VERSION ""

NS_ :

BS_:

BU_:

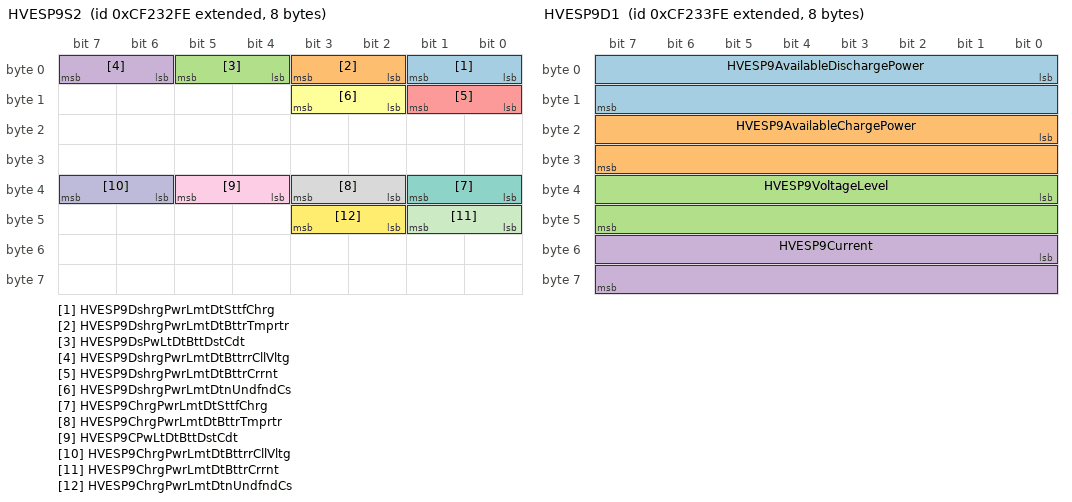
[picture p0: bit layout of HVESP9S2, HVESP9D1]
BO_ 2364683006 HVESP9S2: 8 Vector__XXX
 SG_ HVESP9DshrgPwrLmtDtSttfChrg : 0|2@1+ (1,0) [0|3] "" Vector__XXX
 SG_ HVESP9DshrgPwrLmtDtBttrTmprtr : 2|2@1+ (1,0) [0|3] "" Vector__XXX
 SG_ HVESP9DsPwLtDtBttDstCdt : 4|2@1+ (1,0) [0|3] "" Vector__XXX
 SG_ HVESP9DshrgPwrLmtDtBttrrCllVltg : 6|2@1+ (1,0) [0|3] "" Vector__XXX
 SG_ HVESP9DshrgPwrLmtDtBttrCrrnt : 8|2@1+ (1,0) [0|3] "" Vector__XXX
 SG_ HVESP9DshrgPwrLmtDtnUndfndCs : 10|2@1+ (1,0) [0|3] "" Vector__XXX
 SG_ HVESP9ChrgPwrLmtDtSttfChrg : 32|2@1+ (1,0) [0|3] "" Vector__XXX
 SG_ HVESP9ChrgPwrLmtDtBttrTmprtr : 34|2@1+ (1,0) [0|3] "" Vector__XXX
 SG_ HVESP9CPwLtDtBttDstCdt : 36|2@1+ (1,0) [0|3] "" Vector__XXX
 SG_ HVESP9ChrgPwrLmtDtBttrrCllVltg : 38|2@1+ (1,0) [0|3] "" Vector__XXX
 SG_ HVESP9ChrgPwrLmtDtBttrCrrnt : 40|2@1+ (1,0) [0|3] "" Vector__XXX
 SG_ HVESP9ChrgPwrLmtDtnUndfndCs : 42|2@1+ (1,0) [0|3] "" Vector__XXX

BO_ 2364683262 HVESP9D1: 8 Vector__XXX
 SG_ HVESP9AvailableDischargePower : 0|16@1+ (0.05,0) [0|3212.75] "kW" Vector__XXX
 SG_ HVESP9AvailableChargePower : 16|16@1+ (0.05,0) [0|3212.75] "kW" Vector__XXX
 SG_ HVESP9VoltageLevel : 32|16@1+ (0.05,0) [0|3212.75] "V" Vector__XXX
 SG_ HVESP9Current : 48|16@1+ (0.05,-1600) [-1600|1612.75] "A" Vector__XXX

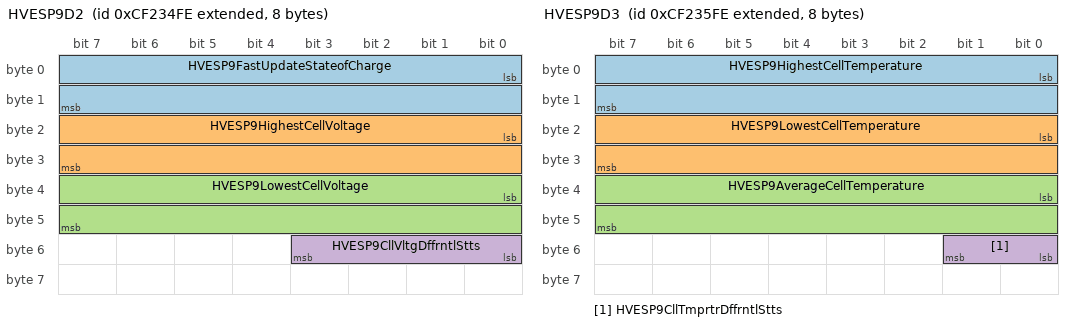
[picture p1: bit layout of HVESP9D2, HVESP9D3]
BO_ 2364683518 HVESP9D2: 8 Vector__XXX
 SG_ HVESP9FastUpdateStateofCharge : 0|16@1+ (0.0015625,0) [0|100.3984375] "%" Vector__XXX
 SG_ HVESP9HighestCellVoltage : 16|16@1+ (0.001,0) [0|64.255] "V" Vector__XXX
 SG_ HVESP9LowestCellVoltage : 32|16@1+ (0.001,0) [0|64.255] "V" Vector__XXX
 SG_ HVESP9CllVltgDffrntlStts : 48|4@1+ (1,0) [0|15] "" Vector__XXX

BO_ 2364683774 HVESP9D3: 8 Vector__XXX
 SG_ HVESP9HighestCellTemperature : 0|16@1+ (0.03125,-273) [-273|1734.96875] "degC" Vector__XXX
 SG_ HVESP9LowestCellTemperature : 16|16@1+ (0.03125,-273) [-273|1734.96875] "degC" Vector__XXX
 SG_ HVESP9AverageCellTemperature : 32|16@1+ (0.03125,-273) [-273|1734.96875] "degC" Vector__XXX
 SG_ HVESP9CllTmprtrDffrntlStts : 48|2@1+ (1,0) [0|3] "" Vector__XXX

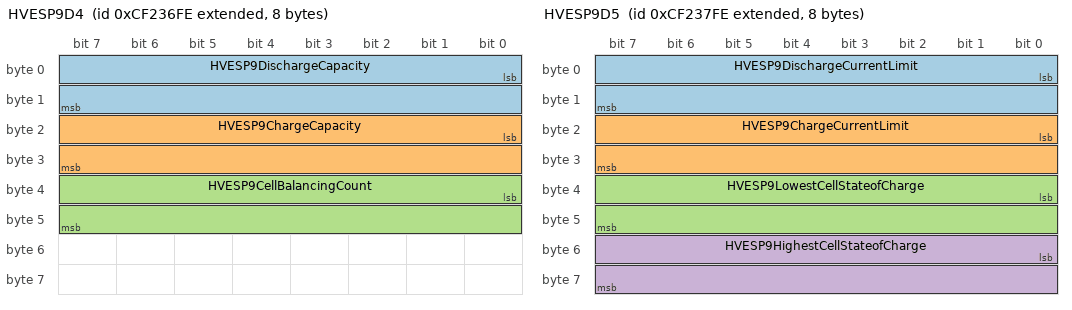
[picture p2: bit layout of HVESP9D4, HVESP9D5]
BO_ 2364684030 HVESP9D4: 8 Vector__XXX
 SG_ HVESP9DischargeCapacity : 0|16@1+ (0.01,0) [0|642.55] "Ah" Vector__XXX
 SG_ HVESP9ChargeCapacity : 16|16@1+ (0.01,0) [0|642.55] "Ah" Vector__XXX
 SG_ HVESP9CellBalancingCount : 32|16@1+ (1,0) [0|64255] "count" Vector__XXX

BO_ 2364684286 HVESP9D5: 8 Vector__XXX
 SG_ HVESP9DischargeCurrentLimit : 0|16@1+ (0.05,-1600) [-1600|1612.75] "A" Vector__XXX
 SG_ HVESP9ChargeCurrentLimit : 16|16@1+ (0.05,-1600) [-1600|1612.75] "A" Vector__XXX
 SG_ HVESP9LowestCellStateofCharge : 32|16@1+ (0.0015625,0) [0|100.3984375] "%" Vector__XXX
 SG_ HVESP9HighestCellStateofCharge : 48|16@1+ (0.0015625,0) [0|100.3984375] "%" Vector__XXX

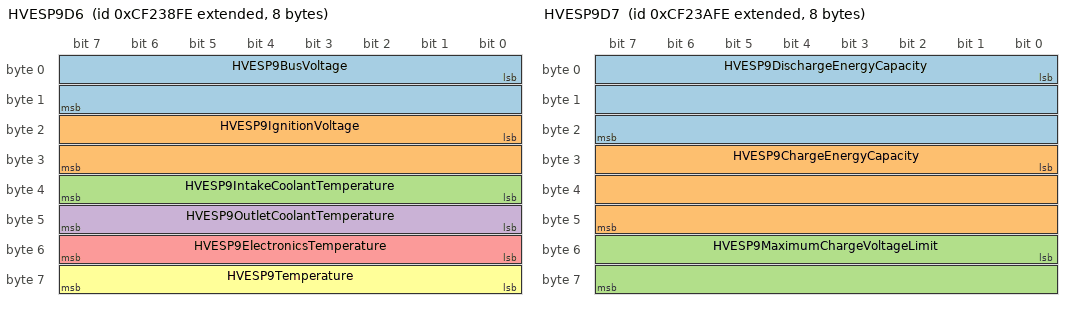
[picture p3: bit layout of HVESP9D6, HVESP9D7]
BO_ 2364684542 HVESP9D6: 8 Vector__XXX
 SG_ HVESP9BusVoltage : 0|16@1+ (0.05,0) [0|3212.75] "V" Vector__XXX
 SG_ HVESP9IgnitionVoltage : 16|16@1+ (0.01,0) [0|642.55] "V" Vector__XXX
 SG_ HVESP9IntakeCoolantTemperature : 32|8@1+ (1,-40) [-40|210] "degC" Vector__XXX
 SG_ HVESP9OutletCoolantTemperature : 40|8@1+ (1,-40) [-40|210] "degC" Vector__XXX
 SG_ HVESP9ElectronicsTemperature : 48|8@1+ (1,-40) [-40|210] "degC" Vector__XXX
 SG_ HVESP9Temperature : 56|8@1+ (1,-40) [-40|210] "degC" Vector__XXX

BO_ 2364684798 HVESP9S1: 8 Vector__XXX
 SG_ HVESP9HghVltgBsPstvCnttrStt : 0|2@1+ (1,0) [0|3] "" Vector__XXX
 SG_ HVESP9HghVltgBsNgtvCnttrStt : 2|2@1+ (1,0) [0|3] "" Vector__XXX
 SG_ HVESP9HghVltgBsDsnntFrwrnng : 4|4@1+ (1,0) [0|15] "" Vector__XXX
 SG_ HVESP9HghVltgBsPrChrgRlStt : 8|2@1+ (1,0) [0|3] "" Vector__XXX
 SG_ HVESP9CntrfPkCnttrStt : 10|2@1+ (1,0) [0|3] "" Vector__XXX
 SG_ HVESP9HghVltgBsAtvIsltnTstStts : 12|4@1+ (1,0) [0|15] "" Vector__XXX
 SG_ HVESP9HghVltgBsPssvIsltnTstStts : 16|4@1+ (1,0) [0|15] "" Vector__XXX
 SG_ HVESP9HVILStatus : 20|2@1+ (1,0) [0|3] "" Vector__XXX
 SG_ HVESP9InertiaSwitchStatus : 22|2@1+ (1,0) [0|3] "" Vector__XXX
 SG_ HVESP9StateofChargeStatus : 24|4@1+ (1,0) [0|15] "" Vector__XXX
 SG_ HVESP9CellBalanceStatus : 28|2@1+ (1,0) [0|3] "" Vector__XXX
 SG_ HVESP9CellBalancingActive : 30|2@1+ (1,0) [0|3] "" Vector__XXX
 SG_ HVESP9InternalChargerStatus : 32|2@1+ (1,0) [0|3] "" Vector__XXX
 SG_ HVESP9HghVltgBsCnntnStts : 40|4@1+ (1,0) [0|15] "" Vector__XXX
 SG_ HVESP9OperationalStatus : 44|4@1+ (1,0) [0|15] "" Vector__XXX
 SG_ HVESP9Status1Counter : 52|4@1+ (1,0) [0|15] "" Vector__XXX
 SG_ HVESP9Status1CRC : 56|8@1+ (1,0) [0|255] "count" Vector__XXX

BO_ 2364685054 HVESP9D7: 8 Vector__XXX
 SG_ HVESP9DischargeEnergyCapacity : 0|24@1+ (0.001,0) [0|16449.535] "kWh" Vector__XXX
 SG_ HVESP9ChargeEnergyCapacity : 24|24@1+ (0.001,0) [0|16449.535] "kWh" Vector__XXX
 SG_ HVESP9MaximumChargeVoltageLimit : 48|16@1+ (0.05,0) [0|3212.75] "V" Vector__XXX

BO_ 2364685310 HVESP9MS1: 8 Vector__XXX
 SG_ HVESP9Module1OperationalStatus : 0|2@1+ (1,0) [0|3] "" Vector__XXX
 SG_ HVESP9Module2OperationalStatus : 2|2@1+ (1,0) [0|3] "" Vector__XXX
 SG_ HVESP9Module3OperationalStatus : 4|2@1+ (1,0) [0|3] "" Vector__XXX
 SG_ HVESP9Module4OperationalStatus : 6|2@1+ (1,0) [0|3] "" Vector__XXX
 SG_ HVESP9Module5OperationalStatus : 8|2@1+ (1,0) [0|3] "" Vector__XXX
 SG_ HVESP9Module6OperationalStatus : 10|2@1+ (1,0) [0|3] "" Vector__XXX
 SG_ HVESP9Module7OperationalStatus : 12|2@1+ (1,0) [0|3] "" Vector__XXX
 SG_ HVESP9Module8OperationalStatus : 14|2@1+ (1,0) [0|3] "" Vector__XXX
 SG_ HVESP9Module9OperationalStatus : 16|2@1+ (1,0) [0|3] "" Vector__XXX
 SG_ HVESP9Module10OperationalStatus : 18|2@1+ (1,0) [0|3] "" Vector__XXX
 SG_ HVESP9Module11OperationalStatus : 20|2@1+ (1,0) [0|3] "" Vector__XXX
 SG_ HVESP9Module12OperationalStatus : 22|2@1+ (1,0) [0|3] "" Vector__XXX
 SG_ HVESP9Module13OperationalStatus : 24|2@1+ (1,0) [0|3] "" Vector__XXX
 SG_ HVESP9Module14OperationalStatus : 26|2@1+ (1,0) [0|3] "" Vector__XXX
 SG_ HVESP9Module15OperationalStatus : 28|2@1+ (1,0) [0|3] "" Vector__XXX
 SG_ HVESP9Module16OperationalStatus : 30|2@1+ (1,0) [0|3] "" Vector__XXX
 SG_ HVESP9Module17OperationalStatus : 32|2@1+ (1,0) [0|3] "" Vector__XXX
 SG_ HVESP9Module18OperationalStatus : 34|2@1+ (1,0) [0|3] "" Vector__XXX
 SG_ HVESP9Module19OperationalStatus : 36|2@1+ (1,0) [0|3] "" Vector__XXX
 SG_ HVESP9Module20OperationalStatus : 38|2@1+ (1,0) [0|3] "" Vector__XXX
 SG_ HVESP9Module21OperationalStatus : 40|2@1+ (1,0) [0|3] "" Vector__XXX
 SG_ HVESP9Module22OperationalStatus : 42|2@1+ (1,0) [0|3] "" Vector__XXX
 SG_ HVESP9Module23OperationalStatus : 44|2@1+ (1,0) [0|3] "" Vector__XXX
 SG_ HVESP9Module24OperationalStatus : 46|2@1+ (1,0) [0|3] "" Vector__XXX
 SG_ HVESP9Module25OperationalStatus : 48|2@1+ (1,0) [0|3] "" Vector__XXX
 SG_ HVESP9Module26OperationalStatus : 50|2@1+ (1,0) [0|3] "" Vector__XXX
 SG_ HVESP9Module27OperationalStatus : 52|2@1+ (1,0) [0|3] "" Vector__XXX
 SG_ HVESP9Module28OperationalStatus : 54|2@1+ (1,0) [0|3] "" Vector__XXX
 SG_ HVESP9Module29OperationalStatus : 56|2@1+ (1,0) [0|3] "" Vector__XXX
 SG_ HVESP9Module30OperationalStatus : 58|2@1+ (1,0) [0|3] "" Vector__XXX
 SG_ HVESP9Module31OperationalStatus : 60|2@1+ (1,0) [0|3] "" Vector__XXX
 SG_ HVESP9Module32OperationalStatus : 62|2@1+ (1,0) [0|3] "" Vector__XXX

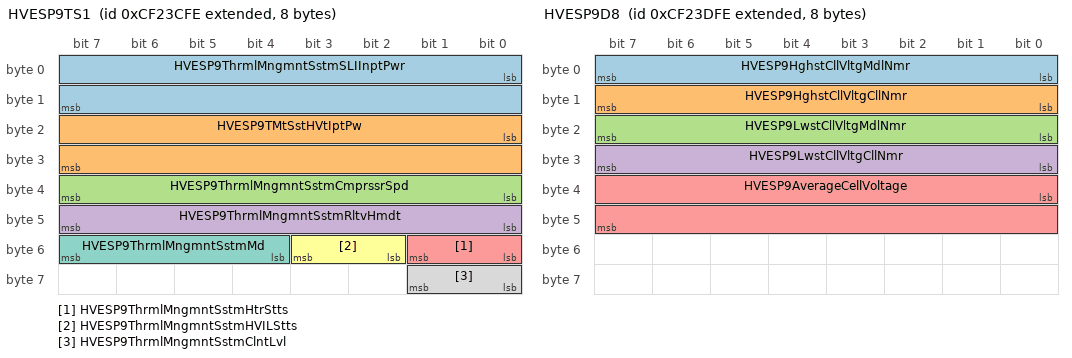
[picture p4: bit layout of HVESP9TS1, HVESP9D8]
BO_ 2364685566 HVESP9TS1: 8 Vector__XXX
 SG_ HVESP9ThrmlMngmntSstmSLIInptPwr : 0|16@1+ (0.5,0) [0|32127.5] "W" Vector__XXX
 SG_ HVESP9TMtSstHVtIptPw : 16|16@1+ (0.5,0) [0|32127.5] "W" Vector__XXX
 SG_ HVESP9ThrmlMngmntSstmCmprssrSpd : 32|8@1+ (32,0) [0|8000] "rpm" Vector__XXX
 SG_ HVESP9ThrmlMngmntSstmRltvHmdt : 40|8@1+ (0.4,0) [0|100] "%" Vector__XXX
 SG_ HVESP9ThrmlMngmntSstmHtrStts : 48|2@1+ (1,0) [0|3] "" Vector__XXX
 SG_ HVESP9ThrmlMngmntSstmHVILStts : 50|2@1+ (1,0) [0|3] "" Vector__XXX
 SG_ HVESP9ThrmlMngmntSstmMd : 52|4@1+ (1,0) [0|15] "" Vector__XXX
 SG_ HVESP9ThrmlMngmntSstmClntLvl : 56|2@1+ (1,0) [0|3] "" Vector__XXX

BO_ 2364685822 HVESP9D8: 8 Vector__XXX
 SG_ HVESP9HghstCllVltgMdlNmr : 0|8@1+ (1,0) [0|250] "count" Vector__XXX
 SG_ HVESP9HghstCllVltgCllNmr : 8|8@1+ (1,0) [0|250] "count" Vector__XXX
 SG_ HVESP9LwstCllVltgMdlNmr : 16|8@1+ (1,0) [0|250] "count" Vector__XXX
 SG_ HVESP9LwstCllVltgCllNmr : 24|8@1+ (1,0) [0|250] "count" Vector__XXX
 SG_ HVESP9AverageCellVoltage : 32|16@1+ (0.001,0) [0|64.255] "V" Vector__XXX

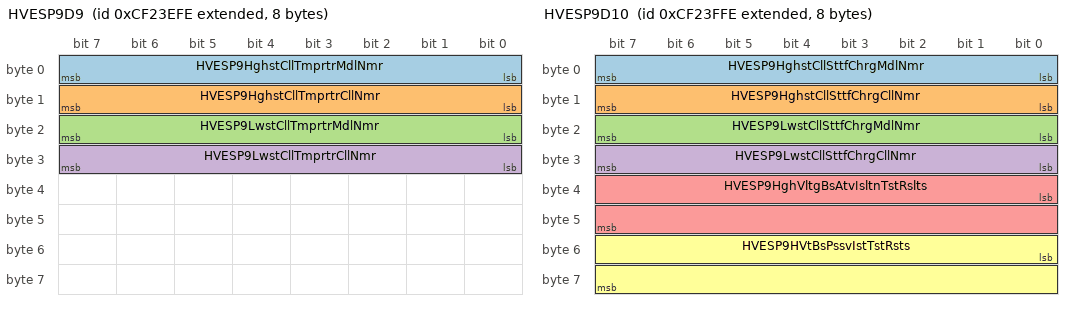
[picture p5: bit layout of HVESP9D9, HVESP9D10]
BO_ 2364686078 HVESP9D9: 8 Vector__XXX
 SG_ HVESP9HghstCllTmprtrMdlNmr : 0|8@1+ (1,0) [0|250] "count" Vector__XXX
 SG_ HVESP9HghstCllTmprtrCllNmr : 8|8@1+ (1,0) [0|250] "count" Vector__XXX
 SG_ HVESP9LwstCllTmprtrMdlNmr : 16|8@1+ (1,0) [0|250] "count" Vector__XXX
 SG_ HVESP9LwstCllTmprtrCllNmr : 24|8@1+ (1,0) [0|250] "count" Vector__XXX

BO_ 2364686334 HVESP9D10: 8 Vector__XXX
 SG_ HVESP9HghstCllSttfChrgMdlNmr : 0|8@1+ (1,0) [0|250] "count" Vector__XXX
 SG_ HVESP9HghstCllSttfChrgCllNmr : 8|8@1+ (1,0) [0|250] "count" Vector__XXX
 SG_ HVESP9LwstCllSttfChrgMdlNmr : 16|8@1+ (1,0) [0|250] "count" Vector__XXX
 SG_ HVESP9LwstCllSttfChrgCllNmr : 24|8@1+ (1,0) [0|250] "count" Vector__XXX
 SG_ HVESP9HghVltgBsAtvIsltnTstRslts : 32|16@1+ (0.1,0) [0|6425.5] "ohm/V" Vector__XXX
 SG_ HVESP9HVtBsPssvIstTstRsts : 48|16@1+ (0.1,0) [0|6425.5] "ohm/V" Vector__XXX

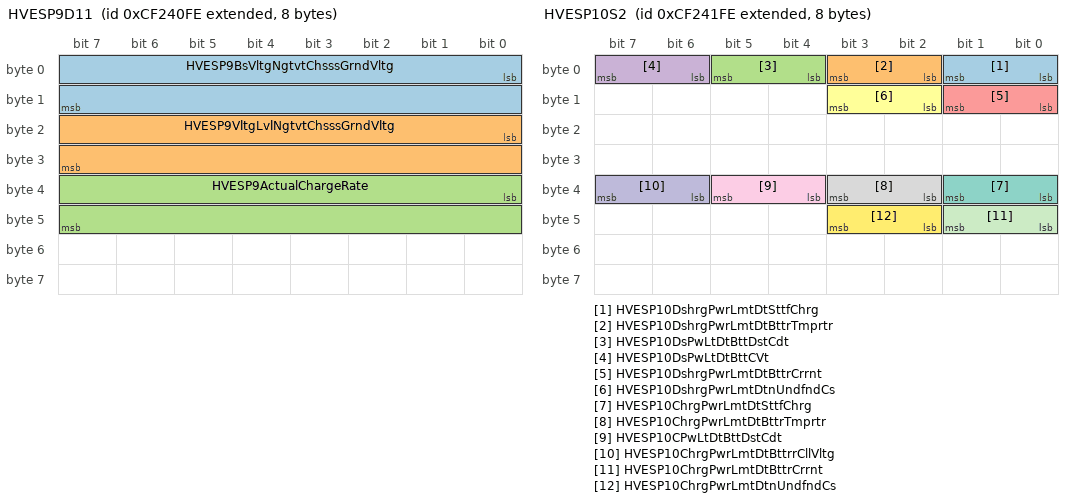
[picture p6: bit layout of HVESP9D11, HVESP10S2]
BO_ 2364686590 HVESP9D11: 8 Vector__XXX
 SG_ HVESP9BsVltgNgtvtChsssGrndVltg : 0|16@1+ (0.05,0) [0|3212.75] "V" Vector__XXX
 SG_ HVESP9VltgLvlNgtvtChsssGrndVltg : 16|16@1+ (0.05,0) [0|3212.75] "V" Vector__XXX
 SG_ HVESP9ActualChargeRate : 32|16@1+ (0.05,0) [0|3212.75] "kW" Vector__XXX

BO_ 2364686846 HVESP10S2: 8 Vector__XXX
 SG_ HVESP10DshrgPwrLmtDtSttfChrg : 0|2@1+ (1,0) [0|3] "" Vector__XXX
 SG_ HVESP10DshrgPwrLmtDtBttrTmprtr : 2|2@1+ (1,0) [0|3] "" Vector__XXX
 SG_ HVESP10DsPwLtDtBttDstCdt : 4|2@1+ (1,0) [0|3] "" Vector__XXX
 SG_ HVESP10DsPwLtDtBttCVt : 6|2@1+ (1,0) [0|3] "" Vector__XXX
 SG_ HVESP10DshrgPwrLmtDtBttrCrrnt : 8|2@1+ (1,0) [0|3] "" Vector__XXX
 SG_ HVESP10DshrgPwrLmtDtnUndfndCs : 10|2@1+ (1,0) [0|3] "" Vector__XXX
 SG_ HVESP10ChrgPwrLmtDtSttfChrg : 32|2@1+ (1,0) [0|3] "" Vector__XXX
 SG_ HVESP10ChrgPwrLmtDtBttrTmprtr : 34|2@1+ (1,0) [0|3] "" Vector__XXX
 SG_ HVESP10CPwLtDtBttDstCdt : 36|2@1+ (1,0) [0|3] "" Vector__XXX
 SG_ HVESP10ChrgPwrLmtDtBttrrCllVltg : 38|2@1+ (1,0) [0|3] "" Vector__XXX
 SG_ HVESP10ChrgPwrLmtDtBttrCrrnt : 40|2@1+ (1,0) [0|3] "" Vector__XXX
 SG_ HVESP10ChrgPwrLmtDtnUndfndCs : 42|2@1+ (1,0) [0|3] "" Vector__XXX

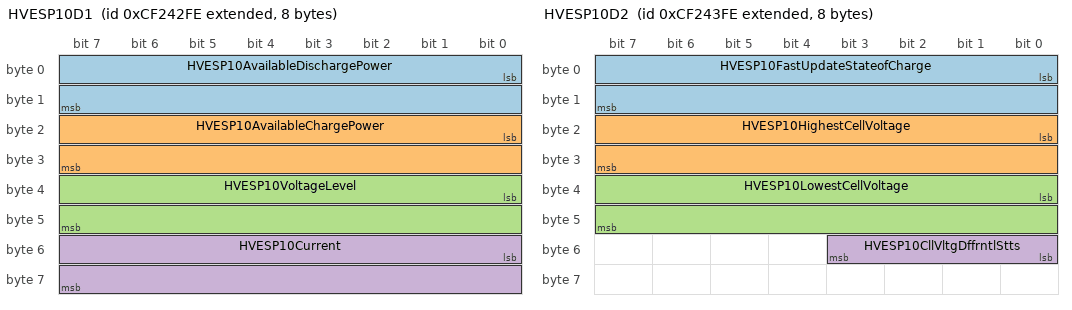
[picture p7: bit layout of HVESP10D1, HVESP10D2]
BO_ 2364687102 HVESP10D1: 8 Vector__XXX
 SG_ HVESP10AvailableDischargePower : 0|16@1+ (0.05,0) [0|3212.75] "kW" Vector__XXX
 SG_ HVESP10AvailableChargePower : 16|16@1+ (0.05,0) [0|3212.75] "kW" Vector__XXX
 SG_ HVESP10VoltageLevel : 32|16@1+ (0.05,0) [0|3212.75] "V" Vector__XXX
 SG_ HVESP10Current : 48|16@1+ (0.05,-1600) [-1600|1612.75] "A" Vector__XXX

BO_ 2364687358 HVESP10D2: 8 Vector__XXX
 SG_ HVESP10FastUpdateStateofCharge : 0|16@1+ (0.0015625,0) [0|100.3984375] "%" Vector__XXX
 SG_ HVESP10HighestCellVoltage : 16|16@1+ (0.001,0) [0|64.255] "V" Vector__XXX
 SG_ HVESP10LowestCellVoltage : 32|16@1+ (0.001,0) [0|64.255] "V" Vector__XXX
 SG_ HVESP10CllVltgDffrntlStts : 48|4@1+ (1,0) [0|15] "" Vector__XXX

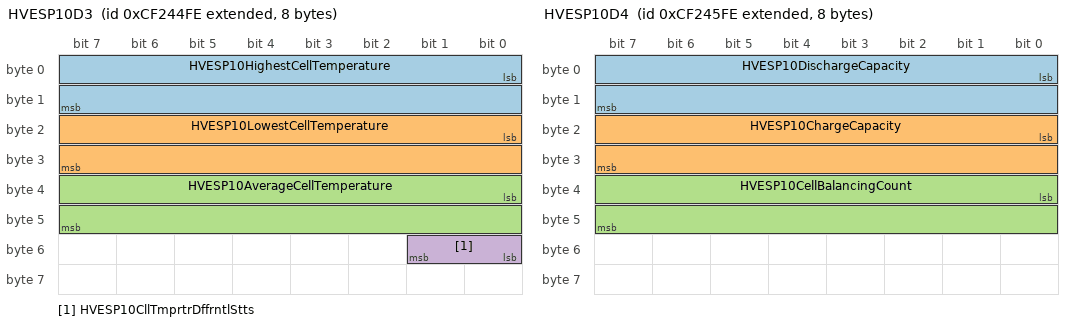
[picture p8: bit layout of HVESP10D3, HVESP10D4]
BO_ 2364687614 HVESP10D3: 8 Vector__XXX
 SG_ HVESP10HighestCellTemperature : 0|16@1+ (0.03125,-273) [-273|1734.96875] "degC" Vector__XXX
 SG_ HVESP10LowestCellTemperature : 16|16@1+ (0.03125,-273) [-273|1734.96875] "degC" Vector__XXX
 SG_ HVESP10AverageCellTemperature : 32|16@1+ (0.03125,-273) [-273|1734.96875] "degC" Vector__XXX
 SG_ HVESP10CllTmprtrDffrntlStts : 48|2@1+ (1,0) [0|3] "" Vector__XXX

BO_ 2364687870 HVESP10D4: 8 Vector__XXX
 SG_ HVESP10DischargeCapacity : 0|16@1+ (0.01,0) [0|642.55] "Ah" Vector__XXX
 SG_ HVESP10ChargeCapacity : 16|16@1+ (0.01,0) [0|642.55] "Ah" Vector__XXX
 SG_ HVESP10CellBalancingCount : 32|16@1+ (1,0) [0|64255] "count" Vector__XXX

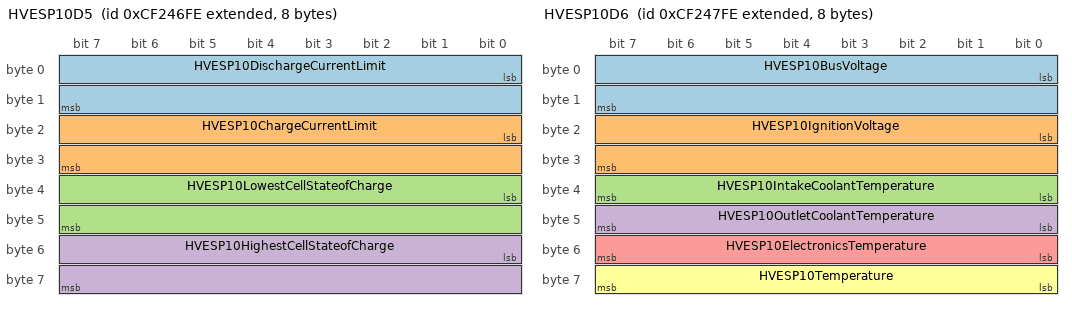
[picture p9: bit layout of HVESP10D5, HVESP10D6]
BO_ 2364688126 HVESP10D5: 8 Vector__XXX
 SG_ HVESP10DischargeCurrentLimit : 0|16@1+ (0.05,-1600) [-1600|1612.75] "A" Vector__XXX
 SG_ HVESP10ChargeCurrentLimit : 16|16@1+ (0.05,-1600) [-1600|1612.75] "A" Vector__XXX
 SG_ HVESP10LowestCellStateofCharge : 32|16@1+ (0.0015625,0) [0|100.3984375] "%" Vector__XXX
 SG_ HVESP10HighestCellStateofCharge : 48|16@1+ (0.0015625,0) [0|100.3984375] "%" Vector__XXX

BO_ 2364688382 HVESP10D6: 8 Vector__XXX
 SG_ HVESP10BusVoltage : 0|16@1+ (0.05,0) [0|3212.75] "V" Vector__XXX
 SG_ HVESP10IgnitionVoltage : 16|16@1+ (0.01,0) [0|642.55] "V" Vector__XXX
 SG_ HVESP10IntakeCoolantTemperature : 32|8@1+ (1,-40) [-40|210] "degC" Vector__XXX
 SG_ HVESP10OutletCoolantTemperature : 40|8@1+ (1,-40) [-40|210] "degC" Vector__XXX
 SG_ HVESP10ElectronicsTemperature : 48|8@1+ (1,-40) [-40|210] "degC" Vector__XXX
 SG_ HVESP10Temperature : 56|8@1+ (1,-40) [-40|210] "degC" Vector__XXX

BO_ 2364688638 HVESP10S1: 8 Vector__XXX
 SG_ HVESP10HghVltgBsPstvCnttrStt : 0|2@1+ (1,0) [0|3] "" Vector__XXX
 SG_ HVESP10HghVltgBsNgtvCnttrStt : 2|2@1+ (1,0) [0|3] "" Vector__XXX
 SG_ HVESP10HghVltgBsDsnntFrwrnng : 4|4@1+ (1,0) [0|15] "" Vector__XXX
 SG_ HVESP10HghVltgBsPrChrgRlStt : 8|2@1+ (1,0) [0|3] "" Vector__XXX
 SG_ HVESP10CntrfPkCnttrStt : 10|2@1+ (1,0) [0|3] "" Vector__XXX
 SG_ HVESP10HghVltgBsAtvIsltnTstStts : 12|4@1+ (1,0) [0|15] "" Vector__XXX
 SG_ HVESP10HVtBsPssvIstTstStts : 16|4@1+ (1,0) [0|15] "" Vector__XXX
 SG_ HVESP10HVILStatus : 20|2@1+ (1,0) [0|3] "" Vector__XXX
 SG_ HVESP10InertiaSwitchStatus : 22|2@1+ (1,0) [0|3] "" Vector__XXX
 SG_ HVESP10StateofChargeStatus : 24|4@1+ (1,0) [0|15] "" Vector__XXX
 SG_ HVESP10CellBalanceStatus : 28|2@1+ (1,0) [0|3] "" Vector__XXX
 SG_ HVESP10CellBalancingActive : 30|2@1+ (1,0) [0|3] "" Vector__XXX
 SG_ HVESP10InternalChargerStatus : 32|2@1+ (1,0) [0|3] "" Vector__XXX
 SG_ HVESP10HghVltgBsCnntnStts : 40|4@1+ (1,0) [0|15] "" Vector__XXX
 SG_ HVESP10OperationalStatus : 44|4@1+ (1,0) [0|15] "" Vector__XXX
 SG_ HVESP10Status1Counter : 52|4@1+ (1,0) [0|15] "" Vector__XXX
 SG_ HVESP10Status1CRC : 56|8@1+ (1,0) [0|255] "count" Vector__XXX

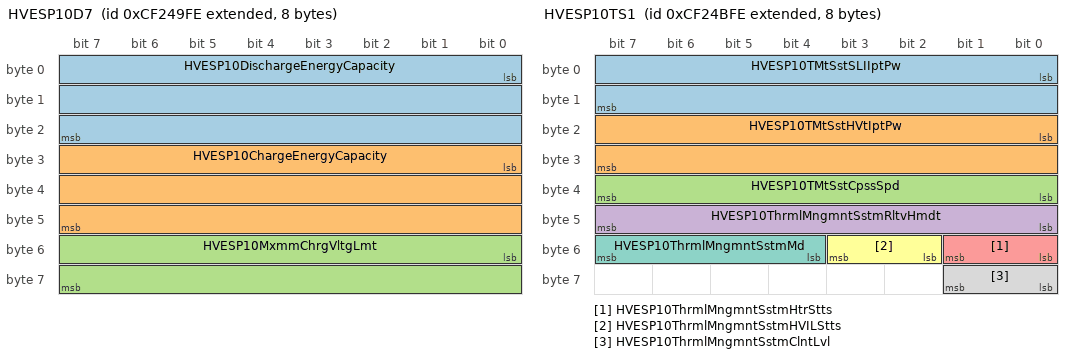
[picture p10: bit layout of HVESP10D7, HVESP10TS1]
BO_ 2364688894 HVESP10D7: 8 Vector__XXX
 SG_ HVESP10DischargeEnergyCapacity : 0|24@1+ (0.001,0) [0|16449.535] "kWh" Vector__XXX
 SG_ HVESP10ChargeEnergyCapacity : 24|24@1+ (0.001,0) [0|16449.535] "kWh" Vector__XXX
 SG_ HVESP10MxmmChrgVltgLmt : 48|16@1+ (0.05,0) [0|3212.75] "V" Vector__XXX

BO_ 2364689150 HVESP10MS1: 8 Vector__XXX
 SG_ HVESP10Module1OperationalStatus : 0|2@1+ (1,0) [0|3] "" Vector__XXX
 SG_ HVESP10Module2OperationalStatus : 2|2@1+ (1,0) [0|3] "" Vector__XXX
 SG_ HVESP10Module3OperationalStatus : 4|2@1+ (1,0) [0|3] "" Vector__XXX
 SG_ HVESP10Module4OperationalStatus : 6|2@1+ (1,0) [0|3] "" Vector__XXX
 SG_ HVESP10Module5OperationalStatus : 8|2@1+ (1,0) [0|3] "" Vector__XXX
 SG_ HVESP10Module6OperationalStatus : 10|2@1+ (1,0) [0|3] "" Vector__XXX
 SG_ HVESP10Module7OperationalStatus : 12|2@1+ (1,0) [0|3] "" Vector__XXX
 SG_ HVESP10Module8OperationalStatus : 14|2@1+ (1,0) [0|3] "" Vector__XXX
 SG_ HVESP10Module9OperationalStatus : 16|2@1+ (1,0) [0|3] "" Vector__XXX
 SG_ HVESP10Mdl10OprtnlStts : 18|2@1+ (1,0) [0|3] "" Vector__XXX
 SG_ HVESP10Mdl11OprtnlStts : 20|2@1+ (1,0) [0|3] "" Vector__XXX
 SG_ HVESP10Mdl12OprtnlStts : 22|2@1+ (1,0) [0|3] "" Vector__XXX
 SG_ HVESP10Mdl13OprtnlStts : 24|2@1+ (1,0) [0|3] "" Vector__XXX
 SG_ HVESP10Mdl14OprtnlStts : 26|2@1+ (1,0) [0|3] "" Vector__XXX
 SG_ HVESP10Mdl15OprtnlStts : 28|2@1+ (1,0) [0|3] "" Vector__XXX
 SG_ HVESP10Mdl16OprtnlStts : 30|2@1+ (1,0) [0|3] "" Vector__XXX
 SG_ HVESP10Mdl17OprtnlStts : 32|2@1+ (1,0) [0|3] "" Vector__XXX
 SG_ HVESP10Mdl18OprtnlStts : 34|2@1+ (1,0) [0|3] "" Vector__XXX
 SG_ HVESP10Mdl19OprtnlStts : 36|2@1+ (1,0) [0|3] "" Vector__XXX
 SG_ HVESP10Mdl20OprtnlStts : 38|2@1+ (1,0) [0|3] "" Vector__XXX
 SG_ HVESP10Mdl21OprtnlStts : 40|2@1+ (1,0) [0|3] "" Vector__XXX
 SG_ HVESP10Mdl22OprtnlStts : 42|2@1+ (1,0) [0|3] "" Vector__XXX
 SG_ HVESP10Mdl23OprtnlStts : 44|2@1+ (1,0) [0|3] "" Vector__XXX
 SG_ HVESP10Mdl24OprtnlStts : 46|2@1+ (1,0) [0|3] "" Vector__XXX
 SG_ HVESP10Mdl25OprtnlStts : 48|2@1+ (1,0) [0|3] "" Vector__XXX
 SG_ HVESP10Mdl26OprtnlStts : 50|2@1+ (1,0) [0|3] "" Vector__XXX
 SG_ HVESP10Mdl27OprtnlStts : 52|2@1+ (1,0) [0|3] "" Vector__XXX
 SG_ HVESP10Mdl28OprtnlStts : 54|2@1+ (1,0) [0|3] "" Vector__XXX
 SG_ HVESP10Mdl29OprtnlStts : 56|2@1+ (1,0) [0|3] "" Vector__XXX
 SG_ HVESP10Mdl30OprtnlStts : 58|2@1+ (1,0) [0|3] "" Vector__XXX
 SG_ HVESP10Mdl31OprtnlStts : 60|2@1+ (1,0) [0|3] "" Vector__XXX
 SG_ HVESP10Mdl32OprtnlStts : 62|2@1+ (1,0) [0|3] "" Vector__XXX

BO_ 2364689406 HVESP10TS1: 8 Vector__XXX
 SG_ HVESP10TMtSstSLIIptPw : 0|16@1+ (0.5,0) [0|32127.5] "W" Vector__XXX
 SG_ HVESP10TMtSstHVtIptPw : 16|16@1+ (0.5,0) [0|32127.5] "W" Vector__XXX
 SG_ HVESP10TMtSstCpssSpd : 32|8@1+ (32,0) [0|8000] "rpm" Vector__XXX
 SG_ HVESP10ThrmlMngmntSstmRltvHmdt : 40|8@1+ (0.4,0) [0|100] "%" Vector__XXX
 SG_ HVESP10ThrmlMngmntSstmHtrStts : 48|2@1+ (1,0) [0|3] "" Vector__XXX
 SG_ HVESP10ThrmlMngmntSstmHVILStts : 50|2@1+ (1,0) [0|3] "" Vector__XXX
 SG_ HVESP10ThrmlMngmntSstmMd : 52|4@1+ (1,0) [0|15] "" Vector__XXX
 SG_ HVESP10ThrmlMngmntSstmClntLvl : 56|2@1+ (1,0) [0|3] "" Vector__XXX

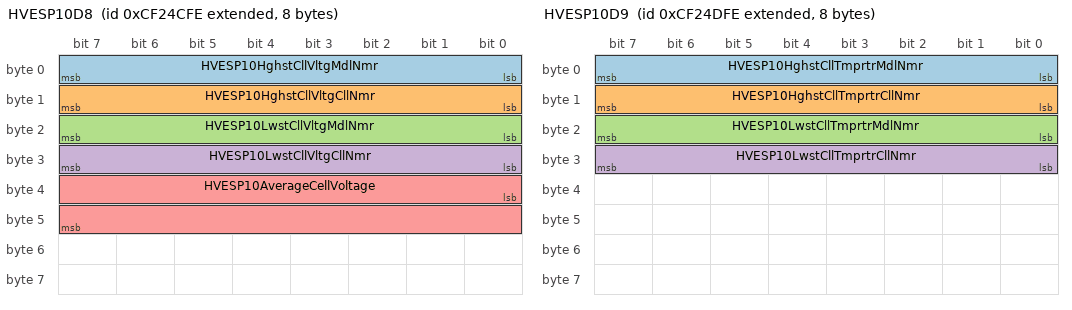
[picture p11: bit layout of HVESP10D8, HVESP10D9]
BO_ 2364689662 HVESP10D8: 8 Vector__XXX
 SG_ HVESP10HghstCllVltgMdlNmr : 0|8@1+ (1,0) [0|250] "count" Vector__XXX
 SG_ HVESP10HghstCllVltgCllNmr : 8|8@1+ (1,0) [0|250] "count" Vector__XXX
 SG_ HVESP10LwstCllVltgMdlNmr : 16|8@1+ (1,0) [0|250] "count" Vector__XXX
 SG_ HVESP10LwstCllVltgCllNmr : 24|8@1+ (1,0) [0|250] "count" Vector__XXX
 SG_ HVESP10AverageCellVoltage : 32|16@1+ (0.001,0) [0|64.255] "V" Vector__XXX

BO_ 2364689918 HVESP10D9: 8 Vector__XXX
 SG_ HVESP10HghstCllTmprtrMdlNmr : 0|8@1+ (1,0) [0|250] "count" Vector__XXX
 SG_ HVESP10HghstCllTmprtrCllNmr : 8|8@1+ (1,0) [0|250] "count" Vector__XXX
 SG_ HVESP10LwstCllTmprtrMdlNmr : 16|8@1+ (1,0) [0|250] "count" Vector__XXX
 SG_ HVESP10LwstCllTmprtrCllNmr : 24|8@1+ (1,0) [0|250] "count" Vector__XXX

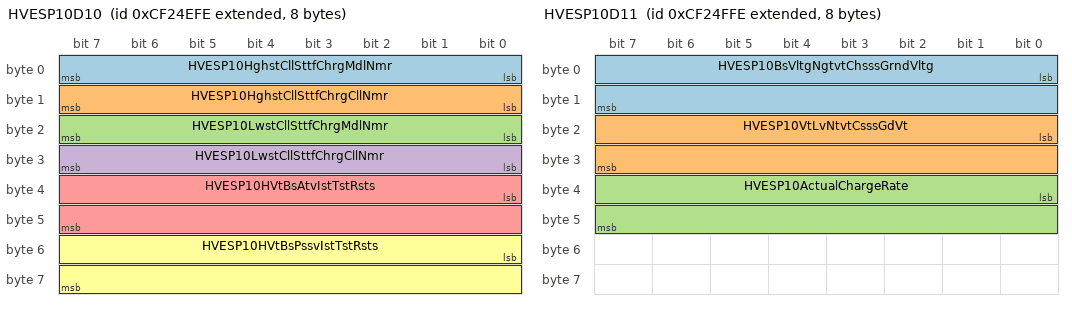
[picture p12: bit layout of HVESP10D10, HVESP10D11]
BO_ 2364690174 HVESP10D10: 8 Vector__XXX
 SG_ HVESP10HghstCllSttfChrgMdlNmr : 0|8@1+ (1,0) [0|250] "count" Vector__XXX
 SG_ HVESP10HghstCllSttfChrgCllNmr : 8|8@1+ (1,0) [0|250] "count" Vector__XXX
 SG_ HVESP10LwstCllSttfChrgMdlNmr : 16|8@1+ (1,0) [0|250] "count" Vector__XXX
 SG_ HVESP10LwstCllSttfChrgCllNmr : 24|8@1+ (1,0) [0|250] "count" Vector__XXX
 SG_ HVESP10HVtBsAtvIstTstRsts : 32|16@1+ (0.1,0) [0|6425.5] "ohm/V" Vector__XXX
 SG_ HVESP10HVtBsPssvIstTstRsts : 48|16@1+ (0.1,0) [0|6425.5] "ohm/V" Vector__XXX

BO_ 2364690430 HVESP10D11: 8 Vector__XXX
 SG_ HVESP10BsVltgNgtvtChsssGrndVltg : 0|16@1+ (0.05,0) [0|3212.75] "V" Vector__XXX
 SG_ HVESP10VtLvNtvtCsssGdVt : 16|16@1+ (0.05,0) [0|3212.75] "V" Vector__XXX
 SG_ HVESP10ActualChargeRate : 32|16@1+ (0.05,0) [0|3212.75] "kW" Vector__XXX

BO_ 2566564862 HVESP10CFG: 16 Vector__XXX
 SG_ HVESP10NominalVoltage : 0|16@1+ (0.05,0) [0|3212.75] "V" Vector__XXX
 SG_ HVESP10RmmnddMnmmOprtngVltg : 16|16@1+ (0.05,0) [0|3212.75] "V" Vector__XXX
 SG_ HVESP10RmmnddMxmmOprtngVltg : 32|16@1+ (0.05,0) [0|3212.75] "V" Vector__XXX
 SG_ HVESP10RmmnddMnmmSttOfChrg : 48|16@1+ (0.0015625,0) [0|100.3984375] "%" Vector__XXX
 SG_ HVESP10RmmnddMxmmSttOfChrg : 64|16@1+ (0.0015625,0) [0|100.3984375] "%" Vector__XXX
 SG_ HVESP10RmmnddMxmmOprtngTmprtr : 80|16@1+ (0.03125,-273) [-273|1734.96875] "degC" Vector__XXX
 SG_ HVESP10RmmnddMnmmOprtngTmprtr : 96|16@1+ (0.03125,-273) [-273|1734.96875] "degC" Vector__XXX
 SG_ HVESP10CellMaximumVoltageLimit : 112|8@1+ (0.02044,0) [0|5.11] "V" Vector__XXX
 SG_ HVESP10CellMinimumVoltageLimit : 120|8@1+ (0.02044,0) [0|5.11] "V" Vector__XXX

BO_ 2633673982 HVESP10HIST: 19 Vector__XXX
 SG_ HVESP10StateofHealth : 0|8@1+ (0.4,0) [0|100] "%" Vector__XXX
 SG_ HVESP10CnttrOpnUndrLdCnt : 8|16@1+ (1,0) [0|64255] "count" Vector__XXX
 SG_ HVESP10TotalEnergyThroughput : 24|32@1+ (100,0) [0|421108121500] "Watt-hour" Vector__XXX
 SG_ HVESP10TotalAccumulatedCharge : 56|32@1+ (100,0) [0|421108121500] "Ah" Vector__XXX
 SG_ HVESP10TotalLifetimeEnergyInput : 88|32@1+ (1,0) [0|4211081215] "kWh" Vector__XXX
 SG_ HVESP10TtlLftmEnrgOtpt : 120|32@1+ (1,0) [0|4211081215] "kWh" Vector__XXX

BO_ 2566565374 HVESP9CFG: 16 Vector__XXX
 SG_ HVESP9NominalVoltage : 0|16@1+ (0.05,0) [0|3212.75] "V" Vector__XXX
 SG_ HVESP9RmmnddMnmmOprtngVltg : 16|16@1+ (0.05,0) [0|3212.75] "V" Vector__XXX
 SG_ HVESP9RmmnddMxmmOprtngVltg : 32|16@1+ (0.05,0) [0|3212.75] "V" Vector__XXX
 SG_ HVESP9RmmnddMnmmSttOfChrg : 48|16@1+ (0.0015625,0) [0|100.3984375] "%" Vector__XXX
 SG_ HVESP9RmmnddMxmmSttOfChrg : 64|16@1+ (0.0015625,0) [0|100.3984375] "%" Vector__XXX
 SG_ HVESP9RmmnddMxmmOprtngTmprtr : 80|16@1+ (0.03125,-273) [-273|1734.96875] "degC" Vector__XXX
 SG_ HVESP9RmmnddMnmmOprtngTmprtr : 96|16@1+ (0.03125,-273) [-273|1734.96875] "degC" Vector__XXX
 SG_ HVESP9CellMaximumVoltageLimit : 112|8@1+ (0.02044,0) [0|5.11] "V" Vector__XXX
 SG_ HVESP9CellMinimumVoltageLimit : 120|8@1+ (0.02044,0) [0|5.11] "V" Vector__XXX

BO_ 2633674494 HVESP9HIST: 19 Vector__XXX
 SG_ HVESP9StateofHealth : 0|8@1+ (0.4,0) [0|100] "%" Vector__XXX
 SG_ HVESP9CnttrOpnUndrLdCnt : 8|16@1+ (1,0) [0|64255] "count" Vector__XXX
 SG_ HVESP9TotalEnergyThroughput : 24|32@1+ (100,0) [0|421108121500] "Watt-hour" Vector__XXX
 SG_ HVESP9TotalAccumulatedCharge : 56|32@1+ (100,0) [0|421108121500] "Ah" Vector__XXX
 SG_ HVESP9TotalLifetimeEnergyInput : 88|32@1+ (1,0) [0|4211081215] "kWh" Vector__XXX
 SG_ HVESP9TotalLifetimeEnergyOutput : 120|32@1+ (1,0) [0|4211081215] "kWh" Vector__XXX

BO_ 2566565886 HVESP8CFG: 16 Vector__XXX
 SG_ HVESP8NominalVoltage : 0|16@1+ (0.05,0) [0|3212.75] "V" Vector__XXX
 SG_ HVESP8RmmnddMnmmOprtngVltg : 16|16@1+ (0.05,0) [0|3212.75] "V" Vector__XXX
 SG_ HVESP8RmmnddMxmmOprtngVltg : 32|16@1+ (0.05,0) [0|3212.75] "V" Vector__XXX
 SG_ HVESP8RmmnddMnmmSttOfChrg : 48|16@1+ (0.0015625,0) [0|100.3984375] "%" Vector__XXX
 SG_ HVESP8RmmnddMxmmSttOfChrg : 64|16@1+ (0.0015625,0) [0|100.3984375] "%" Vector__XXX
 SG_ HVESP8RmmnddMxmmOprtngTmprtr : 80|16@1+ (0.03125,-273) [-273|1734.96875] "degC" Vector__XXX
 SG_ HVESP8RmmnddMnmmOprtngTmprtr : 96|16@1+ (0.03125,-273) [-273|1734.96875] "degC" Vector__XXX
 SG_ HVESP8CellMaximumVoltageLimit : 112|8@1+ (0.02044,0) [0|5.11] "V" Vector__XXX
 SG_ HVESP8CellMinimumVoltageLimit : 120|8@1+ (0.02044,0) [0|5.11] "V" Vector__XXX

BO_ 2633675006 HVESP8HIST: 19 Vector__XXX
 SG_ HVESP8StateofHealth : 0|8@1+ (0.4,0) [0|100] "%" Vector__XXX
 SG_ HVESP8CnttrOpnUndrLdCnt : 8|16@1+ (1,0) [0|64255] "count" Vector__XXX
 SG_ HVESP8TotalEnergyThroughput : 24|32@1+ (100,0) [0|421108121500] "Watt-hour" Vector__XXX
 SG_ HVESP8TotalAccumulatedCharge : 56|32@1+ (100,0) [0|421108121500] "Ah" Vector__XXX
 SG_ HVESP8TotalLifetimeEnergyInput : 88|32@1+ (1,0) [0|4211081215] "kWh" Vector__XXX
 SG_ HVESP8TotalLifetimeEnergyOutput : 120|32@1+ (1,0) [0|4211081215] "kWh" Vector__XXX

BO_ 2566566398 HVESP7CFG: 16 Vector__XXX
 SG_ HVESP7NominalVoltage : 0|16@1+ (0.05,0) [0|3212.75] "V" Vector__XXX
 SG_ HVESP7RmmnddMnmmOprtngVltg : 16|16@1+ (0.05,0) [0|3212.75] "V" Vector__XXX
 SG_ HVESP7RmmnddMxmmOprtngVltg : 32|16@1+ (0.05,0) [0|3212.75] "V" Vector__XXX
 SG_ HVESP7RmmnddMnmmSttOfChrg : 48|16@1+ (0.0015625,0) [0|100.3984375] "%" Vector__XXX
 SG_ HVESP7RmmnddMxmmSttOfChrg : 64|16@1+ (0.0015625,0) [0|100.3984375] "%" Vector__XXX
 SG_ HVESP7RmmnddMxmmOprtngTmprtr : 80|16@1+ (0.03125,-273) [-273|1734.96875] "degC" Vector__XXX
 SG_ HVESP7RmmnddMnmmOprtngTmprtr : 96|16@1+ (0.03125,-273) [-273|1734.96875] "degC" Vector__XXX
 SG_ HVESP7CellMaximumVoltageLimit : 112|8@1+ (0.02044,0) [0|5.11] "V" Vector__XXX
 SG_ HVESP7CellMinimumVoltageLimit : 120|8@1+ (0.02044,0) [0|5.11] "V" Vector__XXX

BO_ 2633675518 HVESP7HIST: 19 Vector__XXX
 SG_ HVESP7StateofHealth : 0|8@1+ (0.4,0) [0|100] "%" Vector__XXX
 SG_ HVESP7CnttrOpnUndrLdCnt : 8|16@1+ (1,0) [0|64255] "count" Vector__XXX
 SG_ HVESP7TotalEnergyThroughput : 24|32@1+ (100,0) [0|421108121500] "Watt-hour" Vector__XXX
 SG_ HVESP7TotalAccumulatedCharge : 56|32@1+ (100,0) [0|421108121500] "Ah" Vector__XXX
 SG_ HVESP7TotalLifetimeEnergyInput : 88|32@1+ (1,0) [0|4211081215] "kWh" Vector__XXX
 SG_ HVESP7TotalLifetimeEnergyOutput : 120|32@1+ (1,0) [0|4211081215] "kWh" Vector__XXX

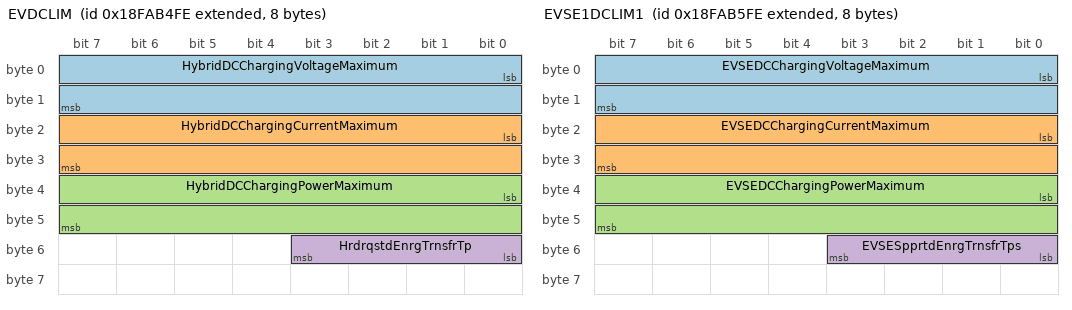
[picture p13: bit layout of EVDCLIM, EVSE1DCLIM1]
BO_ 2566567166 EVDCLIM: 8 Vector__XXX
 SG_ HybridDCChargingVoltageMaximum : 0|16@1+ (0.05,0) [0|3212.75] "V" Vector__XXX
 SG_ HybridDCChargingCurrentMaximum : 16|16@1+ (0.0625,0) [0|4015.9375] "A" Vector__XXX
 SG_ HybridDCChargingPowerMaximum : 32|16@1+ (0.05,0) [0|3212.75] "kW" Vector__XXX
 SG_ HrdrqstdEnrgTrnsfrTp : 48|4@1+ (1,0) [0|15] "" Vector__XXX

BO_ 2566567422 EVSE1DCLIM1: 8 Vector__XXX
 SG_ EVSEDCChargingVoltageMaximum : 0|16@1+ (0.05,0) [0|3212.75] "V" Vector__XXX
 SG_ EVSEDCChargingCurrentMaximum : 16|16@1+ (0.0625,0) [0|4015.9375] "A" Vector__XXX
 SG_ EVSEDCChargingPowerMaximum : 32|16@1+ (0.05,0) [0|3212.75] "kW" Vector__XXX
 SG_ EVSESpprtdEnrgTrnsfrTps : 48|4@1+ (1,0) [0|15] "" Vector__XXX

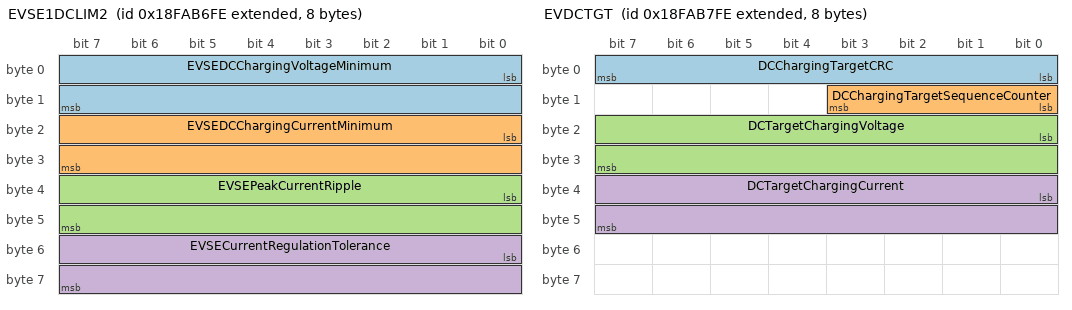
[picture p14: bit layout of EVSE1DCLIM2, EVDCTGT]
BO_ 2566567678 EVSE1DCLIM2: 8 Vector__XXX
 SG_ EVSEDCChargingVoltageMinimum : 0|16@1+ (0.05,0) [0|3212.75] "V" Vector__XXX
 SG_ EVSEDCChargingCurrentMinimum : 16|16@1+ (0.0625,0) [0|4015.9375] "A" Vector__XXX
 SG_ EVSEPeakCurrentRipple : 32|16@1+ (0.0625,0) [0|4015.9375] "A" Vector__XXX
 SG_ EVSECurrentRegulationTolerance : 48|16@1+ (0.0625,0) [0|4015.9375] "A" Vector__XXX

BO_ 2566567934 EVDCTGT: 8 Vector__XXX
 SG_ DCChargingTargetCRC : 0|8@1+ (1,0) [0|255] "count" Vector__XXX
 SG_ DCChargingTargetSequenceCounter : 8|4@1+ (1,0) [0|15] "" Vector__XXX
 SG_ DCTargetChargingVoltage : 16|16@1+ (0.05,0) [0|3212.75] "V" Vector__XXX
 SG_ DCTargetChargingCurrent : 32|16@1+ (0.0625,0) [0|4015.9375] "A" Vector__XXX

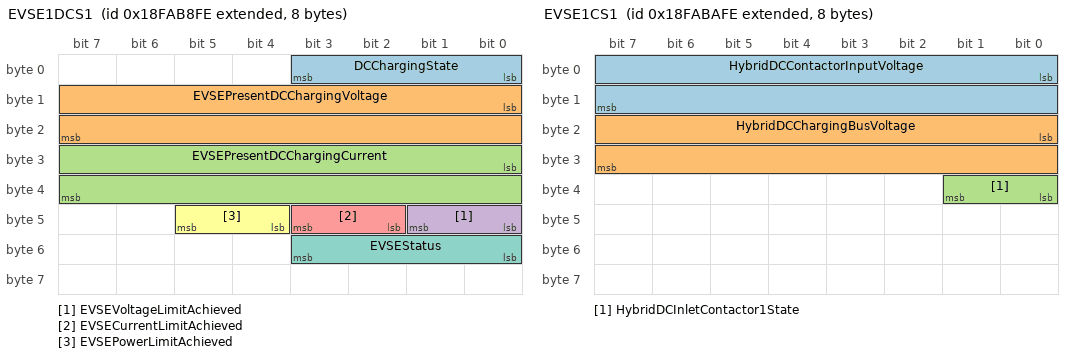
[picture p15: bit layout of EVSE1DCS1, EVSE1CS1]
BO_ 2566568190 EVSE1DCS1: 8 Vector__XXX
 SG_ DCChargingState : 0|4@1+ (1,0) [0|15] "" Vector__XXX
 SG_ EVSEPresentDCChargingVoltage : 8|16@1+ (0.05,0) [0|3212.75] "V" Vector__XXX
 SG_ EVSEPresentDCChargingCurrent : 24|16@1+ (0.05,-1600) [-1600|1612.75] "A" Vector__XXX
 SG_ EVSEVoltageLimitAchieved : 40|2@1+ (1,0) [0|3] "" Vector__XXX
 SG_ EVSECurrentLimitAchieved : 42|2@1+ (1,0) [0|3] "" Vector__XXX
 SG_ EVSEPowerLimitAchieved : 44|2@1+ (1,0) [0|3] "" Vector__XXX
 SG_ EVSEStatus : 48|4@1+ (1,0) [0|15] "" Vector__XXX

BO_ 2566568446 EVSE1CC1: 8 Vector__XXX
 SG_ HybridDCInletContactor1Command : 0|2@1+ (1,0) [0|3] "" Vector__XXX

BO_ 2566568702 EVSE1CS1: 8 Vector__XXX
 SG_ HybridDCContactorInputVoltage : 0|16@1+ (0.05,0) [0|3212.75] "V" Vector__XXX
 SG_ HybridDCChargingBusVoltage : 16|16@1+ (0.05,0) [0|3212.75] "V" Vector__XXX
 SG_ HybridDCInletContactor1State : 32|2@1+ (1,0) [0|3] "" Vector__XXX

BO_ 2566568958 DLCC3: 8 Vector__XXX
 SG_ TrnsmssnOlTmprtrHghLmpCmmnd : 0|2@1+ (1,0) [0|3] "" Vector__XXX
 SG_ TrnsmssnOlPrssrLwLmpCmmnd : 2|2@1+ (1,0) [0|3] "" Vector__XXX

BO_ 2566569214 DLCD3: 8 Vector__XXX
 SG_ TrnsmssnOlTmprtrHghLmpDt : 0|2@1+ (1,0) [0|3] "" Vector__XXX
 SG_ TrnsmssnOlPrssrLwLmpDt : 2|2@1+ (1,0) [0|3] "" Vector__XXX

BO_ 2566569470 MG1LD: 16 Vector__XXX
 SG_ MtrGnrtr1TtlEnrgCnsmd : 0|32@1+ (100,0) [0|421108121500] "Watt-hour" Vector__XXX
 SG_ MtrGnrtr1TtlEnrgGnrtd : 32|32@1+ (100,0) [0|421108121500] "Watt-hour" Vector__XXX
 SG_ MtrGnrtr1TtlChrgCnsmd : 64|32@1+ (100,0) [0|421108121500] "Ah" Vector__XXX
 SG_ MtrGnrtr1TtlChrgGnrtd : 96|32@1+ (100,0) [0|421108121500] "Ah" Vector__XXX

BO_ 2566569726 MG2LD: 16 Vector__XXX
 SG_ MtrGnrtr2TtlEnrgCnsmd : 0|32@1+ (100,0) [0|421108121500] "Watt-hour" Vector__XXX
 SG_ MtrGnrtr2TtlEnrgGnrtd : 32|32@1+ (100,0) [0|421108121500] "Watt-hour" Vector__XXX
 SG_ MtrGnrtr2TtlChrgCnsmd : 64|32@1+ (100,0) [0|421108121500] "Ah" Vector__XXX
 SG_ MtrGnrtr2TtlChrgGnrtd : 96|32@1+ (100,0) [0|421108121500] "Ah" Vector__XXX

BO_ 2566569982 MG3LD: 16 Vector__XXX
 SG_ MtrGnrtr3TtlEnrgCnsmd : 0|32@1+ (100,0) [0|421108121500] "Watt-hour" Vector__XXX
 SG_ MtrGnrtr3TtlEnrgGnrtd : 32|32@1+ (100,0) [0|421108121500] "Watt-hour" Vector__XXX
 SG_ MtrGnrtr3TtlChrgCnsmd : 64|32@1+ (100,0) [0|421108121500] "Ah" Vector__XXX
 SG_ MtrGnrtr3TtlChrgGnrtd : 96|32@1+ (100,0) [0|421108121500] "Ah" Vector__XXX

BO_ 2566570238 MG4LD: 16 Vector__XXX
 SG_ MtrGnrtr4TtlEnrgCnsmd : 0|32@1+ (100,0) [0|421108121500] "Watt-hour" Vector__XXX
 SG_ MtrGnrtr4TtlEnrgGnrtd : 32|32@1+ (100,0) [0|421108121500] "Watt-hour" Vector__XXX
 SG_ MtrGnrtr4TtlChrgCnsmd : 64|32@1+ (100,0) [0|421108121500] "Ah" Vector__XXX
 SG_ MtrGnrtr4TtlChrgGnrtd : 96|32@1+ (100,0) [0|421108121500] "Ah" Vector__XXX

BO_ 2566570494 MG5LD: 16 Vector__XXX
 SG_ MtrGnrtr5TtlEnrgCnsmd : 0|32@1+ (100,0) [0|421108121500] "Watt-hour" Vector__XXX
 SG_ MtrGnrtr5TtlEnrgGnrtd : 32|32@1+ (100,0) [0|421108121500] "Watt-hour" Vector__XXX
 SG_ MtrGnrtr5TtlChrgCnsmd : 64|32@1+ (100,0) [0|421108121500] "Ah" Vector__XXX
 SG_ MtrGnrtr5TtlChrgGnrtd : 96|32@1+ (100,0) [0|421108121500] "Ah" Vector__XXX

BO_ 2566570750 MG6LD: 16 Vector__XXX
 SG_ MtrGnrtr6TtlEnrgCnsmd : 0|32@1+ (100,0) [0|421108121500] "Watt-hour" Vector__XXX
 SG_ MtrGnrtr6TtlEnrgGnrtd : 32|32@1+ (100,0) [0|421108121500] "Watt-hour" Vector__XXX
 SG_ MtrGnrtr6TtlChrgCnsmd : 64|32@1+ (100,0) [0|421108121500] "Ah" Vector__XXX
 SG_ MtrGnrtr6TtlChrgGnrtd : 96|32@1+ (100,0) [0|421108121500] "Ah" Vector__XXX

BO_ 2566571006 AIR3: 8 Vector__XXX
 SG_ AirDryerCartridgeLifeRemaining : 0|8@1+ (0.4,0) [0|100] "%" Vector__XXX
 SG_ AirSuspensionSupplyPressure2 : 8|8@1+ (8,0) [0|2000] "kPa" Vector__XXX

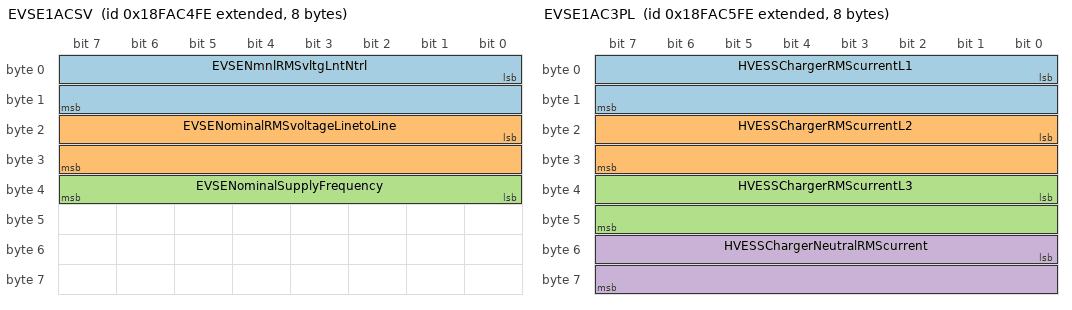
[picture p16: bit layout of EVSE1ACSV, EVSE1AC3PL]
BO_ 2566571262 EVSE1ACSV: 8 Vector__XXX
 SG_ EVSENmnlRMSvltgLntNtrl : 0|16@1+ (0.05,0) [0|3212.75] "V" Vector__XXX
 SG_ EVSENominalRMSvoltageLinetoLine : 16|16@1+ (0.05,0) [0|3212.75] "V" Vector__XXX
 SG_ EVSENominalSupplyFrequency : 32|8@1+ (1,0) [0|255] "" Vector__XXX

BO_ 2566571518 EVSE1AC3PL: 8 Vector__XXX
 SG_ HVESSChargerRMScurrentL1 : 0|16@1+ (0.0625,0) [0|4015.9375] "A" Vector__XXX
 SG_ HVESSChargerRMScurrentL2 : 16|16@1+ (0.0625,0) [0|4015.9375] "A" Vector__XXX
 SG_ HVESSChargerRMScurrentL3 : 32|16@1+ (0.0625,0) [0|4015.9375] "A" Vector__XXX
 SG_ HVESSChargerNeutralRMScurrent : 48|16@1+ (0.0625,0) [0|4015.9375] "A" Vector__XXX

BO_ 2499462910 ERC3: 8 Vector__XXX
 SG_ RtrdrRdSpdDlrtSwth : 0|2@1+ (1,0) [0|3] "" Vector__XXX
 SG_ RtrdrRdSpdAlrtSwth : 2|2@1+ (1,0) [0|3] "" Vector__XXX

BO_ 2566572286 ETC14: 8 Vector__XXX
 SG_ TransmissionClutch1Temperature : 0|16@1+ (0.03125,-273) [-273|1734.96875] "degC" Vector__XXX
 SG_ TrnsmssnClth1OvrhtIndtr : 16|2@1+ (1,0) [0|3] "" Vector__XXX

BO_ 2499464702 A1SCREGP2: 8 Vector__XXX
 SG_ Aftrtrtmnt1SCROtltAsltPrssr : 0|16@1+ (0.1,0) [0|6425.5] "kPa" Vector__XXX
 SG_ Aftrtrtmnt1SCROtltPrssr : 16|16@1+ (0.1,0) [0|6425.5] "kPa" Vector__XXX

BO_ 2566573822 PTO2: 8 Vector__XXX
 SG_ TrnsmssnPTOGrxOtptShftSpd : 0|16@1+ (0.125,0) [0|8031.875] "rpm" Vector__XXX
 SG_ TransmissionPTOGearboxStatus : 16|4@1+ (1,0) [0|15] "" Vector__XXX

BO_ 2364690686 EATC1: 8 Vector__XXX
 SG_ AxlrTrnsmssnOtptSpd : 0|16@1+ (0.125,0) [0|8031.875] "rpm" Vector__XXX

BO_ 2566563326 DFM3: 8 Vector__XXX
 SG_ BddDFMdEsttdIsttsFSvsRt : 0|16@1+ (0.05,0) [0|3212.75] "l/h" Vector__XXX

BO_ 2566563582 DFM2: 8 Vector__XXX
 SG_ BlnddDlFlMdTtlDslFlDspldGssFl : 0|32@1+ (0.5,0) [0|2105540607.5] "l" Vector__XXX
 SG_ BlnddDlFlMdTtlDslFlDmnd : 32|32@1+ (0.5,0) [0|2105540607.5] "l" Vector__XXX

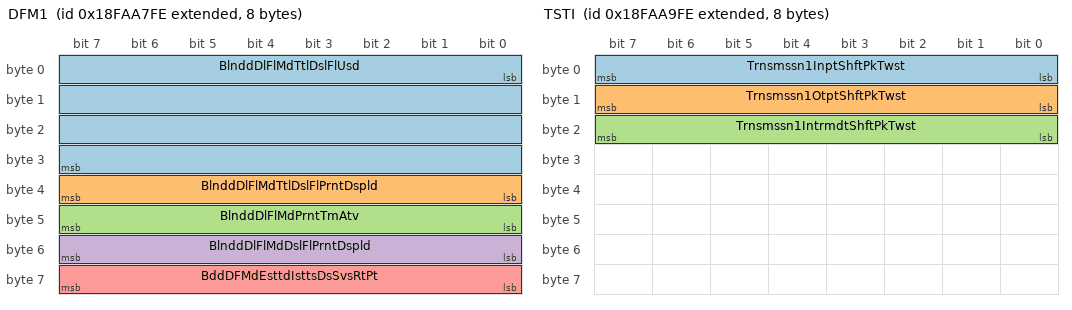
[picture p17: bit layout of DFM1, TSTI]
BO_ 2566563838 DFM1: 8 Vector__XXX
 SG_ BlnddDlFlMdTtlDslFlUsd : 0|32@1+ (0.5,0) [0|2105540607.5] "l" Vector__XXX
 SG_ BlnddDlFlMdTtlDslFlPrntDspld : 32|8@1+ (0.5,0) [0|125] "%" Vector__XXX
 SG_ BlnddDlFlMdPrntTmAtv : 40|8@1+ (0.4,0) [0|100] "%" Vector__XXX
 SG_ BlnddDlFlMdDslFlPrntDspld : 48|8@1+ (0.4,0) [0|100] "%" Vector__XXX
 SG_ BddDFMdEsttdIsttsDsSvsRtPt : 56|8@1+ (0.4,0) [0|100] "%" Vector__XXX

BO_ 2566564094 T1HIST: 12 Vector__XXX
 SG_ Trnsmssn1TtlHrsfOprtn : 0|32@1+ (1,0) [0|4211081215] "s" Vector__XXX
 SG_ Trnsmssn1TtlOtptShftRvltns : 32|32@1+ (1000,0) [0|4211081215000] "r" Vector__XXX
 SG_ Trnsmssn1OprtnTmSnRld : 64|32@1+ (1,0) [0|4211081215] "s" Vector__XXX

BO_ 2566564350 TSTI: 8 Vector__XXX
 SG_ Trnsmssn1InptShftPkTwst : 0|8@1+ (0.1,-12.5) [-12.5|12.5] "deg" Vector__XXX
 SG_ Trnsmssn1OtptShftPkTwst : 8|8@1+ (0.1,-12.5) [-12.5|12.5] "deg" Vector__XXX
 SG_ Trnsmssn1IntrmdtShftPkTwst : 16|8@1+ (0.1,-12.5) [-12.5|12.5] "deg" Vector__XXX

BO_ 2566564606 EATC2: 8 Vector__XXX
 SG_ AxlrTrnsmssnSltdGr : 0|8@1+ (1,-125) [-125|125] "gear value" Vector__XXX
 SG_ AxlrTrnsmssnCrrntGr : 8|8@1+ (1,-125) [-125|125] "gear value" Vector__XXX

CM_ BO_ 2364683006 "High Voltage Energy Storage Pack 9 Status 2";
CM_ SG_ 2364683006 HVESP9DshrgPwrLmtDtSttfChrg "HVESP9 Discharge Power Limit Due to State of Charge: Indicates whether or not discharge power of this HVES instance is being limited due to state of charge.This parameter is for one of multiple packs in an HVESS.  If there is only one pack in the sys...";
CM_ SG_ 2364683006 HVESP9DshrgPwrLmtDtBttrTmprtr "HVESP9 Discharge Power Limit Due to Battery Temperature: Indicates whether or not discharge power of this HVES instance is being limited due to battery temperature.This parameter is for one of multiple packs in an HVESS.  If there is only one pack in...";
CM_ SG_ 2364683006 HVESP9DsPwLtDtBttDstCdt "HVESP9 Discharge Power Limit Due to Battery Diagnostic Condition: Indicates whether or not discharge power of this HVES instance is being limited due to a battery diagnostic condition.This parameter is for one of multiple packs in an HVESS.  If there...";
CM_ SG_ 2364683006 HVESP9DshrgPwrLmtDtBttrrCllVltg "HVESP9 Discharge Power Limit Due to Battery or Cell Voltage: Indicates whether or not discharge power of this HVES instance is being limited due to a battery or cell voltage level.This parameter is for one of multiple packs in an HVESS.  If there is ...";
CM_ SG_ 2364683006 HVESP9DshrgPwrLmtDtBttrCrrnt "HVESP9 Discharge Power Limit Due to Battery Current: Indicates whether or not discharge power of this HVES instance is being limited due to battery current.This parameter is for one of multiple packs in an HVESS.  If there is only one pack in the sys...";
CM_ SG_ 2364683006 HVESP9DshrgPwrLmtDtnUndfndCs "HVESP9 Discharge Power Limit Due to an Undefined Cause: Indicates whether or not discharge power of this HVES instance is being limited due to an undefined cause.This parameter is for one of multiple packs in an HVESS.  If there is only one pack in t...";
CM_ SG_ 2364683006 HVESP9ChrgPwrLmtDtSttfChrg "HVESP9 Charge Power Limit Due to State of Charge: Indicates whether or not charge power of this HVES instance is being limited due to state of charge.This parameter is for one of multiple packs in an HVESS.  If there is only one pack in the system, t...";
CM_ SG_ 2364683006 HVESP9ChrgPwrLmtDtBttrTmprtr "HVESP9 Charge Power Limit Due to Battery Temperature: Indicates whether or not charge power of this HVES instance is being limited due to battery temperature.This parameter is for one of multiple packs in an HVESS.  If there is only one pack in the s...";
CM_ SG_ 2364683006 HVESP9CPwLtDtBttDstCdt "HVESP9 Charge Power Limit Due to Battery Diagnostic Condition: Indicates whether or not charge power of this HVES instance is being limited due to a battery diagnostic condition.This parameter is for one of multiple packs in an HVESS.  If there is on...";
CM_ SG_ 2364683006 HVESP9ChrgPwrLmtDtBttrrCllVltg "HVESP9 Charge Power Limit Due to Battery or Cell Voltage: Indicates whether or not charge power of this HVES instance is being limited due to a battery or cell voltage level.This parameter is for one of multiple packs in an HVESS.  If there is only o...";
CM_ SG_ 2364683006 HVESP9ChrgPwrLmtDtBttrCrrnt "HVESP9 Charge Power Limit Due to Battery Current: Indicates whether or not charge power of this HVES instance is being limited due to battery current.This parameter is for one of multiple packs in an HVESS.  If there is only one pack in the system, t...";
CM_ SG_ 2364683006 HVESP9ChrgPwrLmtDtnUndfndCs "HVESP9 Charge Power Limit Due to an Undefined Cause: Indicates whether or not charge power of this HVES instance is being limited due to an undefined cause.This parameter is for one of multiple packs in an HVESS.  If there is only one pack in the sys...";
CM_ BO_ 2364683262 "High Voltage Energy Storage Pack 9 Data 1";
CM_ SG_ 2364683262 HVESP9AvailableDischargePower "HVESP9 Available Discharge Power: The rate at which this High Voltage Energy Storage Pack instance can currently provide energy for propulsion or other uses.This parameter is for one of multiple packs in an HVESS.  If there is only one pack in the sy...";
CM_ SG_ 2364683262 HVESP9AvailableChargePower "HVESP9 Available Charge Power: The rate at which this High Voltage Energy Storage Pack instance can currently receive energy from a regenerative or recharging system.This parameter is for one of multiple packs in an HVESS.  If there is only one pack ...";
CM_ SG_ 2364683262 HVESP9VoltageLevel "HVESP9 Voltage Level: The voltage level of this High Voltage Energy Storage Pack instance. This parameter should be synchronized with SPN 14349 (HVESP9 Current) such that a realized power value can be calculated. If the HVES component physically cont...";
CM_ SG_ 2364683262 HVESP9Current "HVESP9 Current: The current in or out of this High Voltage Energy Storage Pack instance. This parameter should be synchronized with SPN 14348 (HVESP9 Voltage Level) such that a realized power value can be calculated. This parameter is defined from th...";
CM_ BO_ 2364683518 "High Voltage Energy Storage Pack 9 Data 2";
CM_ SG_ 2364683518 HVESP9FastUpdateStateofCharge "HVESP9 Fast Update State of Charge: Indicates this High Voltage Energy Storage Pack instance state of charge. 0% means no charge remaining, 100% means the system is fully charged in terms of physical limits of this energy storage pack instance. Accep...";
CM_ SG_ 2364683518 HVESP9HighestCellVoltage "HVESP9 Highest Cell Voltage: The highest voltage level reported by any cell in this High Voltage Energy Storage Pack instance. If a single voltage sensor covers more than one cell, the value in this parameter is for the smallest group of cells measur...";
CM_ SG_ 2364683518 HVESP9LowestCellVoltage "HVESP9 Lowest Cell Voltage: The lowest voltage level reported by any cell in this High Voltage Energy Storage Pack instance. If a single voltage sensor covers more than one cell, the value in this parameter is for the smallest group of cells measured...";
CM_ SG_ 2364683518 HVESP9CllVltgDffrntlStts "HVESP9 Cell Voltage Differential Status: Indicates whether or not the differential between the highest and lowest cell voltages are within acceptable limits, according to this High Voltage Energy Storage Pack instance. The actual voltage differential...";
CM_ BO_ 2364683774 "High Voltage Energy Storage Pack 9 Data 3";
CM_ SG_ 2364683774 HVESP9HighestCellTemperature "HVESP9 Highest Cell Temperature: The highest temperature level reported by any cell in this High Voltage Energy Storage Pack instance. If a single temperature sensor covers more than one cell, the value in this parameter is for the smallest group of ...";
CM_ SG_ 2364683774 HVESP9LowestCellTemperature "HVESP9 Lowest Cell Temperature: The lowest temperature level reported by any cell in this High Voltage Energy Storage Pack instance. If a single temperature sensor covers more than one cell, the value in this parameter is for the smallest group of ce...";
CM_ SG_ 2364683774 HVESP9AverageCellTemperature "HVESP9 Average Cell Temperature: The average temperature level of all cells in this High Voltage Energy Storage Pack instance.This parameter is for one of multiple packs in an HVESS.  If there is only one pack in the system, the HVESS parameters shou...";
CM_ SG_ 2364683774 HVESP9CllTmprtrDffrntlStts "HVESP9 Cell Temperature Differential Status: Indicates whether or not the differential between the highest and lowest cell temperatures are within acceptable limits per this High Voltage Energy Storage Pack instance. The actual temperature differenti...";
CM_ BO_ 2364684030 "High Voltage Energy Storage Pack 9 Data 4";
CM_ SG_ 2364684030 HVESP9DischargeCapacity "HVESP9 Discharge Capacity: The amount of stored electrical charge in this High Voltage Energy Storage Pack instance that is available for use by the hybrid system, i.e. “how full is the tank”. See SPN 14388 (HVESP9 Discharge Energy Capacity) for kilo...";
CM_ SG_ 2364684030 HVESP9ChargeCapacity "HVESP9 Charge Capacity: The amount of unused electrical charge storage in this High Voltage Energy Storage Pack instance that is available to be filled by charging, i.e. “how much empty space is remaining in the tank”. See SPN 14389 (HVESP9 Charge En...";
CM_ SG_ 2364684030 HVESP9CellBalancingCount "HVESP9 Cell Balancing Count: The number of cells that are currently being balanced in this High Voltage Energy Storage Pack instance.This parameter is for one of multiple packs in an HVESS.  If there is only one pack in the system, the HVESS paramete...";
CM_ BO_ 2364684286 "High Voltage Energy Storage Pack 9 Data 5";
CM_ SG_ 2364684286 HVESP9DischargeCurrentLimit "HVESP9 Discharge Current Limit: The maximum permissible current flow out of this High Voltage Energy Storage Pack instance. This parameter is defined from the high voltage energy storage pack's point of view.A negative value represents current flowin...";
CM_ SG_ 2364684286 HVESP9ChargeCurrentLimit "HVESP9 Charge Current Limit: The maximum permissible current flow into this High Voltage Energy Storage Pack instance. This parameter is defined from the high voltage energy storage pack's point of view.A positive value represents current flowing int...";
CM_ SG_ 2364684286 HVESP9LowestCellStateofCharge "HVESP9 Lowest Cell State of Charge: Indicates the state of charge of the lowest-charged cell in this High Voltage Energy Storage Pack instance. 0% means no charge remaining, 100% means the cell is fully charged. If a single state of charge value cove...";
CM_ SG_ 2364684286 HVESP9HighestCellStateofCharge "HVESP9 Highest Cell State of Charge: Indicates the state of charge of the highest-charged cell in this High Voltage Energy Storage Pack instance. 0% means no charge remaining, 100% means the cell is fully charged. If a single state of charge value co...";
CM_ BO_ 2364684542 "High Voltage Energy Storage Pack 9 Data 6";
CM_ SG_ 2364684542 HVESP9BusVoltage "HVESP9 Bus Voltage: The voltage level of the high voltage bus, as measured by this High Voltage Energy Storage Pack instance on the bus side (not the battery side) of its contactors.This parameter is for one of multiple packs in an HVESS.  If there i...";
CM_ SG_ 2364684542 HVESP9IgnitionVoltage "HVESP9 Ignition Voltage: The voltage level at the ignition input of this High Voltage Energy Storage Pack controller.This parameter is for one of multiple packs in an HVESS.  If there is only one pack in the system, the HVESS parameters should be use...";
CM_ SG_ 2364684542 HVESP9IntakeCoolantTemperature "HVESP9 Intake Coolant Temperature: The temperature of liquid coolant as it enters this High Voltage Energy Storage Pack instance.This parameter is for one of multiple packs in an HVESS.  If there is only one pack in the system, the HVESS parameters s...";
CM_ SG_ 2364684542 HVESP9OutletCoolantTemperature "HVESP9 Outlet Coolant Temperature: The temperature of liquid coolant as it exits this High Voltage Energy Storage Pack instance.This parameter is for one of multiple packs in an HVESS.  If there is only one pack in the system, the HVESS parameters sh...";
CM_ SG_ 2364684542 HVESP9ElectronicsTemperature "HVESP9 Electronics Temperature: The temperature of the electronics or control modules in this High Voltage Energy Storage Pack instance.  If there are multiple temperature sensors then this parameter would be set to the maximum sensor reading.This pa...";
CM_ SG_ 2364684542 HVESP9Temperature "HVESP9 Temperature: The temperature of this High Voltage Energy Storage Pack instance. The value may be determined from a unique sensor specifically for this purpose, or by aggregating various temperature sensor readings within the pack.This paramete...";
CM_ BO_ 2364684798 "High Voltage Energy Storage Pack 9 Status 1";
CM_ SG_ 2364684798 HVESP9HghVltgBsPstvCnttrStt "HVESP9 High-Voltage Bus (Positive) Contactor State: Position of this High Voltage Energy Storage Pack instance positive side bus contactor.  When this contactor is closed, the positive side of this HVES instance is connected to the positive side of t...";
CM_ SG_ 2364684798 HVESP9HghVltgBsNgtvCnttrStt "HVESP9 High-Voltage Bus (Negative) Contactor State: Position of this High Voltage Energy Storage Pack instance negative side bus contactor. When this contactor is closed, the negative side of this HVES instance is connected to the negative side of th...";
CM_ SG_ 2364684798 HVESP9HghVltgBsDsnntFrwrnng "HVESP9 High-Voltage Bus Disconnect Forewarning: Indicates that this High Voltage Energy Storage Pack instance is about to disconnect from the high voltage bus due to unacceptable conditions.This parameter is for one of multiple packs in an HVESS. If ...";
CM_ SG_ 2364684798 HVESP9HghVltgBsPrChrgRlStt "HVESP9 High-Voltage Bus Pre-Charge Relay State: Position of the high-voltage bus contactor pre-charge relay.  When this relay is closed, this High Voltage Energy Storage Pack instance is bringing the high-voltage bus up to its operating level.This pa...";
CM_ SG_ 2364684798 HVESP9CntrfPkCnttrStt "HVESP9 Center of Pack Contactor State: Position of the center high-voltage contactor. When this contactor is closed, the positive half of this High Voltage Energy Storage Pack instance is connected to the negative half. If a system controls the posit...";
CM_ SG_ 2364684798 HVESP9HghVltgBsAtvIsltnTstStts "HVESP9 High-Voltage Bus Active Isolation Test Status: Status of the high-voltage bus electrical active isolation test as performed by this High Voltage Energy Storage Pack instance.This parameter is for one of multiple packs in an HVESS. If there is ...";
CM_ SG_ 2364684798 HVESP9HghVltgBsPssvIsltnTstStts "HVESP9 High-Voltage Bus Passive Isolation Test Status: Status of the high-voltage bus electrical passive isolation test as performed by this High Voltage Energy Storage Pack instance.This parameter is for one of multiple packs in an HVESS. If there i...";
CM_ SG_ 2364684798 HVESP9HVILStatus "HVESP9 HVIL Status: Status of the High Voltage Interlock Loop from the viewpoint of this High Voltage Energy Storage Pack instance.This parameter is for one of multiple packs in an HVESS. If there is only one pack in the system, the HVESS parameters ...";
CM_ SG_ 2364684798 HVESP9InertiaSwitchStatus "HVESP9 Inertia Switch Status: Switch indicating that an impact has been sensed by this High Voltage Energy Storage Pack instance. The impact indication may require action by another controller, or by this HVES instance itself.  For example, a control...";
CM_ SG_ 2364684798 HVESP9StateofChargeStatus "HVESP9 State of Charge Status: Status of this High Voltage Energy Storage Pack instance State of Charge (SOC).  Note:  A given HVES controller may not support all of the states.This parameter is for one of multiple packs in an HVESS.  If there is onl...";
CM_ SG_ 2364684798 HVESP9CellBalanceStatus "HVESP9 Cell Balance Status: Indicates whether or not the cells in this High Voltage Energy Storage Pack instance are balanced.This parameter is for one of multiple packs in an HVESS.  If there is only one pack in the system, the HVESS parameters shou...";
CM_ SG_ 2364684798 HVESP9CellBalancingActive "HVESP9 Cell Balancing Active: Indicates whether or not the cells in this High Voltage Energy Storage Pack instance are currently being balanced.This parameter is for one of multiple packs in an HVESS.  If there is only one pack in the system, the HVE...";
CM_ SG_ 2364684798 HVESP9InternalChargerStatus "HVESP9 Internal Charger Status: Indicates that the charger in this HVES instance is on.  External chargers may use the External Energy Source Connection Status (SPN 7898) and related SPs.This parameter is for one of multiple packs in an HVESS. If the...";
CM_ SG_ 2364684798 HVESP9HghVltgBsCnntnStts "HVESP9 High-Voltage Bus Connection Status: This parameter provides high level feedback on this High Voltage Energy Storage Pack instance high voltage bus connection. For specific contactor information, see SPN 14371 (HVESP9 High-Voltage Bus (Positive...";
CM_ SG_ 2364684798 HVESP9OperationalStatus "HVESP9 Operational Status: Provides feedback on where this High Voltage Energy Storage Pack instance is in its operating spectrum, and includes feedback in response to the Operation Consent [i.e. SPN 14329 (HVESP9 Operation Consent)] and Power Down C...";
CM_ SG_ 2364684798 HVESP9Status1Counter "HVESP9 Status 1 Counter: The message counter is used to detect situations where the transmitting ECU malfunction repeats the same frame all the time. The receiver of the information may use the counter parameter to detect this situation. The transmit...";
CM_ SG_ 2364684798 HVESP9Status1CRC "HVESP9 Status 1 CRC: The CRC is defined as follows: • Length: 8 bits • Polynomial: x^8+x^5+x^3+x^2+x+1 • Initial Value: FFh • Input Data Reflection: Not reflected • Result Data Reflection: Not reflected • XOR value: FFhSAE makes no claim of the funct...";
CM_ BO_ 2364685054 "High Voltage Energy Storage Pack 9 Data 7";
CM_ SG_ 2364685054 HVESP9DischargeEnergyCapacity "HVESP9 Discharge Energy Capacity: The amount of stored electrical energy in this High Voltage Energy Storage Pack instance that is available for use by the hybrid system, i.e. “how full is the tank”. See SPN 14358 (HVESP9 Discharge Capacity) for Ampe...";
CM_ SG_ 2364685054 HVESP9ChargeEnergyCapacity "HVESP9 Charge Energy Capacity: The amount of unused electrical energy storage available to be filled by charging this High Voltage Energy Storage Pack instance, i.e. “how much empty space is remaining in the tank”. See SPN 14359 (HVESP9 Charge Capaci...";
CM_ SG_ 2364685054 HVESP9MaximumChargeVoltageLimit "HVESP9 Maximum Charge Voltage Limit: The maximum voltage level not to be exceeded while charging this High Voltage Energy Storage Pack instance. If this parameter is not supported, the maximum charge voltage should be limited to SPN 14459 (HVESP9 Rec...";
CM_ BO_ 2364685310 "High Voltage Energy Storage Pack 9 Module Status 1";
CM_ SG_ 2364685310 HVESP9Module1OperationalStatus "HVESP9 Module 1 Operational Status: Operational Status of Module 1 in this High Voltage Energy Storage Pack Instance.  Not Operational is used when the module is initializing or not able to function (e.g. internal module level monitors have failed). ...";
CM_ SG_ 2364685310 HVESP9Module2OperationalStatus "HVESP9 Module 2 Operational Status: Operational Status of Module 2 in this High Voltage Energy Storage Pack Instance.  Not Operational is used when the module is initializing or not able to function (e.g. internal module level monitors have failed). ...";
CM_ SG_ 2364685310 HVESP9Module3OperationalStatus "HVESP9 Module 3 Operational Status: Operational Status of Module 3 in this High Voltage Energy Storage Pack Instance.  Not Operational is used when the module is initializing or not able to function (e.g. internal module level monitors have failed). ...";
CM_ SG_ 2364685310 HVESP9Module4OperationalStatus "HVESP9 Module 4 Operational Status: Operational Status of Module 4 in this High Voltage Energy Storage Pack Instance.  Not Operational is used when the module is initializing or not able to function (e.g. internal module level monitors have failed). ...";
CM_ SG_ 2364685310 HVESP9Module5OperationalStatus "HVESP9 Module 5 Operational Status: Operational Status of Module 5 in this High Voltage Energy Storage Pack Instance.  Not Operational is used when the module is initializing or not able to function (e.g. internal module level monitors have failed). ...";
CM_ SG_ 2364685310 HVESP9Module6OperationalStatus "HVESP9 Module 6 Operational Status: Operational Status of Module 6 in this High Voltage Energy Storage Pack Instance.  Not Operational is used when the module is initializing or not able to function (e.g. internal module level monitors have failed). ...";
CM_ SG_ 2364685310 HVESP9Module7OperationalStatus "HVESP9 Module 7 Operational Status: Operational Status of Module 7 in this High Voltage Energy Storage Pack Instance.  Not Operational is used when the module is initializing or not able to function (e.g. internal module level monitors have failed). ...";
CM_ SG_ 2364685310 HVESP9Module8OperationalStatus "HVESP9 Module 8 Operational Status: Operational Status of Module 8 in this High Voltage Energy Storage Pack Instance.  Not Operational is used when the module is initializing or not able to function (e.g. internal module level monitors have failed). ...";
CM_ SG_ 2364685310 HVESP9Module9OperationalStatus "HVESP9 Module 9 Operational Status: Operational Status of Module 9 in this High Voltage Energy Storage Pack Instance.  Not Operational is used when the module is initializing or not able to function (e.g. internal module level monitors have failed). ...";
CM_ SG_ 2364685310 HVESP9Module10OperationalStatus "HVESP9 Module 10 Operational Status: Operational Status of Module 10 in this High Voltage Energy Storage Pack Instance.  Not Operational is used when the module is initializing or not able to function (e.g. internal module level monitors have failed)...";
CM_ SG_ 2364685310 HVESP9Module11OperationalStatus "HVESP9 Module 11 Operational Status: Operational Status of Module 11 in this High Voltage Energy Storage Pack Instance.  Not Operational is used when the module is initializing or not able to function (e.g. internal module level monitors have failed)...";
CM_ SG_ 2364685310 HVESP9Module12OperationalStatus "HVESP9 Module 12 Operational Status: Operational Status of Module 12 in this High Voltage Energy Storage Pack Instance.  Not Operational is used when the module is initializing or not able to function (e.g. internal module level monitors have failed)...";
CM_ SG_ 2364685310 HVESP9Module13OperationalStatus "HVESP9 Module 13 Operational Status: Operational Status of Module 13 in this High Voltage Energy Storage Pack Instance.  Not Operational is used when the module is initializing or not able to function (e.g. internal module level monitors have failed)...";
CM_ SG_ 2364685310 HVESP9Module14OperationalStatus "HVESP9 Module 14 Operational Status: Operational Status of Module 14 in this High Voltage Energy Storage Pack Instance.  Not Operational is used when the module is initializing or not able to function (e.g. internal module level monitors have failed)...";
CM_ SG_ 2364685310 HVESP9Module15OperationalStatus "HVESP9 Module 15 Operational Status: Operational Status of Module 15 in this High Voltage Energy Storage Pack Instance.  Not Operational is used when the module is initializing or not able to function (e.g. internal module level monitors have failed)...";
CM_ SG_ 2364685310 HVESP9Module16OperationalStatus "HVESP9 Module 16 Operational Status: Operational Status of Module 16 in this High Voltage Energy Storage Pack Instance.  Not Operational is used when the module is initializing or not able to function (e.g. internal module level monitors have failed)...";
CM_ SG_ 2364685310 HVESP9Module17OperationalStatus "HVESP9 Module 17 Operational Status: Operational Status of Module 17 in this High Voltage Energy Storage Pack Instance.  Not Operational is used when the module is initializing or not able to function (e.g. internal module level monitors have failed)...";
CM_ SG_ 2364685310 HVESP9Module18OperationalStatus "HVESP9 Module 18 Operational Status: Operational Status of Module 18 in this High Voltage Energy Storage Pack Instance.  Not Operational is used when the module is initializing or not able to function (e.g. internal module level monitors have failed)...";
CM_ SG_ 2364685310 HVESP9Module19OperationalStatus "HVESP9 Module 19 Operational Status: Operational Status of Module 19 in this High Voltage Energy Storage Pack Instance.  Not Operational is used when the module is initializing or not able to function (e.g. internal module level monitors have failed)...";
CM_ SG_ 2364685310 HVESP9Module20OperationalStatus "HVESP9 Module 20 Operational Status: Operational Status of Module 20 in this High Voltage Energy Storage Pack Instance.  Not Operational is used when the module is initializing or not able to function (e.g. internal module level monitors have failed)...";
CM_ SG_ 2364685310 HVESP9Module21OperationalStatus "HVESP9 Module 21 Operational Status: Operational Status of Module 21 in this High Voltage Energy Storage Pack Instance.  Not Operational is used when the module is initializing or not able to function (e.g. internal module level monitors have failed)...";
CM_ SG_ 2364685310 HVESP9Module22OperationalStatus "HVESP9 Module 22 Operational Status: Operational Status of Module 22 in this High Voltage Energy Storage Pack Instance.  Not Operational is used when the module is initializing or not able to function (e.g. internal module level monitors have failed)...";
CM_ SG_ 2364685310 HVESP9Module23OperationalStatus "HVESP9 Module 23 Operational Status: Operational Status of Module 23 in this High Voltage Energy Storage Pack Instance.  Not Operational is used when the module is initializing or not able to function (e.g. internal module level monitors have failed)...";
CM_ SG_ 2364685310 HVESP9Module24OperationalStatus "HVESP9 Module 24 Operational Status: Operational Status of Module 24 in this High Voltage Energy Storage Pack Instance.  Not Operational is used when the module is initializing or not able to function (e.g. internal module level monitors have failed)...";
CM_ SG_ 2364685310 HVESP9Module25OperationalStatus "HVESP9 Module 25 Operational Status: Operational Status of Module 25 in this High Voltage Energy Storage Pack Instance.  Not Operational is used when the module is initializing or not able to function (e.g. internal module level monitors have failed)...";
CM_ SG_ 2364685310 HVESP9Module26OperationalStatus "HVESP9 Module 26 Operational Status: Operational Status of Module 26 in this High Voltage Energy Storage Pack Instance.  Not Operational is used when the module is initializing or not able to function (e.g. internal module level monitors have failed)...";
CM_ SG_ 2364685310 HVESP9Module27OperationalStatus "HVESP9 Module 27 Operational Status: Operational Status of Module 27 in this High Voltage Energy Storage Pack Instance.  Not Operational is used when the module is initializing or not able to function (e.g. internal module level monitors have failed)...";
CM_ SG_ 2364685310 HVESP9Module28OperationalStatus "HVESP9 Module 28 Operational Status: Operational Status of Module 28 in this High Voltage Energy Storage Pack Instance.  Not Operational is used when the module is initializing or not able to function (e.g. internal module level monitors have failed)...";
CM_ SG_ 2364685310 HVESP9Module29OperationalStatus "HVESP9 Module 29 Operational Status: Operational Status of Module 29 in this High Voltage Energy Storage Pack Instance.  Not Operational is used when the module is initializing or not able to function (e.g. internal module level monitors have failed)...";
CM_ SG_ 2364685310 HVESP9Module30OperationalStatus "HVESP9 Module 30 Operational Status: Operational Status of Module 30 in this High Voltage Energy Storage Pack Instance.  Not Operational is used when the module is initializing or not able to function (e.g. internal module level monitors have failed)...";
CM_ SG_ 2364685310 HVESP9Module31OperationalStatus "HVESP9 Module 31 Operational Status: Operational Status of Module 31 in this High Voltage Energy Storage Pack Instance.  Not Operational is used when the module is initializing or not able to function (e.g. internal module level monitors have failed)...";
CM_ SG_ 2364685310 HVESP9Module32OperationalStatus "HVESP9 Module 32 Operational Status: Operational Status of Module 32 in this High Voltage Energy Storage Pack Instance.  Not Operational is used when the module is initializing or not able to function (e.g. internal module level monitors have failed)...";
CM_ BO_ 2364685566 "High Voltage Energy Storage Pack 9 Thermal Management System Status 1";
CM_ SG_ 2364685566 HVESP9ThrmlMngmntSstmSLIInptPwr "HVESP9 Thermal Management System SLI Input Power: This is the low-voltage power consumed by this HVES Thermal Management System (TMS).This parameter is for one of multiple packs in an HVESS.  If there is only one pack in the system, the HVESS paramet...";
CM_ SG_ 2364685566 HVESP9TMtSstHVtIptPw "HVESP9 Thermal Management System High-Voltage Input Power: This is the high-voltage power consumed by this HVES Thermal Management System (TMS).This parameter is for one of multiple packs in an HVESS.  If there is only one pack in the system, the HVE...";
CM_ SG_ 2364685566 HVESP9ThrmlMngmntSstmCmprssrSpd "HVESP9 Thermal Management System Compressor Speed: When this High Voltage Energy Storage Pack Thermal Management System is equipped with an active cooling system (e.g. air conditioner), this is the Compressor Speed.This parameter is for one of multip...";
CM_ SG_ 2364685566 HVESP9ThrmlMngmntSstmRltvHmdt "HVESP9 Thermal Management System Relative Humidty: When this High Voltage Energy Storage Pack Thermal Management System is equipped with a relative humidity sensor, this is the  measured Relative Humidity.This parameter is for one of multiple packs i...";
CM_ SG_ 2364685566 HVESP9ThrmlMngmntSstmHtrStts "HVESP9 Thermal Management System Heater Status: The state of this High Voltage Energy Storage Pack heaterThis parameter is for one of multiple packs in an HVESS.  If there is only one pack in the system, the HVESS parameters should be used. If there ...";
CM_ SG_ 2364685566 HVESP9ThrmlMngmntSstmHVILStts "HVESP9 Thermal Management System HVIL Status: In multiple HVES configurations, this is the status of the High Voltage Interlock Loop from the viewpoint of this Thermal Management System.00b = HVIL Closed01b = HVIL Open10b = Error11b = Not AvailableTh...";
CM_ SG_ 2364685566 HVESP9ThrmlMngmntSstmMd "HVESP9 Thermal Management System Mode: Indicates the operating mode of the Thermal Management System.  The heat transfer medium may be (e.g. liquid or air).  The cooling system may be fans, liquid coolant, or a combination of mediums.  The system may...";
CM_ SG_ 2364685566 HVESP9ThrmlMngmntSstmClntLvl "HVESP9 Thermal Management System Coolant Level: Indicates the coolant level in this HVES Thermal Management System (TMS).This parameter is for one of multiple packs in an HVESS.  If there is only one pack in the system, the HVESS parameters should be...";
CM_ BO_ 2364685822 "High Voltage Energy Storage Pack 9 Data 8";
CM_ SG_ 2364685822 HVESP9HghstCllVltgMdlNmr "HVESP9 Highest Cell Voltage Module Number: Identifies the location of the module containing SPN 14351 (HVESP9 Highest Cell Voltage).This parameter is for one of multiple packs in an HVESS. If there is only one pack in the system, the HVESS parameters...";
CM_ SG_ 2364685822 HVESP9HghstCllVltgCllNmr "HVESP9 Highest Cell Voltage Cell Number: Identifies the location of SPN 14351 (HVESP9 Highest Cell Voltage) within SPN 14431 (HVESP9 Highest Cell Voltage Module Number).This parameter is for one of multiple packs in an HVESS. If there is only one pac...";
CM_ SG_ 2364685822 HVESP9LwstCllVltgMdlNmr "HVESP9 Lowest Cell Voltage Module Number: Identifies the location of the module containing SPN 14352 (HVESP9 Lowest Cell Voltage).This parameter is for one of multiple packs in an HVESS. If there is only one pack in the system, the HVESS parameters s...";
CM_ SG_ 2364685822 HVESP9LwstCllVltgCllNmr "HVESP9 Lowest Cell Voltage Cell Number: Identifies the location of SPN 14352 (HVESP9 Lowest Cell Voltage) within SPN 14433 (HVESP9 Lowest Cell Voltage Module Number).This parameter is for one of multiple packs in an HVESS. If there is only one pack i...";
CM_ SG_ 2364685822 HVESP9AverageCellVoltage "HVESP9 Average Cell Voltage: The average cell voltage in this High Voltage Energy Storage Pack instance.This parameter is for one of multiple packs in an HVESS.  If there is only one pack in the system, the HVESS parameters should be used. If there a...";
CM_ BO_ 2364686078 "High Voltage Energy Storage Pack 9 Data 9";
CM_ SG_ 2364686078 HVESP9HghstCllTmprtrMdlNmr "HVESP9 Highest Cell Temperature Module Number: Identifies the location of the module containing SPN 14354 (HVESP9 Highest Cell Temperature).This parameter is for one of multiple packs in an HVESS. If there is only one pack in the system, the HVESS pa...";
CM_ SG_ 2364686078 HVESP9HghstCllTmprtrCllNmr "HVESP9 Highest Cell Temperature Cell Number: Identifies the location of SPN 14354 (HVESP9 Highest Cell Temperature) within SPN 14436 (HVESP9 Highest Cell Temperature Module Number).This parameter is for one of multiple packs in an HVESS. If there is ...";
CM_ SG_ 2364686078 HVESP9LwstCllTmprtrMdlNmr "HVESP9 Lowest Cell Temperature Module Number: Identifies the location of the module containing SPN 14355 (HVESP9 Lowest Cell Temperature).This parameter is for one of multiple packs in an HVESS. If there is only one pack in the system, the HVESS para...";
CM_ SG_ 2364686078 HVESP9LwstCllTmprtrCllNmr "HVESP9 Lowest Cell Temperature Cell Number: Identifies the location of SPN 14355 (HVESP9 Lowest Cell Temperature) within SPN 14438 (HVESP9 Lowest Cell Temperature Module Number).This parameter is for one of multiple packs in an HVESS. If there is onl...";
CM_ BO_ 2364686334 "High Voltage Energy Storage Pack 9 Data 10";
CM_ SG_ 2364686334 HVESP9HghstCllSttfChrgMdlNmr "HVESP9 Highest Cell State of Charge Module Number: Identifies the location of the module containing SPN 14364 (HVESP9 Highest Cell State of Charge).This parameter is for one of multiple packs in an HVESS. If there is only one pack in the system, the ...";
CM_ SG_ 2364686334 HVESP9HghstCllSttfChrgCllNmr "HVESP9 Highest Cell State of Charge Cell Number: Identifies the location of SPN 14364 (HVESP9 Highest Cell State of Charge) within SPN 14440 (HVESP9 Highest Cell State of Charge Module Number).This parameter is for one of multiple packs in an HVESS. ...";
CM_ SG_ 2364686334 HVESP9LwstCllSttfChrgMdlNmr "HVESP9 Lowest Cell State of Charge Module Number: Identifies the location of the module containing SPN 14363 (HVESP9 Lowest Cell State of Charge).This parameter is for one of multiple packs in an HVESS. If there is only one pack in the system, the HV...";
CM_ SG_ 2364686334 HVESP9LwstCllSttfChrgCllNmr "HVESP9 Lowest Cell State of Charge Cell Number: Identifies the location of SPN 14363 (HVESP9 Lowest Cell State of Charge) within SPN 14442 (HVESP9 Lowest Cell State of Charge Module Number).This parameter is for one of multiple packs in an HVESS. If ...";
CM_ SG_ 2364686334 HVESP9HghVltgBsAtvIsltnTstRslts "HVESP9 High-Voltage Bus Active Isolation Test Results: The isolation resistance expressed in Ohms per Volt that resulted from the High-Voltage Bus Active Isolation Test.See SPN 14376 (HVESP9 High-Voltage Bus Active Isolation Test Status) for test sta...";
CM_ SG_ 2364686334 HVESP9HVtBsPssvIstTstRsts "HVESP9 High-Voltage Bus Passive Isolation Test Results: The isolation resistance expressed in Ohms per Volt that resulted from the High-Voltage Bus Passive Isolation Test.See SPN 14377 (HVESP9 High-Voltage Bus Passive Isolation Test Status) for test ...";
CM_ BO_ 2364686590 "High Voltage Energy Storage Pack 9 Data 11";
CM_ SG_ 2364686590 HVESP9BsVltgNgtvtChsssGrndVltg "HVESP9 Bus Voltage Negative to Chassis Ground Voltage: Voltage difference between the most negative terminal of the HVES battery and chassis measured on the hybrid system bus side (not the battery side) of any HVES contained output contactor.  This v...";
CM_ SG_ 2364686590 HVESP9VltgLvlNgtvtChsssGrndVltg "HVESP9 Voltage Level Negative to Chassis Ground Voltage: Voltage difference between the most negative terminal of the HVES battery and chassis measured at the battery side of any HVES contained output contactor.  This voltage may be used for system l...";
CM_ SG_ 2364686590 HVESP9ActualChargeRate "HVESP9 Actual Charge Rate: This signal represents the actual present charge rate of this High Voltage Energy Storage Pack instance.This parameter is for one of multiple packs in an HVESS. If there is only one pack in the system, the HVESS parameters ...";
CM_ BO_ 2364686846 "High Voltage Energy Storage Pack 10 Status 2";
CM_ SG_ 2364686846 HVESP10DshrgPwrLmtDtSttfChrg "HVESP10 Discharge Power Limit Due to State of Charge: Indicates whether or not discharge power of this HVES instance is being limited due to state of charge.This parameter is for one of multiple packs in an HVESS.  If there is only one pack in the sy...";
CM_ SG_ 2364686846 HVESP10DshrgPwrLmtDtBttrTmprtr "HVESP10 Discharge Power Limit Due to Battery Temperature: Indicates whether or not discharge power of this HVES instance is being limited due to battery temperature.This parameter is for one of multiple packs in an HVESS.  If there is only one pack i...";
CM_ SG_ 2364686846 HVESP10DsPwLtDtBttDstCdt "HVESP10 Discharge Power Limit Due to Battery Diagnostic Condition: Indicates whether or not discharge power of this HVES instance is being limited due to a battery diagnostic condition.This parameter is for one of multiple packs in an HVESS.  If ther...";
CM_ SG_ 2364686846 HVESP10DsPwLtDtBttCVt "HVESP10 Discharge Power Limit Due to Battery or Cell Voltage: Indicates whether or not discharge power of this HVES instance is being limited due to a battery or cell voltage level.This parameter is for one of multiple packs in an HVESS.  If there is...";
CM_ SG_ 2364686846 HVESP10DshrgPwrLmtDtBttrCrrnt "HVESP10 Discharge Power Limit Due to Battery Current: Indicates whether or not discharge power of this HVES instance is being limited due to battery current.This parameter is for one of multiple packs in an HVESS.  If there is only one pack in the sy...";
CM_ SG_ 2364686846 HVESP10DshrgPwrLmtDtnUndfndCs "HVESP10 Discharge Power Limit Due to an Undefined Cause: Indicates whether or not discharge power of this HVES instance is being limited due to an undefined cause.This parameter is for one of multiple packs in an HVESS.  If there is only one pack in ...";
CM_ SG_ 2364686846 HVESP10ChrgPwrLmtDtSttfChrg "HVESP10 Charge Power Limit Due to State of Charge: Indicates whether or not charge power of this HVES instance is being limited due to state of charge.This parameter is for one of multiple packs in an HVESS.  If there is only one pack in the system, ...";
CM_ SG_ 2364686846 HVESP10ChrgPwrLmtDtBttrTmprtr "HVESP10 Charge Power Limit Due to Battery Temperature: Indicates whether or not charge power of this HVES instance is being limited due to battery temperature.This parameter is for one of multiple packs in an HVESS.  If there is only one pack in the ...";
CM_ SG_ 2364686846 HVESP10CPwLtDtBttDstCdt "HVESP10 Charge Power Limit Due to Battery Diagnostic Condition: Indicates whether or not charge power of this HVES instance is being limited due to a battery diagnostic condition.This parameter is for one of multiple packs in an HVESS.  If there is o...";
CM_ SG_ 2364686846 HVESP10ChrgPwrLmtDtBttrrCllVltg "HVESP10 Charge Power Limit Due to Battery or Cell Voltage: Indicates whether or not charge power of this HVES instance is being limited due to a battery or cell voltage level.This parameter is for one of multiple packs in an HVESS.  If there is only ...";
CM_ SG_ 2364686846 HVESP10ChrgPwrLmtDtBttrCrrnt "HVESP10 Charge Power Limit Due to Battery Current: Indicates whether or not charge power of this HVES instance is being limited due to battery current.This parameter is for one of multiple packs in an HVESS.  If there is only one pack in the system, ...";
CM_ SG_ 2364686846 HVESP10ChrgPwrLmtDtnUndfndCs "HVESP10 Charge Power Limit Due to an Undefined Cause: Indicates whether or not charge power of this HVES instance is being limited due to an undefined cause.This parameter is for one of multiple packs in an HVESS.  If there is only one pack in the sy...";
CM_ BO_ 2364687102 "High Voltage Energy Storage Pack 10 Data 1";
CM_ SG_ 2364687102 HVESP10AvailableDischargePower "HVESP10 Available Discharge Power: The rate at which this High Voltage Energy Storage Pack instance can currently provide energy for propulsion or other uses.This parameter is for one of multiple packs in an HVESS.  If there is only one pack in the s...";
CM_ SG_ 2364687102 HVESP10AvailableChargePower "HVESP10 Available Charge Power: The rate at which this High Voltage Energy Storage Pack instance can currently receive energy from a regenerative or recharging system.This parameter is for one of multiple packs in an HVESS.  If there is only one pack...";
CM_ SG_ 2364687102 HVESP10VoltageLevel "HVESP10 Voltage Level: The voltage level of this High Voltage Energy Storage Pack instance. This parameter should be synchronized with SPN 14492 (HVESP10 Current) such that a realized power value can be calculated. If the HVES component physically co...";
CM_ SG_ 2364687102 HVESP10Current "HVESP10 Current: The current in or out of this High Voltage Energy Storage Pack instance. This parameter should be synchronized with SPN 14491 (HVESP10 Voltage Level) such that a realized power value can be calculated. This parameter is defined from ...";
CM_ BO_ 2364687358 "High Voltage Energy Storage Pack 10 Data 2";
CM_ SG_ 2364687358 HVESP10FastUpdateStateofCharge "HVESP10 Fast Update State of Charge: Indicates this High Voltage Energy Storage Pack instance state of charge. 0% means no charge remaining, 100% means the system is fully charged in terms of physical limits of this energy storage pack instance. Acce...";
CM_ SG_ 2364687358 HVESP10HighestCellVoltage "HVESP10 Highest Cell Voltage: The highest voltage level reported by any cell in this High Voltage Energy Storage Pack instance. If a single voltage sensor covers more than one cell, the value in this parameter is for the smallest group of cells measu...";
CM_ SG_ 2364687358 HVESP10LowestCellVoltage "HVESP10 Lowest Cell Voltage: The lowest voltage level reported by any cell in this High Voltage Energy Storage Pack instance. If a single voltage sensor covers more than one cell, the value in this parameter is for the smallest group of cells measure...";
CM_ SG_ 2364687358 HVESP10CllVltgDffrntlStts "HVESP10 Cell Voltage Differential Status: Indicates whether or not the differential between the highest and lowest cell voltages are within acceptable limits, according to this High Voltage Energy Storage Pack instance. The actual voltage differentia...";
CM_ BO_ 2364687614 "High Voltage Energy Storage Pack 10 Data 3";
CM_ SG_ 2364687614 HVESP10HighestCellTemperature "HVESP10 Highest Cell Temperature: The highest temperature level reported by any cell in this High Voltage Energy Storage Pack instance. If a single temperature sensor covers more than one cell, the value in this parameter is for the smallest group of...";
CM_ SG_ 2364687614 HVESP10LowestCellTemperature "HVESP10 Lowest Cell Temperature: The lowest temperature level reported by any cell in this High Voltage Energy Storage Pack instance. If a single temperature sensor covers more than one cell, the value in this parameter is for the smallest group of c...";
CM_ SG_ 2364687614 HVESP10AverageCellTemperature "HVESP10 Average Cell Temperature: The average temperature level of all cells in this High Voltage Energy Storage Pack instance.This parameter is for one of multiple packs in an HVESS.  If there is only one pack in the system, the HVESS parameters sho...";
CM_ SG_ 2364687614 HVESP10CllTmprtrDffrntlStts "HVESP10 Cell Temperature Differential Status: Indicates whether or not the differential between the highest and lowest cell temperatures are within acceptable limits per this High Voltage Energy Storage Pack instance. The actual temperature different...";
CM_ BO_ 2364687870 "High Voltage Energy Storage Pack 10 Data 4";
CM_ SG_ 2364687870 HVESP10DischargeCapacity "HVESP10 Discharge Capacity: The amount of stored electrical charge in this High Voltage Energy Storage Pack instance that is available for use by the hybrid system, i.e. “how full is the tank”. See SPN 14531 (HVESP10 Discharge Energy Capacity) for ki...";
CM_ SG_ 2364687870 HVESP10ChargeCapacity "HVESP10 Charge Capacity: The amount of unused electrical charge storage in this High Voltage Energy Storage Pack instance that is available to be filled by charging, i.e. “how much empty space is remaining in the tank”. See SPN 14532 (HVESP10 Charge ...";
CM_ SG_ 2364687870 HVESP10CellBalancingCount "HVESP10 Cell Balancing Count: The number of cells that are currently being balanced in this High Voltage Energy Storage Pack instance.This parameter is for one of multiple packs in an HVESS.  If there is only one pack in the system, the HVESS paramet...";
CM_ BO_ 2364688126 "High Voltage Energy Storage Pack 10 Data 5";
CM_ SG_ 2364688126 HVESP10DischargeCurrentLimit "HVESP10 Discharge Current Limit: The maximum permissible current flow out of this High Voltage Energy Storage Pack instance. This parameter is defined from the high voltage energy storage pack's point of view.A negative value represents current flowi...";
CM_ SG_ 2364688126 HVESP10ChargeCurrentLimit "HVESP10 Charge Current Limit: The maximum permissible current flow into this High Voltage Energy Storage Pack instance. This parameter is defined from the high voltage energy storage pack's point of view.A positive value represents current flowing in...";
CM_ SG_ 2364688126 HVESP10LowestCellStateofCharge "HVESP10 Lowest Cell State of Charge: Indicates the state of charge of the lowest-charged cell in this High Voltage Energy Storage Pack instance. 0% means no charge remaining, 100% means the cell is fully charged. If a single state of charge value cov...";
CM_ SG_ 2364688126 HVESP10HighestCellStateofCharge "HVESP10 Highest Cell State of Charge: Indicates the state of charge of the highest-charged cell in this High Voltage Energy Storage Pack instance. 0% means no charge remaining, 100% means the cell is fully charged. If a single state of charge value c...";
CM_ BO_ 2364688382 "High Voltage Energy Storage Pack 10 Data 6";
CM_ SG_ 2364688382 HVESP10BusVoltage "HVESP10 Bus Voltage: The voltage level of the high voltage bus, as measured by this High Voltage Energy Storage Pack instance on the bus side (not the battery side) of its contactors.This parameter is for one of multiple packs in an HVESS.  If there ...";
CM_ SG_ 2364688382 HVESP10IgnitionVoltage "HVESP10 Ignition Voltage: The voltage level at the ignition input of this High Voltage Energy Storage Pack controller.This parameter is for one of multiple packs in an HVESS.  If there is only one pack in the system, the HVESS parameters should be us...";
CM_ SG_ 2364688382 HVESP10IntakeCoolantTemperature "HVESP10 Intake Coolant Temperature: The temperature of liquid coolant as it enters this High Voltage Energy Storage Pack instance.This parameter is for one of multiple packs in an HVESS.  If there is only one pack in the system, the HVESS parameters ...";
CM_ SG_ 2364688382 HVESP10OutletCoolantTemperature "HVESP10 Outlet Coolant Temperature: The temperature of liquid coolant as it exits this High Voltage Energy Storage Pack instance.This parameter is for one of multiple packs in an HVESS.  If there is only one pack in the system, the HVESS parameters s...";
CM_ SG_ 2364688382 HVESP10ElectronicsTemperature "HVESP10 Electronics Temperature: The temperature of the electronics or control modules in this High Voltage Energy Storage Pack instance.  If there are multiple temperature sensors then this parameter would be set to the maximum sensor reading.This p...";
CM_ SG_ 2364688382 HVESP10Temperature "HVESP10 Temperature: The temperature of this High Voltage Energy Storage Pack instance. The value may be determined from a unique sensor specifically for this purpose, or by aggregating various temperature sensor readings within the pack.This paramet...";
CM_ BO_ 2364688638 "High Voltage Energy Storage Pack 10 Status 1";
CM_ SG_ 2364688638 HVESP10HghVltgBsPstvCnttrStt "HVESP10 High-Voltage Bus (Positive) Contactor State: Position of this High Voltage Energy Storage Pack instance positive side bus contactor.  When this contactor is closed, the positive side of this HVES instance is connected to the positive side of ...";
CM_ SG_ 2364688638 HVESP10HghVltgBsNgtvCnttrStt "HVESP10 High-Voltage Bus (Negative) Contactor State: Position of this High Voltage Energy Storage Pack instance negative side bus contactor. When this contactor is closed, the negative side of this HVES instance is connected to the negative side of t...";
CM_ SG_ 2364688638 HVESP10HghVltgBsDsnntFrwrnng "HVESP10 High-Voltage Bus Disconnect Forewarning: Indicates that this High Voltage Energy Storage Pack instance is about to disconnect from the high voltage bus due to unacceptable conditions.This parameter is for one of multiple packs in an HVESS. If...";
CM_ SG_ 2364688638 HVESP10HghVltgBsPrChrgRlStt "HVESP10 High-Voltage Bus Pre-Charge Relay State: Position of the high-voltage bus contactor pre-charge relay.  When this relay is closed, this High Voltage Energy Storage Pack instance is bringing the high-voltage bus up to its operating level.This p...";
CM_ SG_ 2364688638 HVESP10CntrfPkCnttrStt "HVESP10 Center of Pack Contactor State: Position of the center high-voltage contactor. When this contactor is closed, the positive half of this High Voltage Energy Storage Pack instance is connected to the negative half. If a system controls the posi...";
CM_ SG_ 2364688638 HVESP10HghVltgBsAtvIsltnTstStts "HVESP10 High-Voltage Bus Active Isolation Test Status: Status of the high-voltage bus electrical active isolation test as performed by this High Voltage Energy Storage Pack instance.This parameter is for one of multiple packs in an HVESS. If there is...";
CM_ SG_ 2364688638 HVESP10HVtBsPssvIstTstStts "HVESP10 High-Voltage Bus Passive Isolation Test Status: Status of the high-voltage bus electrical passive isolation test as performed by this High Voltage Energy Storage Pack instance.This parameter is for one of multiple packs in an HVESS. If there ...";
CM_ SG_ 2364688638 HVESP10HVILStatus "HVESP10 HVIL Status: Status of the High Voltage Interlock Loop from the viewpoint of this High Voltage Energy Storage Pack instance.This parameter is for one of multiple packs in an HVESS. If there is only one pack in the system, the HVESS parameters...";
CM_ SG_ 2364688638 HVESP10InertiaSwitchStatus "HVESP10 Inertia Switch Status: Switch indicating that an impact has been sensed by this High Voltage Energy Storage Pack instance. The impact indication may require action by another controller, or by this HVES instance itself.  For example, a contro...";
CM_ SG_ 2364688638 HVESP10StateofChargeStatus "HVESP10 State of Charge Status: Status of this High Voltage Energy Storage Pack instance State of Charge (SOC).  Note:  A given HVES controller may not support all of the states.This parameter is for one of multiple packs in an HVESS.  If there is on...";
CM_ SG_ 2364688638 HVESP10CellBalanceStatus "HVESP10 Cell Balance Status: Indicates whether or not the cells in this High Voltage Energy Storage Pack instance are balanced.This parameter is for one of multiple packs in an HVESS.  If there is only one pack in the system, the HVESS parameters sho...";
CM_ SG_ 2364688638 HVESP10CellBalancingActive "HVESP10 Cell Balancing Active: Indicates whether or not the cells in this High Voltage Energy Storage Pack instance are currently being balanced.This parameter is for one of multiple packs in an HVESS.  If there is only one pack in the system, the HV...";
CM_ SG_ 2364688638 HVESP10InternalChargerStatus "HVESP10 Internal Charger Status: Indicates that the charger in this HVES instance is on.  External chargers may use the External Energy Source Connection Status (SPN 7898) and related SPs.This parameter is for one of multiple packs in an HVESS. If th...";
CM_ SG_ 2364688638 HVESP10HghVltgBsCnntnStts "HVESP10 High-Voltage Bus Connection Status: This parameter provides high level feedback on this High Voltage Energy Storage Pack instance high voltage bus connection. For specific contactor information, see SPN 14514 (HVESP10 High-Voltage Bus (Positi...";
CM_ SG_ 2364688638 HVESP10OperationalStatus "HVESP10 Operational Status: Provides feedback on where this High Voltage Energy Storage Pack instance is in its operating spectrum, and includes feedback in response to the Operation Consent [i.e. SPN 14472 (HVESP10 Operation Consent)] and Power Down...";
CM_ SG_ 2364688638 HVESP10Status1Counter "HVESP10 Status 1 Counter: The message counter is used to detect situations where the transmitting ECU malfunction repeats the same frame all the time. The receiver of the information may use the counter parameter to detect this situation. The transmi...";
CM_ SG_ 2364688638 HVESP10Status1CRC "HVESP10 Status 1 CRC: The CRC is defined as follows: • Length: 8 bits • Polynomial: x^8+x^5+x^3+x^2+x+1 • Initial Value: FFh • Input Data Reflection: Not reflected • Result Data Reflection: Not reflected • XOR value: FFhSAE makes no claim of the func...";
CM_ BO_ 2364688894 "High Voltage Energy Storage Pack 10 Data 7";
CM_ SG_ 2364688894 HVESP10DischargeEnergyCapacity "HVESP10 Discharge Energy Capacity: The amount of stored electrical energy in this High Voltage Energy Storage Pack instance that is available for use by the hybrid system, i.e. “how full is the tank”. See SPN 14501 (HVESP10 Discharge Capacity) for Am...";
CM_ SG_ 2364688894 HVESP10ChargeEnergyCapacity "HVESP10 Charge Energy Capacity: The amount of unused electrical energy storage available to be filled by charging this High Voltage Energy Storage Pack instance, i.e. “how much empty space is remaining in the tank”. See SPN 14502 (HVESP10 Charge Capa...";
CM_ SG_ 2364688894 HVESP10MxmmChrgVltgLmt "HVESP10 Maximum Charge Voltage Limit: The maximum voltage level not to be exceeded while charging this High Voltage Energy Storage Pack instance. If this parameter is not supported, the maximum charge voltage should be limited to SPN 14602 (HVESP10 R...";
CM_ BO_ 2364689150 "High Voltage Energy Storage Pack 10 Module Status 1";
CM_ SG_ 2364689150 HVESP10Module1OperationalStatus "HVESP10 Module 1 Operational Status: Operational Status of Module 1 in this High Voltage Energy Storage Pack Instance.  Not Operational is used when the module is initializing or not able to function (e.g. internal module level monitors have failed)....";
CM_ SG_ 2364689150 HVESP10Module2OperationalStatus "HVESP10 Module 2 Operational Status: Operational Status of Module 2 in this High Voltage Energy Storage Pack Instance.  Not Operational is used when the module is initializing or not able to function (e.g. internal module level monitors have failed)....";
CM_ SG_ 2364689150 HVESP10Module3OperationalStatus "HVESP10 Module 3 Operational Status: Operational Status of Module 3 in this High Voltage Energy Storage Pack Instance.  Not Operational is used when the module is initializing or not able to function (e.g. internal module level monitors have failed)....";
CM_ SG_ 2364689150 HVESP10Module4OperationalStatus "HVESP10 Module 4 Operational Status: Operational Status of Module 4 in this High Voltage Energy Storage Pack Instance.  Not Operational is used when the module is initializing or not able to function (e.g. internal module level monitors have failed)....";
CM_ SG_ 2364689150 HVESP10Module5OperationalStatus "HVESP10 Module 5 Operational Status: Operational Status of Module 5 in this High Voltage Energy Storage Pack Instance.  Not Operational is used when the module is initializing or not able to function (e.g. internal module level monitors have failed)....";
CM_ SG_ 2364689150 HVESP10Module6OperationalStatus "HVESP10 Module 6 Operational Status: Operational Status of Module 6 in this High Voltage Energy Storage Pack Instance.  Not Operational is used when the module is initializing or not able to function (e.g. internal module level monitors have failed)....";
CM_ SG_ 2364689150 HVESP10Module7OperationalStatus "HVESP10 Module 7 Operational Status: Operational Status of Module 7 in this High Voltage Energy Storage Pack Instance.  Not Operational is used when the module is initializing or not able to function (e.g. internal module level monitors have failed)....";
CM_ SG_ 2364689150 HVESP10Module8OperationalStatus "HVESP10 Module 8 Operational Status: Operational Status of Module 8 in this High Voltage Energy Storage Pack Instance.  Not Operational is used when the module is initializing or not able to function (e.g. internal module level monitors have failed)....";
CM_ SG_ 2364689150 HVESP10Module9OperationalStatus "HVESP10 Module 9 Operational Status: Operational Status of Module 9 in this High Voltage Energy Storage Pack Instance.  Not Operational is used when the module is initializing or not able to function (e.g. internal module level monitors have failed)....";
CM_ SG_ 2364689150 HVESP10Mdl10OprtnlStts "HVESP10 Module 10 Operational Status: Operational Status of Module 10 in this High Voltage Energy Storage Pack Instance.  Not Operational is used when the module is initializing or not able to function (e.g. internal module level monitors have failed...";
CM_ SG_ 2364689150 HVESP10Mdl11OprtnlStts "HVESP10 Module 11 Operational Status: Operational Status of Module 11 in this High Voltage Energy Storage Pack Instance.  Not Operational is used when the module is initializing or not able to function (e.g. internal module level monitors have failed...";
CM_ SG_ 2364689150 HVESP10Mdl12OprtnlStts "HVESP10 Module 12 Operational Status: Operational Status of Module 12 in this High Voltage Energy Storage Pack Instance.  Not Operational is used when the module is initializing or not able to function (e.g. internal module level monitors have failed...";
CM_ SG_ 2364689150 HVESP10Mdl13OprtnlStts "HVESP10 Module 13 Operational Status: Operational Status of Module 13 in this High Voltage Energy Storage Pack Instance.  Not Operational is used when the module is initializing or not able to function (e.g. internal module level monitors have failed...";
CM_ SG_ 2364689150 HVESP10Mdl14OprtnlStts "HVESP10 Module 14 Operational Status: Operational Status of Module 14 in this High Voltage Energy Storage Pack Instance.  Not Operational is used when the module is initializing or not able to function (e.g. internal module level monitors have failed...";
CM_ SG_ 2364689150 HVESP10Mdl15OprtnlStts "HVESP10 Module 15 Operational Status: Operational Status of Module 15 in this High Voltage Energy Storage Pack Instance.  Not Operational is used when the module is initializing or not able to function (e.g. internal module level monitors have failed...";
CM_ SG_ 2364689150 HVESP10Mdl16OprtnlStts "HVESP10 Module 16 Operational Status: Operational Status of Module 16 in this High Voltage Energy Storage Pack Instance.  Not Operational is used when the module is initializing or not able to function (e.g. internal module level monitors have failed...";
CM_ SG_ 2364689150 HVESP10Mdl17OprtnlStts "HVESP10 Module 17 Operational Status: Operational Status of Module 17 in this High Voltage Energy Storage Pack Instance.  Not Operational is used when the module is initializing or not able to function (e.g. internal module level monitors have failed...";
CM_ SG_ 2364689150 HVESP10Mdl18OprtnlStts "HVESP10 Module 18 Operational Status: Operational Status of Module 18 in this High Voltage Energy Storage Pack Instance.  Not Operational is used when the module is initializing or not able to function (e.g. internal module level monitors have failed...";
CM_ SG_ 2364689150 HVESP10Mdl19OprtnlStts "HVESP10 Module 19 Operational Status: Operational Status of Module 19 in this High Voltage Energy Storage Pack Instance.  Not Operational is used when the module is initializing or not able to function (e.g. internal module level monitors have failed...";
CM_ SG_ 2364689150 HVESP10Mdl20OprtnlStts "HVESP10 Module 20 Operational Status: Operational Status of Module 20 in this High Voltage Energy Storage Pack Instance.  Not Operational is used when the module is initializing or not able to function (e.g. internal module level monitors have failed...";
CM_ SG_ 2364689150 HVESP10Mdl21OprtnlStts "HVESP10 Module 21 Operational Status: Operational Status of Module 21 in this High Voltage Energy Storage Pack Instance.  Not Operational is used when the module is initializing or not able to function (e.g. internal module level monitors have failed...";
CM_ SG_ 2364689150 HVESP10Mdl22OprtnlStts "HVESP10 Module 22 Operational Status: Operational Status of Module 22 in this High Voltage Energy Storage Pack Instance.  Not Operational is used when the module is initializing or not able to function (e.g. internal module level monitors have failed...";
CM_ SG_ 2364689150 HVESP10Mdl23OprtnlStts "HVESP10 Module 23 Operational Status: Operational Status of Module 23 in this High Voltage Energy Storage Pack Instance.  Not Operational is used when the module is initializing or not able to function (e.g. internal module level monitors have failed...";
CM_ SG_ 2364689150 HVESP10Mdl24OprtnlStts "HVESP10 Module 24 Operational Status: Operational Status of Module 24 in this High Voltage Energy Storage Pack Instance.  Not Operational is used when the module is initializing or not able to function (e.g. internal module level monitors have failed...";
CM_ SG_ 2364689150 HVESP10Mdl25OprtnlStts "HVESP10 Module 25 Operational Status: Operational Status of Module 25 in this High Voltage Energy Storage Pack Instance.  Not Operational is used when the module is initializing or not able to function (e.g. internal module level monitors have failed...";
CM_ SG_ 2364689150 HVESP10Mdl26OprtnlStts "HVESP10 Module 26 Operational Status: Operational Status of Module 26 in this High Voltage Energy Storage Pack Instance.  Not Operational is used when the module is initializing or not able to function (e.g. internal module level monitors have failed...";
CM_ SG_ 2364689150 HVESP10Mdl27OprtnlStts "HVESP10 Module 27 Operational Status: Operational Status of Module 27 in this High Voltage Energy Storage Pack Instance.  Not Operational is used when the module is initializing or not able to function (e.g. internal module level monitors have failed...";
CM_ SG_ 2364689150 HVESP10Mdl28OprtnlStts "HVESP10 Module 28 Operational Status: Operational Status of Module 28 in this High Voltage Energy Storage Pack Instance.  Not Operational is used when the module is initializing or not able to function (e.g. internal module level monitors have failed...";
CM_ SG_ 2364689150 HVESP10Mdl29OprtnlStts "HVESP10 Module 29 Operational Status: Operational Status of Module 29 in this High Voltage Energy Storage Pack Instance.  Not Operational is used when the module is initializing or not able to function (e.g. internal module level monitors have failed...";
CM_ SG_ 2364689150 HVESP10Mdl30OprtnlStts "HVESP10 Module 30 Operational Status: Operational Status of Module 30 in this High Voltage Energy Storage Pack Instance.  Not Operational is used when the module is initializing or not able to function (e.g. internal module level monitors have failed...";
CM_ SG_ 2364689150 HVESP10Mdl31OprtnlStts "HVESP10 Module 31 Operational Status: Operational Status of Module 31 in this High Voltage Energy Storage Pack Instance.  Not Operational is used when the module is initializing or not able to function (e.g. internal module level monitors have failed...";
CM_ SG_ 2364689150 HVESP10Mdl32OprtnlStts "HVESP10 Module 32 Operational Status: Operational Status of Module 32 in this High Voltage Energy Storage Pack Instance.  Not Operational is used when the module is initializing or not able to function (e.g. internal module level monitors have failed...";
CM_ BO_ 2364689406 "High Voltage Energy Storage Pack 10 Thermal Management System Status 1";
CM_ SG_ 2364689406 HVESP10TMtSstSLIIptPw "HVESP10 Thermal Management System SLI Input Power: This is the low-voltage power consumed by this HVES Thermal Management System (TMS).This parameter is for one of multiple packs in an HVESS.  If there is only one pack in the system, the HVESS parame...";
CM_ SG_ 2364689406 HVESP10TMtSstHVtIptPw "HVESP10 Thermal Management System High-Voltage Input Power: This is the high-voltage power consumed by this HVES Thermal Management System (TMS).This parameter is for one of multiple packs in an HVESS.  If there is only one pack in the system, the HV...";
CM_ SG_ 2364689406 HVESP10TMtSstCpssSpd "HVESP10 Thermal Management System Compressor Speed: When this High Voltage Energy Storage Pack Thermal Management System is equipped with an active cooling system (e.g. air conditioner), this is the Compressor Speed.This parameter is for one of multi...";
CM_ SG_ 2364689406 HVESP10ThrmlMngmntSstmRltvHmdt "HVESP10 Thermal Management System Relative Humidty: When this High Voltage Energy Storage Pack Thermal Management System is equipped with a relative humidity sensor, this is the  measured Relative Humidity.This parameter is for one of multiple packs ...";
CM_ SG_ 2364689406 HVESP10ThrmlMngmntSstmHtrStts "HVESP10 Thermal Management System Heater Status: The state of this High Voltage Energy Storage Pack heaterThis parameter is for one of multiple packs in an HVESS.  If there is only one pack in the system, the HVESS parameters should be used. If there...";
CM_ SG_ 2364689406 HVESP10ThrmlMngmntSstmHVILStts "HVESP10 Thermal Management System HVIL Status: In multiple HVES configurations, this is the status of the High Voltage Interlock Loop from the viewpoint of this Thermal Management System.00b = HVIL Closed01b = HVIL Open10b = Error11b = Not AvailableT...";
CM_ SG_ 2364689406 HVESP10ThrmlMngmntSstmMd "HVESP10 Thermal Management System Mode: Indicates the operating mode of the Thermal Management System.  The heat transfer medium may be (e.g. liquid or air).  The cooling system may be fans, liquid coolant, or a combination of mediums.  The system ma...";
CM_ SG_ 2364689406 HVESP10ThrmlMngmntSstmClntLvl "HVESP10 Thermal Management System Coolant Level: Indicates the coolant level in this HVES Thermal Management System (TMS).This parameter is for one of multiple packs in an HVESS.  If there is only one pack in the system, the HVESS parameters should b...";
CM_ BO_ 2364689662 "High Voltage Energy Storage Pack 10 Data 8";
CM_ SG_ 2364689662 HVESP10HghstCllVltgMdlNmr "HVESP10 Highest Cell Voltage Module Number: Identifies the location of the module containing SPN 14494 (HVESP10 Highest Cell Voltage).This parameter is for one of multiple packs in an HVESS. If there is only one pack in the system, the HVESS paramete...";
CM_ SG_ 2364689662 HVESP10HghstCllVltgCllNmr "HVESP10 Highest Cell Voltage Cell Number: Identifies the location of SPN 14494 (HVESP10 Highest Cell Voltage) within SPN 14574 (HVESP10 Highest Cell Voltage Module Number).This parameter is for one of multiple packs in an HVESS. If there is only one ...";
CM_ SG_ 2364689662 HVESP10LwstCllVltgMdlNmr "HVESP10 Lowest Cell Voltage Module Number: Identifies the location of the module containing SPN 14495 (HVESP10 Lowest Cell Voltage).This parameter is for one of multiple packs in an HVESS. If there is only one pack in the system, the HVESS parameters...";
CM_ SG_ 2364689662 HVESP10LwstCllVltgCllNmr "HVESP10 Lowest Cell Voltage Cell Number: Identifies the location of SPN 14495 (HVESP10 Lowest Cell Voltage) within SPN 14576 (HVESP10 Lowest Cell Voltage Module Number).This parameter is for one of multiple packs in an HVESS. If there is only one pac...";
CM_ SG_ 2364689662 HVESP10AverageCellVoltage "HVESP10 Average Cell Voltage: The average cell voltage in this High Voltage Energy Storage Pack instance.This parameter is for one of multiple packs in an HVESS.  If there is only one pack in the system, the HVESS parameters should be used. If there ...";
CM_ BO_ 2364689918 "High Voltage Energy Storage Pack 10 Data 9";
CM_ SG_ 2364689918 HVESP10HghstCllTmprtrMdlNmr "HVESP10 Highest Cell Temperature Module Number: Identifies the location of the module containing SPN 14497 (HVESP10 Highest Cell Temperature).This parameter is for one of multiple packs in an HVESS. If there is only one pack in the system, the HVESS ...";
CM_ SG_ 2364689918 HVESP10HghstCllTmprtrCllNmr "HVESP10 Highest Cell Temperature Cell Number: Identifies the location of SPN 14497 (HVESP10 Highest Cell Temperature) within SPN 14579 (HVESP10 Highest Cell Temperature Module Number).This parameter is for one of multiple packs in an HVESS. If there ...";
CM_ SG_ 2364689918 HVESP10LwstCllTmprtrMdlNmr "HVESP10 Lowest Cell Temperature Module Number: Identifies the location of the module containing SPN 14498 (HVESP10 Lowest Cell Temperature).This parameter is for one of multiple packs in an HVESS. If there is only one pack in the system, the HVESS pa...";
CM_ SG_ 2364689918 HVESP10LwstCllTmprtrCllNmr "HVESP10 Lowest Cell Temperature Cell Number: Identifies the location of SPN 14498 (HVESP10 Lowest Cell Temperature) within SPN 14581 (HVESP10 Lowest Cell Temperature Module Number).This parameter is for one of multiple packs in an HVESS. If there is ...";
CM_ BO_ 2364690174 "High Voltage Energy Storage Pack 10 Data 10";
CM_ SG_ 2364690174 HVESP10HghstCllSttfChrgMdlNmr "HVESP10 Highest Cell State of Charge Module Number: Identifies the location of the module containing SPN 14507 (HVESP10 Highest Cell State of Charge).This parameter is for one of multiple packs in an HVESS. If there is only one pack in the system, th...";
CM_ SG_ 2364690174 HVESP10HghstCllSttfChrgCllNmr "HVESP10 Highest Cell State of Charge Cell Number: Identifies the location of SPN 14507 (HVESP10 Highest Cell State of Charge) within SPN 14583 (HVESP10 Highest Cell State of Charge Module Number).This parameter is for one of multiple packs in an HVES...";
CM_ SG_ 2364690174 HVESP10LwstCllSttfChrgMdlNmr "HVESP10 Lowest Cell State of Charge Module Number: Identifies the location of the module containing SPN 14506 (HVESP10 Lowest Cell State of Charge).This parameter is for one of multiple packs in an HVESS. If there is only one pack in the system, the ...";
CM_ SG_ 2364690174 HVESP10LwstCllSttfChrgCllNmr "HVESP10 Lowest Cell State of Charge Cell Number: Identifies the location of SPN 14506 (HVESP10 Lowest Cell State of Charge) within SPN 14585 (HVESP10 Lowest Cell State of Charge Module Number).This parameter is for one of multiple packs in an HVESS. ...";
CM_ SG_ 2364690174 HVESP10HVtBsAtvIstTstRsts "HVESP10 High-Voltage Bus Active Isolation Test Results: The isolation resistance expressed in Ohms per Volt that resulted from the High-Voltage Bus Active Isolation Test.See SPN 14519 (HVESP10 High-Voltage Bus Active Isolation Test Status) for test s...";
CM_ SG_ 2364690174 HVESP10HVtBsPssvIstTstRsts "HVESP10 High-Voltage Bus Passive Isolation Test Results: The isolation resistance expressed in Ohms per Volt that resulted from the High-Voltage Bus Passive Isolation Test.See SPN 14520 (HVESP10 High-Voltage Bus Passive Isolation Test Status) for tes...";
CM_ BO_ 2364690430 "High Voltage Energy Storage Pack 10 Data 11";
CM_ SG_ 2364690430 HVESP10BsVltgNgtvtChsssGrndVltg "HVESP10 Bus Voltage Negative to Chassis Ground Voltage: Voltage difference between the most negative terminal of the HVES battery and chassis measured on the hybrid system bus side (not the battery side) of any HVES contained output contactor.  This ...";
CM_ SG_ 2364690430 HVESP10VtLvNtvtCsssGdVt "HVESP10 Voltage Level Negative to Chassis Ground Voltage: Voltage difference between the most negative terminal of the HVES battery and chassis measured at the battery side of any HVES contained output contactor.  This voltage may be used for system ...";
CM_ SG_ 2364690430 HVESP10ActualChargeRate "HVESP10 Actual Charge Rate: This signal represents the actual present charge rate of this High Voltage Energy Storage Pack instance.This parameter is for one of multiple packs in an HVESS. If there is only one pack in the system, the HVESS parameters...";
CM_ BO_ 2566564862 "High Voltage Energy Storage Pack 10 Configuration";
CM_ SG_ 2566564862 HVESP10NominalVoltage "HVESP10 Nominal Voltage: Per the HVES manufacturer, this is the nominal operating voltage of this High Voltage Energy Storage Pack instance, e.g. “300V” or “600V”.This parameter is for one of multiple packs in an HVESS.  If there is only one pack in ...";
CM_ SG_ 2566564862 HVESP10RmmnddMnmmOprtngVltg "HVESP10 Recommended Minimum Operating Voltage: Per the HVES manufacturer, this is the minimum recommended voltage level for this High Voltage Energy Storage Pack instance operation.  Operating below this value may compromise HVES life.This parameter ...";
CM_ SG_ 2566564862 HVESP10RmmnddMxmmOprtngVltg "HVESP10 Recommended Maximum Operating Voltage: Per the HVES manufacturer, this is the maximum recommended voltage level for this High Voltage Energy Storage Pack instance operation.  Operating above this value may compromise HVES life.This parameter ...";
CM_ SG_ 2566564862 HVESP10RmmnddMnmmSttOfChrg "HVESP10 Recommended Minimum State Of Charge: Per the HVES manufacturer, this is the recommended minimum state of charge for this High Voltage Energy Storage Pack instance operation.  Operating below this value may compromise HVES life.This parameter ...";
CM_ SG_ 2566564862 HVESP10RmmnddMxmmSttOfChrg "HVESP10 Recommended Maximum State Of Charge: Per the HVES manufacturer, this is the recommended maximum state of charge for this High Voltage Energy Storage Pack instance operation.  Operating above this value may compromise HVES life.This parameter ...";
CM_ SG_ 2566564862 HVESP10RmmnddMxmmOprtngTmprtr "HVESP10 Recommended Maximum Operating Temperature: Per the HVES manufacturer, this is the recommended maximum temperature for this High Voltage Energy Storage Pack instance operation.  Operating above this value may damage HVES hardware, or compromis...";
CM_ SG_ 2566564862 HVESP10RmmnddMnmmOprtngTmprtr "HVESP10 Recommended Minimum Operating Temperature: Per the HVES manufacturer, this is the recommended minimum temperature for this High Voltage Energy Storage Pack instance operation.  Operating below this value may damage HVES hardware, or compromis...";
CM_ SG_ 2566564862 HVESP10CellMaximumVoltageLimit "HVESP10 Cell Maximum Voltage Limit: Per the HVES manufacturer, this is the maximum cell voltage for this High Voltage Energy Storage Pack instance operation.  Operating above this value may damage HVES hardware, or compromise HVES life.This parameter...";
CM_ SG_ 2566564862 HVESP10CellMinimumVoltageLimit "HVESP10 Cell Minimum Voltage Limit: Per the HVES manufacturer, this is the minimum cell voltage for this High Voltage Energy Storage Pack instance operation.  Operating below this value may damage HVES hardware, or compromise HVES life.This parameter...";
CM_ BO_ 2633673982 "High Voltage Energy Storage Pack 10 History";
CM_ SG_ 2633673982 HVESP10StateofHealth "HVESP10 State of Health: This signal represents the expected remaining Life of this High Voltage Energy Storage Pack instance, in percent.  Battery life is a manufacturer-specific measure of how well the energy storage system is functioning relative ...";
CM_ SG_ 2633673982 HVESP10CnttrOpnUndrLdCnt "HVESP10 Contactor Open Under Load Count: This signal represents the number of times the contactors inside this High Voltage Energy Storage Pack instance have opened while current is flowing through them.  The current level (that determines if an open...";
CM_ SG_ 2633673982 HVESP10TotalEnergyThroughput "HVESP10 Total Energy Throughput: The total energy throughput which has flowed through this High Voltage Energy Storage Pack instance.  This parameter is the sum of the absolute values of the Energy into and out of this HVES instance.  This parameter ...";
CM_ SG_ 2633673982 HVESP10TotalAccumulatedCharge "HVESP10 Total Accumulated Charge: The total accumulated amp hours which have flowed through this High Voltage Energy Storage Pack instance.  This parameter is the sum of the absolute values of the Ampere hours into and out of this HVES instance.  Thi...";
CM_ SG_ 2633673982 HVESP10TotalLifetimeEnergyInput "HVESP10 Total Lifetime Energy Input: The cumulative energy which has flowed into this High Voltage Energy Storage Pack instance over the lifetime of the battery pack. This parameter is the sum of the Energy into this HVES instance. This value is rese...";
CM_ SG_ 2633673982 HVESP10TtlLftmEnrgOtpt "HVESP10 Total Lifetime Energy Output: The cumulative energy which has flowed out of this High Voltage Energy Storage Pack instance over the lifetime of the battery pack. This parameter is the sum of the Energy out of this HVES instance. This value is...";
CM_ BO_ 2566565374 "High Voltage Energy Storage Pack 9 Configuration";
CM_ SG_ 2566565374 HVESP9NominalVoltage "HVESP9 Nominal Voltage: Per the HVES manufacturer, this is the nominal operating voltage of this High Voltage Energy Storage Pack instance, e.g. “300V” or “600V”.This parameter is for one of multiple packs in an HVESS.  If there is only one pack in t...";
CM_ SG_ 2566565374 HVESP9RmmnddMnmmOprtngVltg "HVESP9 Recommended Minimum Operating Voltage: Per the HVES manufacturer, this is the minimum recommended voltage level for this High Voltage Energy Storage Pack instance operation.  Operating below this value may compromise HVES life.This parameter i...";
CM_ SG_ 2566565374 HVESP9RmmnddMxmmOprtngVltg "HVESP9 Recommended Maximum Operating Voltage: Per the HVES manufacturer, this is the maximum recommended voltage level for this High Voltage Energy Storage Pack instance operation.  Operating above this value may compromise HVES life.This parameter i...";
CM_ SG_ 2566565374 HVESP9RmmnddMnmmSttOfChrg "HVESP9 Recommended Minimum State Of Charge: Per the HVES manufacturer, this is the recommended minimum state of charge for this High Voltage Energy Storage Pack instance operation.  Operating below this value may compromise HVES life.This parameter i...";
CM_ SG_ 2566565374 HVESP9RmmnddMxmmSttOfChrg "HVESP9 Recommended Maximum State Of Charge: Per the HVES manufacturer, this is the recommended maximum state of charge for this High Voltage Energy Storage Pack instance operation.  Operating above this value may compromise HVES life.This parameter i...";
CM_ SG_ 2566565374 HVESP9RmmnddMxmmOprtngTmprtr "HVESP9 Recommended Maximum Operating Temperature: Per the HVES manufacturer, this is the recommended maximum temperature for this High Voltage Energy Storage Pack instance operation.  Operating above this value may damage HVES hardware, or compromise...";
CM_ SG_ 2566565374 HVESP9RmmnddMnmmOprtngTmprtr "HVESP9 Recommended Minimum Operating Temperature: Per the HVES manufacturer, this is the recommended minimum temperature for this High Voltage Energy Storage Pack instance operation.  Operating below this value may damage HVES hardware, or compromise...";
CM_ SG_ 2566565374 HVESP9CellMaximumVoltageLimit "HVESP9 Cell Maximum Voltage Limit: Per the HVES manufacturer, this is the maximum cell voltage for this High Voltage Energy Storage Pack instance operation.  Operating above this value may damage HVES hardware, or compromise HVES life.This parameter ...";
CM_ SG_ 2566565374 HVESP9CellMinimumVoltageLimit "HVESP9 Cell Minimum Voltage Limit: Per the HVES manufacturer, this is the minimum cell voltage for this High Voltage Energy Storage Pack instance operation.  Operating below this value may damage HVES hardware, or compromise HVES life.This parameter ...";
CM_ BO_ 2633674494 "High Voltage Energy Storage Pack 9 History";
CM_ SG_ 2633674494 HVESP9StateofHealth "HVESP9 State of Health: This signal represents the expected remaining Life of this High Voltage Energy Storage Pack instance, in percent.  Battery life is a manufacturer-specific measure of how well the energy storage system is functioning relative t...";
CM_ SG_ 2633674494 HVESP9CnttrOpnUndrLdCnt "HVESP9 Contactor Open Under Load Count: This signal represents the number of times the contactors inside this High Voltage Energy Storage Pack instance have opened while current is flowing through them.  The current level (that determines if an openi...";
CM_ SG_ 2633674494 HVESP9TotalEnergyThroughput "HVESP9 Total Energy Throughput: The total energy throughput which has flowed through this High Voltage Energy Storage Pack instance.  This parameter is the sum of the absolute values of the Energy into and out of this HVES instance.  This parameter i...";
CM_ SG_ 2633674494 HVESP9TotalAccumulatedCharge "HVESP9 Total Accumulated Charge: The total accumulated amp hours which have flowed through this High Voltage Energy Storage Pack instance.  This parameter is the sum of the absolute values of the Ampere hours into and out of this HVES instance.  This...";
CM_ SG_ 2633674494 HVESP9TotalLifetimeEnergyInput "HVESP9 Total Lifetime Energy Input: The cumulative energy which has flowed into this High Voltage Energy Storage Pack instance over the lifetime of the battery pack. This parameter is the sum of the Energy into this HVES instance. This value is reset...";
CM_ SG_ 2633674494 HVESP9TotalLifetimeEnergyOutput "HVESP9 Total Lifetime Energy Output: The cumulative energy which has flowed out of this High Voltage Energy Storage Pack instance over the lifetime of the battery pack. This parameter is the sum of the Energy out of this HVES instance. This value is ...";
CM_ BO_ 2566565886 "High Voltage Energy Storage Pack 8 Configuration";
CM_ SG_ 2566565886 HVESP8NominalVoltage "HVESP8 Nominal Voltage: Per the HVES manufacturer, this is the nominal operating voltage of this High Voltage Energy Storage Pack instance, e.g. “300V” or “600V”.This parameter is for one of multiple packs in an HVESS.  If there is only one pack in t...";
CM_ SG_ 2566565886 HVESP8RmmnddMnmmOprtngVltg "HVESP8 Recommended Minimum Operating Voltage: Per the HVES manufacturer, this is the minimum recommended voltage level for this High Voltage Energy Storage Pack instance operation.  Operating below this value may compromise HVES life.This parameter i...";
CM_ SG_ 2566565886 HVESP8RmmnddMxmmOprtngVltg "HVESP8 Recommended Maximum Operating Voltage: Per the HVES manufacturer, this is the maximum recommended voltage level for this High Voltage Energy Storage Pack instance operation.  Operating above this value may compromise HVES life.This parameter i...";
CM_ SG_ 2566565886 HVESP8RmmnddMnmmSttOfChrg "HVESP8 Recommended Minimum State Of Charge: Per the HVES manufacturer, this is the recommended minimum state of charge for this High Voltage Energy Storage Pack instance operation.  Operating below this value may compromise HVES life.This parameter i...";
CM_ SG_ 2566565886 HVESP8RmmnddMxmmSttOfChrg "HVESP8 Recommended Maximum State Of Charge: Per the HVES manufacturer, this is the recommended maximum state of charge for this High Voltage Energy Storage Pack instance operation.  Operating above this value may compromise HVES life.This parameter i...";
CM_ SG_ 2566565886 HVESP8RmmnddMxmmOprtngTmprtr "HVESP8 Recommended Maximum Operating Temperature: Per the HVES manufacturer, this is the recommended maximum temperature for this High Voltage Energy Storage Pack instance operation.  Operating above this value may damage HVES hardware, or compromise...";
CM_ SG_ 2566565886 HVESP8RmmnddMnmmOprtngTmprtr "HVESP8 Recommended Minimum Operating Temperature: Per the HVES manufacturer, this is the recommended minimum temperature for this High Voltage Energy Storage Pack instance operation.  Operating below this value may damage HVES hardware, or compromise...";
CM_ SG_ 2566565886 HVESP8CellMaximumVoltageLimit "HVESP8 Cell Maximum Voltage Limit: Per the HVES manufacturer, this is the maximum cell voltage for this High Voltage Energy Storage Pack instance operation.  Operating above this value may damage HVES hardware, or compromise HVES life.This parameter ...";
CM_ SG_ 2566565886 HVESP8CellMinimumVoltageLimit "HVESP8 Cell Minimum Voltage Limit: Per the HVES manufacturer, this is the minimum cell voltage for this High Voltage Energy Storage Pack instance operation.  Operating below this value may damage HVES hardware, or compromise HVES life.This parameter ...";
CM_ BO_ 2633675006 "High Voltage Energy Storage Pack 8 History";
CM_ SG_ 2633675006 HVESP8StateofHealth "HVESP8 State of Health: This signal represents the expected remaining Life of this High Voltage Energy Storage Pack instance, in percent.  Battery life is a manufacturer-specific measure of how well the energy storage system is functioning relative t...";
CM_ SG_ 2633675006 HVESP8CnttrOpnUndrLdCnt "HVESP8 Contactor Open Under Load Count: This signal represents the number of times the contactors inside this High Voltage Energy Storage Pack instance have opened while current is flowing through them.  The current level (that determines if an openi...";
CM_ SG_ 2633675006 HVESP8TotalEnergyThroughput "HVESP8 Total Energy Throughput: The total energy throughput which has flowed through this High Voltage Energy Storage Pack instance.  This parameter is the sum of the absolute values of the Energy into and out of this HVES instance.  This parameter i...";
CM_ SG_ 2633675006 HVESP8TotalAccumulatedCharge "HVESP8 Total Accumulated Charge: The total accumulated amp hours which have flowed through this High Voltage Energy Storage Pack instance.  This parameter is the sum of the absolute values of the Ampere hours into and out of this HVES instance.  This...";
CM_ SG_ 2633675006 HVESP8TotalLifetimeEnergyInput "HVESP8 Total Lifetime Energy Input: The cumulative energy which has flowed into this High Voltage Energy Storage Pack instance over the lifetime of the battery pack. This parameter is the sum of the Energy into this HVES instance. This value is reset...";
CM_ SG_ 2633675006 HVESP8TotalLifetimeEnergyOutput "HVESP8 Total Lifetime Energy Output: The cumulative energy which has flowed out of this High Voltage Energy Storage Pack instance over the lifetime of the battery pack. This parameter is the sum of the Energy out of this HVES instance. This value is ...";
CM_ BO_ 2566566398 "High Voltage Energy Storage Pack 7 Configuration";
CM_ SG_ 2566566398 HVESP7NominalVoltage "HVESP7 Nominal Voltage: Per the HVES manufacturer, this is the nominal operating voltage of this High Voltage Energy Storage Pack instance, e.g. “300V” or “600V”.This parameter is for one of multiple packs in an HVESS.  If there is only one pack in t...";
CM_ SG_ 2566566398 HVESP7RmmnddMnmmOprtngVltg "HVESP7 Recommended Minimum Operating Voltage: Per the HVES manufacturer, this is the minimum recommended voltage level for this High Voltage Energy Storage Pack instance operation.  Operating below this value may compromise HVES life.This parameter i...";
CM_ SG_ 2566566398 HVESP7RmmnddMxmmOprtngVltg "HVESP7 Recommended Maximum Operating Voltage: Per the HVES manufacturer, this is the maximum recommended voltage level for this High Voltage Energy Storage Pack instance operation.  Operating above this value may compromise HVES life.This parameter i...";
CM_ SG_ 2566566398 HVESP7RmmnddMnmmSttOfChrg "HVESP7 Recommended Minimum State Of Charge: Per the HVES manufacturer, this is the recommended minimum state of charge for this High Voltage Energy Storage Pack instance operation.  Operating below this value may compromise HVES life.This parameter i...";
CM_ SG_ 2566566398 HVESP7RmmnddMxmmSttOfChrg "HVESP7 Recommended Maximum State Of Charge: Per the HVES manufacturer, this is the recommended maximum state of charge for this High Voltage Energy Storage Pack instance operation.  Operating above this value may compromise HVES life.This parameter i...";
CM_ SG_ 2566566398 HVESP7RmmnddMxmmOprtngTmprtr "HVESP7 Recommended Maximum Operating Temperature: Per the HVES manufacturer, this is the recommended maximum temperature for this High Voltage Energy Storage Pack instance operation.  Operating above this value may damage HVES hardware, or compromise...";
CM_ SG_ 2566566398 HVESP7RmmnddMnmmOprtngTmprtr "HVESP7 Recommended Minimum Operating Temperature: Per the HVES manufacturer, this is the recommended minimum temperature for this High Voltage Energy Storage Pack instance operation.  Operating below this value may damage HVES hardware, or compromise...";
CM_ SG_ 2566566398 HVESP7CellMaximumVoltageLimit "HVESP7 Cell Maximum Voltage Limit: Per the HVES manufacturer, this is the maximum cell voltage for this High Voltage Energy Storage Pack instance operation.  Operating above this value may damage HVES hardware, or compromise HVES life.This parameter ...";
CM_ SG_ 2566566398 HVESP7CellMinimumVoltageLimit "HVESP7 Cell Minimum Voltage Limit: Per the HVES manufacturer, this is the minimum cell voltage for this High Voltage Energy Storage Pack instance operation.  Operating below this value may damage HVES hardware, or compromise HVES life.This parameter ...";
CM_ BO_ 2633675518 "High Voltage Energy Storage Pack 7 History";
CM_ SG_ 2633675518 HVESP7StateofHealth "HVESP7 State of Health: This signal represents the expected remaining Life of this High Voltage Energy Storage Pack instance, in percent.  Battery life is a manufacturer-specific measure of how well the energy storage system is functioning relative t...";
CM_ SG_ 2633675518 HVESP7CnttrOpnUndrLdCnt "HVESP7 Contactor Open Under Load Count: This signal represents the number of times the contactors inside this High Voltage Energy Storage Pack instance have opened while current is flowing through them.  The current level (that determines if an openi...";
CM_ SG_ 2633675518 HVESP7TotalEnergyThroughput "HVESP7 Total Energy Throughput: The total energy throughput which has flowed through this High Voltage Energy Storage Pack instance.  This parameter is the sum of the absolute values of the Energy into and out of this HVES instance.  This parameter i...";
CM_ SG_ 2633675518 HVESP7TotalAccumulatedCharge "HVESP7 Total Accumulated Charge: The total accumulated amp hours which have flowed through this High Voltage Energy Storage Pack instance.  This parameter is the sum of the absolute values of the Ampere hours into and out of this HVES instance.  This...";
CM_ SG_ 2633675518 HVESP7TotalLifetimeEnergyInput "HVESP7 Total Lifetime Energy Input: The cumulative energy which has flowed into this High Voltage Energy Storage Pack instance over the lifetime of the battery pack. This parameter is the sum of the Energy into this HVES instance. This value is reset...";
CM_ SG_ 2633675518 HVESP7TotalLifetimeEnergyOutput "HVESP7 Total Lifetime Energy Output: The cumulative energy which has flowed out of this High Voltage Energy Storage Pack instance over the lifetime of the battery pack. This parameter is the sum of the Energy out of this HVES instance. This value is ...";
CM_ BO_ 2566567166 "EV DC Charging Limits";
CM_ SG_ 2566567166 HybridDCChargingVoltageMaximum "Hybrid DC Charging Voltage Maximum: Hybrid or Electric Vehicle's maximum rated DC charging input voltage.This is communicated to a DC EVSE during initial exchange of parameters.When charging, the smallest value of this and SPN 13159 (EVSE DC Charging...";
CM_ SG_ 2566567166 HybridDCChargingCurrentMaximum "Hybrid DC Charging Current Maximum: Hybrid or Electric Vehicle's maximum rated DC charging input current.This is communicated to a DC EVSE during initial exchange of parameters.When charging, the smallest value of this and SPN 13160 (EVSE DC Charging...";
CM_ SG_ 2566567166 HybridDCChargingPowerMaximum "Hybrid DC Charging Power Maximum: Hybrid or Electric Vehicle's maximum rated DC charging input power.This is communicated to a DC EVSE during initial exchange of parameters.When charging, the smallest value of this and SPN 13161 (EVSE DC Charging Pow...";
CM_ SG_ 2566567166 HrdrqstdEnrgTrnsfrTp "Hybrid requested Energy Transfer Type: Hybrid  or Electric vehicle's required Energy transfer type0000b = DC-Extended0001b = DC-Core0010b to 1111b = reservedThis parameter is mandatory, one of the non-reserved values must be specified.See J2847-2 201...";
CM_ BO_ 2566567422 "EVSE 1 DC Charging Limits 1";
CM_ SG_ 2566567422 EVSEDCChargingVoltageMaximum "EVSE DC Charging Voltage Maximum: EVSE's maximum rated DC output voltage.This is communicated to the hybrid vehicle during initial exchange of parameters.When charging, the smallest value of this and SPN 13155 (Hybrid DC Charging Voltage Maximum) wil...";
CM_ SG_ 2566567422 EVSEDCChargingCurrentMaximum "EVSE DC Charging Current Maximum: EVSE's maximum rated DC output current.This is communicated to the hybrid vehicle during initial exchange of parameters.When charging, the smallest value of this and SPN 13156 (Hybrid DC Charging Current Maximum) wil...";
CM_ SG_ 2566567422 EVSEDCChargingPowerMaximum "EVSE DC Charging Power Maximum: EVSE's maximum rated DC output power.This is communicated to the hybrid vehicle during initial exchange of parameters.When charging, the smallest value of this and SPN 13157 (Hybrid DC Charging Power Maximum) will be u...";
CM_ SG_ 2566567422 EVSESpprtdEnrgTrnsfrTps "EVSE Supported Energy Transfer Types: Energy transfer types supported by the EVSE0000b = DC-Extended0001b = DC-Core0010b - 1100b reserved 1101b = No EVSE connected1110b = Error1111b = Data not availableSee J2847-2 201504 Sect 4.2.22";
CM_ BO_ 2566567678 "EVSE 1 DC Charging Limits 2";
CM_ SG_ 2566567678 EVSEDCChargingVoltageMinimum "EVSE DC Charging Voltage Minimum: Minimum stable DC output voltage that can be supplied by the EVSE.FB00h = Parameter supported, but no value provided by EVSESee J2847-2 201504 Sect 4.2.46";
CM_ SG_ 2566567678 EVSEDCChargingCurrentMinimum "EVSE DC Charging Current Minimum: Minimum stable DC output current that can be supplied by the EVSE.FB00h = Parameter supported, but no value provided by EVSESee J2847-2 201504 Sect 4.2.45";
CM_ SG_ 2566567678 EVSEPeakCurrentRipple "EVSE Peak Current Ripple: Maximum peak to peak ripple current amplitude on the EVSE output.FB00h = Parameter supported, but no value provided by EVSESee J2847-2 201504 Sect 4.2.48";
CM_ SG_ 2566567678 EVSECurrentRegulationTolerance "EVSE Current Regulation Tolerance: Regulated current tolerance of the EVSE.FB00h = Parameter supported, but no tolerance provided by EVSESee J2847-2 201504 Sect 4.2.38";
CM_ BO_ 2566567934 "EV DC Charging Target";
CM_ SG_ 2566567934 DCChargingTargetCRC "DC Charging Target CRC: 8-bit CRC covering the following bytes in this PG.The CRC is defined as follows:  • Length: 8 bits  • Polynomial: x^8+x^5+x^3+x^2+x+1  • Initial Value: FFh  • Input Data Reflection: Not reflected  • Result Data Reflection: Not...";
CM_ SG_ 2566567934 DCChargingTargetSequenceCounter "DC Charging Target Sequence Counter: The message counter is used to detect situations where the transmitting ECU malfunction repeats the same frame all the time. The receiver of the information may use the counter parameter to detect this situation. ...";
CM_ SG_ 2566567934 DCTargetChargingVoltage "DC Target Charging Voltage: Hybrid or Electric vehicle's instantaneous requested DC output voltage limit.See also: SPN 13159 (EVSE DC Charging Voltage Maximum) SPN 13163 (EVSE DC Charging Voltage Minimum) SPN 13155 (Hybrid DC Charging Voltage Maximum...";
CM_ SG_ 2566567934 DCTargetChargingCurrent "DC Target Charging Current: Hybrid or Electric vehicle's instantaneous requested DC output current limit.See also: SPN 13160 (EVSE DC Charging Current Maximum) SPN 13164 (EVSE DC Charging Current Minimum) SPN 13156 (Hybrid DC Charging Current Maximum...";
CM_ BO_ 2566568190 "EVSE 1 DC Status 1";
CM_ SG_ 2566568190 DCChargingState "DC Charging State: Overall State of the DC charging system0 = Idle. No EVSE connected.1 = Charging.2 = Standby.3-9 = reserved10 = Initialising11 = Pre-charge12 = Terminating13 = Battery failure. An error condition due to the battery state (high tempe...";
CM_ SG_ 2566568190 EVSEPresentDCChargingVoltage "EVSE Present DC Charging Voltage: High Voltage DC voltage at the output of the EVSE as measured by the EVSE FB00h = Parameter supported, but no voltage provided by EVSESee J2847-2 201504 Sect 4.2.50";
CM_ SG_ 2566568190 EVSEPresentDCChargingCurrent "EVSE Present DC Charging Current: High Voltage DC current at the output of the EVSE as measured by the EVSE FB00h = Parameter supported, but no current provided by EVSESee J2847-2 201504 Sect 4.2.51";
CM_ SG_ 2566568190 EVSEVoltageLimitAchieved "EVSE Voltage Limit Achieved: Indicates if the output voltage from the EVSE has reached the negotiated voltage limit as determined by SPN 13159 (EVSE DC Charging Voltage Maximum) and SPN 13155 (Hybrid DC Charging Voltage Maximum).00b = Not limited or ...";
CM_ SG_ 2566568190 EVSECurrentLimitAchieved "EVSE Current Limit Achieved: Indicates if the output current from the EVSE has reached the negotiated current limit as determined by SPN 13160 (EVSE DC Charging Current Maximum) and SPN 13156 (Hybrid DC Charging Current Maximum).00b = Not limited or ...";
CM_ SG_ 2566568190 EVSEPowerLimitAchieved "EVSE Power Limit Achieved: Indicates if the output power from the EVSE has reached the negotiated power limit as determined by the lower of SPN 13161 (EVSE DC Charging Power Maximum) and SPN 13157 (Hybrid DC Charging Power Maximum).00b = Not limited ...";
CM_ SG_ 2566568190 EVSEStatus "EVSE Status: Status of the DC EVSE as returned from the EVSE0 = EVSE Not Ready.1 = EVSE Ready2 = EVSE Shutdown3 = Utility Interrupt Event4 = Isolation Monitoring Active5 = Emergency Shutdown6 = Malfunction7-13 reserved14 = No EVSE Connected15 = Not a...";
CM_ BO_ 2566568446 "EVSE 1 Contactor Cmd 1";
CM_ SG_ 2566568446 HybridDCInletContactor1Command "Hybrid DC Inlet Contactor 1 Command: Contactor command.00b = Open Contactor01b = Close Contactor10b = Reserved11b = Don't Care / Take no action";
CM_ BO_ 2566568702 "EVSE 1 Contactor Status 1";
CM_ SG_ 2566568702 HybridDCContactorInputVoltage "Hybrid DC Contactor Input Voltage: Voltage measured on the inlet side of the DC Charging Inlet Contactors. If provided, this value should be in agreement with SPN 13172 (EVSE Present DC Charging Voltage).";
CM_ SG_ 2566568702 HybridDCChargingBusVoltage "Hybrid DC Charging Bus Voltage: Voltage measured on the HVES side of the DC Charging Inlet Contactors.";
CM_ SG_ 2566568702 HybridDCInletContactor1State "Hybrid DC Inlet Contactor 1 State: Indicates the state of DC Inlet Contactor 1.00b = Contactor Open01b = Contactor Closed10b = Error- Contactor fault detected11b = Not available";
CM_ BO_ 2566568958 "Direct Lamp Control Command 3";
CM_ SG_ 2566568958 TrnsmssnOlTmprtrHghLmpCmmnd "Transmission Oil Temperature High Lamp Command: Command signal directly controlling the Transmission Oil Temperature Lamp.00b = Lamp Off01b = Lamp On10b = Reserved11b = Not available";
CM_ SG_ 2566568958 TrnsmssnOlPrssrLwLmpCmmnd "Transmission Oil Pressure Low Lamp Command: Command signal directly controlling the Transmission Oil Pressure Lamp.00b = Lamp Off01b = Lamp On10b = Reserved11b = Not available";
CM_ BO_ 2566569214 "Direct Lamp Control Data 3";
CM_ SG_ 2566569214 TrnsmssnOlTmprtrHghLmpDt "Transmission Oil Temperature High Lamp Data: This parameter provides measured data from the Transmission Oil Temperature Lamp.00b = Lamp deactivated (Off)01b = Lamp activated (On)10b = Error11b = Not available";
CM_ SG_ 2566569214 TrnsmssnOlPrssrLwLmpDt "Transmission Oil Pressure Low Lamp Data: This parameter provides measured data from the Transmission Oil Pressure Lamp.00b = Lamp deactivated (Off)01b = Lamp activated (On)10b = Error11b = Not available";
CM_ BO_ 2566569470 "Motor/Generator 1 Lifetime Data";
CM_ SG_ 2566569470 MtrGnrtr1TtlEnrgCnsmd "Motor/Generator 1 Total Energy Consumed: Indicates the total lifetime energy consumed by this Motor/Generator.  For example, this would include the energy used for propulsion in a propulsion motor.";
CM_ SG_ 2566569470 MtrGnrtr1TtlEnrgGnrtd "Motor/Generator 1 Total Energy Generated : Indicates the total lifetime energy generated by this Motor/Generator.  For example, this would include the energy created during regerative braking in a propulsion motor.";
CM_ SG_ 2566569470 MtrGnrtr1TtlChrgCnsmd "Motor/Generator 1 Total Charge Consumed: Indicates the total lifetime charge consumed by this Motor/Generator.  For example, this would include the charge used for propulsion in a propulsion motor.";
CM_ SG_ 2566569470 MtrGnrtr1TtlChrgGnrtd "Motor/Generator 1 Total Charge Generated: Indicates the total lifetime charge generated by this Motor/Generator.  For example, this would include the charge created during regerative braking in a propulsion motor.";
CM_ BO_ 2566569726 "Motor/Generator 2 Lifetime Data";
CM_ SG_ 2566569726 MtrGnrtr2TtlEnrgCnsmd "Motor/Generator 2 Total Energy Consumed: Indicates the total lifetime energy consumed by this Motor/Generator.  For example, this would include the energy used for propulsion in a propulsion motor.";
CM_ SG_ 2566569726 MtrGnrtr2TtlEnrgGnrtd "Motor/Generator 2 Total Energy Generated : Indicates the total lifetime energy generated by this Motor/Generator.  For example, this would include the energy created during regerative braking in a propulsion motor.";
CM_ SG_ 2566569726 MtrGnrtr2TtlChrgCnsmd "Motor/Generator 2 Total Charge Consumed: Indicates the total lifetime charge consumed by this Motor/Generator.  For example, this would include the charge used for propulsion in a propulsion motor.";
CM_ SG_ 2566569726 MtrGnrtr2TtlChrgGnrtd "Motor/Generator 2 Total Charge Generated: Indicates the total lifetime charge generated by this Motor/Generator.  For example, this would include the charge created during regerative braking in a propulsion motor.";
CM_ BO_ 2566569982 "Motor/Generator 3 Lifetime Data";
CM_ SG_ 2566569982 MtrGnrtr3TtlEnrgCnsmd "Motor/Generator 3 Total Energy Consumed: Indicates the total lifetime energy consumed by this Motor/Generator.  For example, this would include the energy used for propulsion in a propulsion motor.";
CM_ SG_ 2566569982 MtrGnrtr3TtlEnrgGnrtd "Motor/Generator 3 Total Energy Generated : Indicates the total lifetime energy generated by this Motor/Generator.  For example, this would include the energy created during regerative braking in a propulsion motor.";
CM_ SG_ 2566569982 MtrGnrtr3TtlChrgCnsmd "Motor/Generator 3 Total Charge Consumed: Indicates the total lifetime charge consumed by this Motor/Generator.  For example, this would include the charge used for propulsion in a propulsion motor.";
CM_ SG_ 2566569982 MtrGnrtr3TtlChrgGnrtd "Motor/Generator 3 Total Charge Generated: Indicates the total lifetime charge generated by this Motor/Generator.  For example, this would include the charge created during regerative braking in a propulsion motor.";
CM_ BO_ 2566570238 "Motor/Generator 4 Lifetime Data";
CM_ SG_ 2566570238 MtrGnrtr4TtlEnrgCnsmd "Motor/Generator 4 Total Energy Consumed: Indicates the total lifetime energy consumed by this Motor/Generator.  For example, this would include the energy used for propulsion in a propulsion motor.";
CM_ SG_ 2566570238 MtrGnrtr4TtlEnrgGnrtd "Motor/Generator 4 Total Energy Generated : Indicates the total lifetime energy generated by this Motor/Generator.  For example, this would include the energy created during regerative braking in a propulsion motor.";
CM_ SG_ 2566570238 MtrGnrtr4TtlChrgCnsmd "Motor/Generator 4 Total Charge Consumed: Indicates the total lifetime charge consumed by this Motor/Generator.  For example, this would include the charge used for propulsion in a propulsion motor.";
CM_ SG_ 2566570238 MtrGnrtr4TtlChrgGnrtd "Motor/Generator 4 Total Charge Generated: Indicates the total lifetime charge generated by this Motor/Generator.  For example, this would include the charge created during regerative braking in a propulsion motor.";
CM_ BO_ 2566570494 "Motor/Generator 5 Lifetime Data";
CM_ SG_ 2566570494 MtrGnrtr5TtlEnrgCnsmd "Motor/Generator 5 Total Energy Consumed: Indicates the total lifetime energy consumed by this Motor/Generator.  For example, this would include the energy used for propulsion in a propulsion motor.";
CM_ SG_ 2566570494 MtrGnrtr5TtlEnrgGnrtd "Motor/Generator 5 Total Energy Generated : Indicates the total lifetime energy generated by this Motor/Generator.  For example, this would include the energy created during regerative braking in a propulsion motor.";
CM_ SG_ 2566570494 MtrGnrtr5TtlChrgCnsmd "Motor/Generator 5 Total Charge Consumed: Indicates the total lifetime charge consumed by this Motor/Generator.  For example, this would include the charge used for propulsion in a propulsion motor.";
CM_ SG_ 2566570494 MtrGnrtr5TtlChrgGnrtd "Motor/Generator 5 Total Charge Generated: Indicates the total lifetime charge generated by this Motor/Generator.  For example, this would include the charge created during regerative braking in a propulsion motor.";
CM_ BO_ 2566570750 "Motor/Generator 6 Lifetime Data";
CM_ SG_ 2566570750 MtrGnrtr6TtlEnrgCnsmd "Motor/Generator 6 Total Energy Consumed: Indicates the total lifetime energy consumed by this Motor/Generator.  For example, this would include the energy used for propulsion in a propulsion motor.";
CM_ SG_ 2566570750 MtrGnrtr6TtlEnrgGnrtd "Motor/Generator 6 Total Energy Generated : Indicates the total lifetime energy generated by this Motor/Generator.  For example, this would include the energy created during regerative braking in a propulsion motor.";
CM_ SG_ 2566570750 MtrGnrtr6TtlChrgCnsmd "Motor/Generator 6 Total Charge Consumed: Indicates the total lifetime charge consumed by this Motor/Generator.  For example, this would include the charge used for propulsion in a propulsion motor.";
CM_ SG_ 2566570750 MtrGnrtr6TtlChrgGnrtd "Motor/Generator 6 Total Charge Generated: Indicates the total lifetime charge generated by this Motor/Generator.  For example, this would include the charge created during regerative braking in a propulsion motor.";
CM_ BO_ 2566571006 "Air Supply Pressure 3";
CM_ SG_ 2566571006 AirDryerCartridgeLifeRemaining "Air Dryer Cartridge Life Remaining: The air dryer cartridge life remaining based on compressor air processed through the desiccant material.  100% life remaining indicates a new or fresh air dryer cartridge and 0% life remaining indicates a worn air ...";
CM_ SG_ 2566571006 AirSuspensionSupplyPressure2 "Air Suspension Supply Pressure 2: The pneumatic pressure in the second circuit for the electronically controlled air suspension system.";
CM_ BO_ 2566571262 "EVSE 1 AC Supply Voltage";
CM_ SG_ 2566571262 EVSENmnlRMSvltgLntNtrl "EVSE Nominal RMS voltage Line to Neutral: Indicates the nominal RMS voltage between contacts L1 and Neutral.For 3-phase supplies the same nominal line to neutral voltage is assumed for L2 and L3";
CM_ SG_ 2566571262 EVSENominalRMSvoltageLinetoLine "EVSE Nominal RMS voltage Line to Line: Indicates the nominal line to line RMS voltage.  For single phase supplies this is set to Not Available.";
CM_ SG_ 2566571262 EVSENominalSupplyFrequency "EVSE Nominal Supply Frequency: Indicates the supply frequency.00h = 50 Hz02h = 60 Hz03h - FDh = ReservedFEh = ErrorFFh = Not available";
CM_ BO_ 2566571518 "EVSE1 AC 3-Phase Load";
CM_ SG_ 2566571518 HVESSChargerRMScurrentL1 "HVESS Charger RMS current L1: Current presently being drawn from a single phase EVSE or from L1 of a three phase supply.";
CM_ SG_ 2566571518 HVESSChargerRMScurrentL2 "HVESS Charger RMS current L2: Current presently being drawn from L2 of a three phase supply.";
CM_ SG_ 2566571518 HVESSChargerRMScurrentL3 "HVESS Charger RMS current L3: Current presently being drawn from L3 of a three phase supply.";
CM_ SG_ 2566571518 HVESSChargerNeutralRMScurrent "HVESS Charger Neutral RMS current: Current flowing through the neutral connection.For a balanced 3-phase load this value will be set to 0 A.If the HVESS charger is only drawing single phase current between L1 and neutral then this parameter will have...";
CM_ BO_ 2499462910 "Electronic Retarder Controller 3";
CM_ SG_ 2499462910 RtrdrRdSpdDlrtSwth "Retarder Road Speed Decelerate Switch: Switch signal of the retarder road speed activator which indicates that the activator is in the position decelerate.00b = Retarder road speed activator not in the position decelerate01b = Retarder road speed act...";
CM_ SG_ 2499462910 RtrdrRdSpdAlrtSwth "Retarder Road Speed Accelerate Switch: Switch signal of the retarder road speed activator which indicates that the activator is in the position accelerate.00b = Retarder road speed activator not in the position accelerate01b = Retarder road speed act...";
CM_ BO_ 2566572286 "Electronic Transmission Controller 14";
CM_ SG_ 2566572286 TransmissionClutch1Temperature "Transmission Clutch 1 Temperature: Indicates temperature of the transmission clutch 1. This is typically the primary transmission input clutch.";
CM_ SG_ 2566572286 TrnsmssnClth1OvrhtIndtr "Transmission Clutch 1 Overheat Indicator: Signal used to indicate the transmission clutch 1 temperature is above normal acceptable limits.  Transmission clutch 1 is typically the primary transmission input clutch.00b = Clutch overheat indicator is of...";
CM_ BO_ 2499464702 "Aftertreatment 1 SCR Exhaust Gas Pressures 2";
CM_ SG_ 2499464702 Aftrtrtmnt1SCROtltAsltPrssr "Aftertreatment 1 SCR Outlet Absolute Pressure: The pressure at the catalyst outlet of the selective catalytic reduction system of aftertreatment 1.";
CM_ SG_ 2499464702 Aftrtrtmnt1SCROtltPrssr "Aftertreatment 1 SCR Outlet Pressure: The gage pressure at the outlet of the selective catalytic reduction system of Aftertreatment 1.";
CM_ BO_ 2566573822 "PTO Information 2";
CM_ SG_ 2566573822 TrnsmssnPTOGrxOtptShftSpd "Transmission PTO Gearbox Output Shaft Speed: Output shaft speed of a PTO gearbox driven by the transmission PTO.";
CM_ SG_ 2566573822 TransmissionPTOGearboxStatus "Transmission PTO Gearbox Status: Feedback from the PTO gearbox driven by the transmission PTO.0000b = Neutral0001b = 1st range, or Low in a 2-speed gearbox0010b = 2nd range, or High in a 2-speed gearbox0011b = 3rd range0100b = 4th range0101b = Reserv...";
CM_ BO_ 2364690686 "Electronic Auxiliary Transmission Controller 1";
CM_ SG_ 2364690686 AxlrTrnsmssnOtptSpd "Auxiliary Transmission Output Speed: Auxiliary transmission output speed";
CM_ BO_ 2566563326 "Duel Fuel Mode 3";
CM_ SG_ 2566563326 BddDFMdEsttdIsttsFSvsRt "Blended Dual Fuel Mode Estimated Instantaneous Fuel Savings Rate: Estimated instantaneous fuel savings rate while operating in blended dual fuel mode.  This is in comparison to operating in diesel only mode.";
CM_ BO_ 2566563582 "Duel Fuel Mode 2";
CM_ SG_ 2566563582 BlnddDlFlMdTtlDslFlDspldGssFl "Blended Dual Fuel Mode Total Diesel Fuel Displaced by Gaseous Fuel: Accumulated total amount of diesel fuel displaced on blended dual fuel applications.";
CM_ SG_ 2566563582 BlnddDlFlMdTtlDslFlDmnd "Blended Dual Fuel Mode Total Diesel Fuel Demand: Accumulated amount of liquid fuel that would have been used during engine operation, including actual diesel fuel used and the diesel fuel that was displaced by gaseous fuel.";
CM_ BO_ 2566563838 "Dual Fuel Mode 1";
CM_ SG_ 2566563838 BlnddDlFlMdTtlDslFlUsd "Blended Dual Fuel Mode Total Diesel Fuel Used: Accumulated total amount of diesel fuel used by a dual fuel engine while fuel is being blended.Use SPN 7597 for accumulated amount of actual diesel fuel used and the diesel fuel that was displaced by gas...";
CM_ SG_ 2566563838 BlnddDlFlMdTtlDslFlPrntDspld "Blended Dual Fuel Mode Total Diesel Fuel Percent Displaced: Percent of total quantity of diesel fuel that was displaced by an engine when gaseous fuel was substituted for a portion of diesel fuel in blended dual fuel mode. This is calculated using to...";
CM_ SG_ 2566563838 BlnddDlFlMdPrntTmAtv "Blended Dual Fuel Mode Percent Time Active: The percentage of accumulated hours the engine has run in blended dual fuel mode.This value is calculated by dividing dual fuel active time by engine run time * 100.";
CM_ SG_ 2566563838 BlnddDlFlMdDslFlPrntDspld "Blended Dual Fuel Mode Diesel Fuel Percent Displaced: Percent of total diesel fuel displaced in a blended dual fuel application.0% = No diesel fuel displaced. 100% = All amount of diesel fuel is being displaced.";
CM_ SG_ 2566563838 BddDFMdEsttdIsttsDsSvsRtPt "Blended Dual Fuel Mode Estimated Instantaneous Diesel Savings Rate Percentage: Estimated instantaneous diesel fuel savings rate percentage while operating in blended dual fuel mode.This value is calculated by dividing the Blended Dual Fuel Mode Estim...";
CM_ BO_ 2566564094 "Transmission 1 History";
CM_ SG_ 2566564094 Trnsmssn1TtlHrsfOprtn "Transmission 1 Total Hours of Operation: Accumulated time of transmission operation.";
CM_ SG_ 2566564094 Trnsmssn1TtlOtptShftRvltns "Transmission 1 Total Output Shaft Revolutions: Accumulated number of transmission 1 output shaft revolutions during its operation.";
CM_ SG_ 2566564094 Trnsmssn1OprtnTmSnRld "Transmission 1 Operation Time Since Rebuild: The estimated or actual amount of transmission 1 operation time since the last transmission rebuild.";
CM_ BO_ 2566564350 "Transmission Shaft Twist Information";
CM_ SG_ 2566564350 Trnsmssn1InptShftPkTwst "Transmission 1 Input Shaft Peak Twist: Indicates the maximum dynamic twist angle observed during a sample period for the transmission 1 input shaft. The broadcast value is always the largest twist displacement (regardless of positive or negative dire...";
CM_ SG_ 2566564350 Trnsmssn1OtptShftPkTwst "Transmission 1 Output Shaft Peak Twist: Indicates the maximum dynamic twist angle observed during a sample period for the transmission 1 output shaft. The broadcast value is always the largest twist displacement (regardless of positive or negative di...";
CM_ SG_ 2566564350 Trnsmssn1IntrmdtShftPkTwst "Transmission 1 Intermediate Shaft Peak Twist: Indicates the maximum dynamic twist angle observed during a sample period for the first instance of a transmission 1 intermediate shaft, as desinated by the transmission manufacturer. The broadcast value ...";
CM_ BO_ 2566564606 "Electronic Auxiliary Transmission Controller 2";
CM_ SG_ 2566564606 AxlrTrnsmssnSltdGr "Auxiliary Transmission Selected Gear: The gear that the auxiliary transmission will attempt to achieve during the current shift if a shift is in progress, or the next shift if one is pending (i.e., waiting for torque reduction to initiate the shift)....";
CM_ SG_ 2566564606 AxlrTrnsmssnCrrntGr "Auxiliary Transmission Current Gear: The gear currently engaged in the auxiliary transmission or the last gear engaged while the auxiliary transmission is in the process of shifting to the new or selected gear.  Transitions toward a destination gear ...";
BA_DEF_ SG_  "SPN" INT 0 524287;
BA_DEF_ BO_  "VFrameFormat" ENUM  "StandardCAN","ExtendedCAN","reserved","J1939PG";
BA_DEF_DEF_  "SPN" 0;
BA_DEF_DEF_  "VFrameFormat" "J1939PG";
BA_ "SPN" SG_ 2364683006 HVESP9DshrgPwrLmtDtSttfChrg 14334;
BA_ "SPN" SG_ 2364683006 HVESP9DshrgPwrLmtDtBttrTmprtr 14335;
BA_ "SPN" SG_ 2364683006 HVESP9DsPwLtDtBttDstCdt 14336;
BA_ "SPN" SG_ 2364683006 HVESP9DshrgPwrLmtDtBttrrCllVltg 14337;
BA_ "SPN" SG_ 2364683006 HVESP9DshrgPwrLmtDtBttrCrrnt 14338;
BA_ "SPN" SG_ 2364683006 HVESP9DshrgPwrLmtDtnUndfndCs 14339;
BA_ "SPN" SG_ 2364683006 HVESP9ChrgPwrLmtDtSttfChrg 14340;
BA_ "SPN" SG_ 2364683006 HVESP9ChrgPwrLmtDtBttrTmprtr 14341;
BA_ "SPN" SG_ 2364683006 HVESP9CPwLtDtBttDstCdt 14342;
BA_ "SPN" SG_ 2364683006 HVESP9ChrgPwrLmtDtBttrrCllVltg 14343;
BA_ "SPN" SG_ 2364683006 HVESP9ChrgPwrLmtDtBttrCrrnt 14344;
BA_ "SPN" SG_ 2364683006 HVESP9ChrgPwrLmtDtnUndfndCs 14345;
BA_ "SPN" SG_ 2364683262 HVESP9AvailableDischargePower 14346;
BA_ "SPN" SG_ 2364683262 HVESP9AvailableChargePower 14347;
BA_ "SPN" SG_ 2364683262 HVESP9VoltageLevel 14348;
BA_ "SPN" SG_ 2364683262 HVESP9Current 14349;
BA_ "SPN" SG_ 2364683518 HVESP9FastUpdateStateofCharge 14350;
BA_ "SPN" SG_ 2364683518 HVESP9HighestCellVoltage 14351;
BA_ "SPN" SG_ 2364683518 HVESP9LowestCellVoltage 14352;
BA_ "SPN" SG_ 2364683518 HVESP9CllVltgDffrntlStts 14353;
BA_ "SPN" SG_ 2364683774 HVESP9HighestCellTemperature 14354;
BA_ "SPN" SG_ 2364683774 HVESP9LowestCellTemperature 14355;
BA_ "SPN" SG_ 2364683774 HVESP9AverageCellTemperature 14356;
BA_ "SPN" SG_ 2364683774 HVESP9CllTmprtrDffrntlStts 14357;
BA_ "SPN" SG_ 2364684030 HVESP9DischargeCapacity 14358;
BA_ "SPN" SG_ 2364684030 HVESP9ChargeCapacity 14359;
BA_ "SPN" SG_ 2364684030 HVESP9CellBalancingCount 14360;
BA_ "SPN" SG_ 2364684286 HVESP9DischargeCurrentLimit 14361;
BA_ "SPN" SG_ 2364684286 HVESP9ChargeCurrentLimit 14362;
BA_ "SPN" SG_ 2364684286 HVESP9LowestCellStateofCharge 14363;
BA_ "SPN" SG_ 2364684286 HVESP9HighestCellStateofCharge 14364;
BA_ "SPN" SG_ 2364684542 HVESP9BusVoltage 14365;
BA_ "SPN" SG_ 2364684542 HVESP9IgnitionVoltage 14366;
BA_ "SPN" SG_ 2364684542 HVESP9IntakeCoolantTemperature 14367;
BA_ "SPN" SG_ 2364684542 HVESP9OutletCoolantTemperature 14368;
BA_ "SPN" SG_ 2364684542 HVESP9ElectronicsTemperature 14369;
BA_ "SPN" SG_ 2364684542 HVESP9Temperature 14370;
BA_ "SPN" SG_ 2364684798 HVESP9HghVltgBsPstvCnttrStt 14371;
BA_ "SPN" SG_ 2364684798 HVESP9HghVltgBsNgtvCnttrStt 14372;
BA_ "SPN" SG_ 2364684798 HVESP9HghVltgBsDsnntFrwrnng 14373;
BA_ "SPN" SG_ 2364684798 HVESP9HghVltgBsPrChrgRlStt 14374;
BA_ "SPN" SG_ 2364684798 HVESP9CntrfPkCnttrStt 14375;
BA_ "SPN" SG_ 2364684798 HVESP9HghVltgBsAtvIsltnTstStts 14376;
BA_ "SPN" SG_ 2364684798 HVESP9HghVltgBsPssvIsltnTstStts 14377;
BA_ "SPN" SG_ 2364684798 HVESP9HVILStatus 14378;
BA_ "SPN" SG_ 2364684798 HVESP9InertiaSwitchStatus 14379;
BA_ "SPN" SG_ 2364684798 HVESP9StateofChargeStatus 14380;
BA_ "SPN" SG_ 2364684798 HVESP9CellBalanceStatus 14381;
BA_ "SPN" SG_ 2364684798 HVESP9CellBalancingActive 14382;
BA_ "SPN" SG_ 2364684798 HVESP9InternalChargerStatus 14383;
BA_ "SPN" SG_ 2364684798 HVESP9HghVltgBsCnntnStts 14384;
BA_ "SPN" SG_ 2364684798 HVESP9OperationalStatus 14385;
BA_ "SPN" SG_ 2364684798 HVESP9Status1Counter 14386;
BA_ "SPN" SG_ 2364684798 HVESP9Status1CRC 14387;
BA_ "SPN" SG_ 2364685054 HVESP9DischargeEnergyCapacity 14388;
BA_ "SPN" SG_ 2364685054 HVESP9ChargeEnergyCapacity 14389;
BA_ "SPN" SG_ 2364685054 HVESP9MaximumChargeVoltageLimit 14390;
BA_ "SPN" SG_ 2364685310 HVESP9Module1OperationalStatus 14391;
BA_ "SPN" SG_ 2364685310 HVESP9Module2OperationalStatus 14392;
BA_ "SPN" SG_ 2364685310 HVESP9Module3OperationalStatus 14393;
BA_ "SPN" SG_ 2364685310 HVESP9Module4OperationalStatus 14394;
BA_ "SPN" SG_ 2364685310 HVESP9Module5OperationalStatus 14395;
BA_ "SPN" SG_ 2364685310 HVESP9Module6OperationalStatus 14396;
BA_ "SPN" SG_ 2364685310 HVESP9Module7OperationalStatus 14397;
BA_ "SPN" SG_ 2364685310 HVESP9Module8OperationalStatus 14398;
BA_ "SPN" SG_ 2364685310 HVESP9Module9OperationalStatus 14399;
BA_ "SPN" SG_ 2364685310 HVESP9Module10OperationalStatus 14400;
BA_ "SPN" SG_ 2364685310 HVESP9Module11OperationalStatus 14401;
BA_ "SPN" SG_ 2364685310 HVESP9Module12OperationalStatus 14402;
BA_ "SPN" SG_ 2364685310 HVESP9Module13OperationalStatus 14403;
BA_ "SPN" SG_ 2364685310 HVESP9Module14OperationalStatus 14404;
BA_ "SPN" SG_ 2364685310 HVESP9Module15OperationalStatus 14405;
BA_ "SPN" SG_ 2364685310 HVESP9Module16OperationalStatus 14406;
BA_ "SPN" SG_ 2364685310 HVESP9Module17OperationalStatus 14407;
BA_ "SPN" SG_ 2364685310 HVESP9Module18OperationalStatus 14408;
BA_ "SPN" SG_ 2364685310 HVESP9Module19OperationalStatus 14409;
BA_ "SPN" SG_ 2364685310 HVESP9Module20OperationalStatus 14410;
BA_ "SPN" SG_ 2364685310 HVESP9Module21OperationalStatus 14411;
BA_ "SPN" SG_ 2364685310 HVESP9Module22OperationalStatus 14412;
BA_ "SPN" SG_ 2364685310 HVESP9Module23OperationalStatus 14413;
BA_ "SPN" SG_ 2364685310 HVESP9Module24OperationalStatus 14414;
BA_ "SPN" SG_ 2364685310 HVESP9Module25OperationalStatus 14415;
BA_ "SPN" SG_ 2364685310 HVESP9Module26OperationalStatus 14416;
BA_ "SPN" SG_ 2364685310 HVESP9Module27OperationalStatus 14417;
BA_ "SPN" SG_ 2364685310 HVESP9Module28OperationalStatus 14418;
BA_ "SPN" SG_ 2364685310 HVESP9Module29OperationalStatus 14419;
BA_ "SPN" SG_ 2364685310 HVESP9Module30OperationalStatus 14420;
BA_ "SPN" SG_ 2364685310 HVESP9Module31OperationalStatus 14421;
BA_ "SPN" SG_ 2364685310 HVESP9Module32OperationalStatus 14422;
BA_ "SPN" SG_ 2364685566 HVESP9ThrmlMngmntSstmSLIInptPwr 14423;
BA_ "SPN" SG_ 2364685566 HVESP9TMtSstHVtIptPw 14424;
BA_ "SPN" SG_ 2364685566 HVESP9ThrmlMngmntSstmCmprssrSpd 14425;
BA_ "SPN" SG_ 2364685566 HVESP9ThrmlMngmntSstmRltvHmdt 14426;
BA_ "SPN" SG_ 2364685566 HVESP9ThrmlMngmntSstmHtrStts 14427;
BA_ "SPN" SG_ 2364685566 HVESP9ThrmlMngmntSstmHVILStts 14428;
BA_ "SPN" SG_ 2364685566 HVESP9ThrmlMngmntSstmMd 14429;
BA_ "SPN" SG_ 2364685566 HVESP9ThrmlMngmntSstmClntLvl 14430;
BA_ "SPN" SG_ 2364685822 HVESP9HghstCllVltgMdlNmr 14431;
BA_ "SPN" SG_ 2364685822 HVESP9HghstCllVltgCllNmr 14432;
BA_ "SPN" SG_ 2364685822 HVESP9LwstCllVltgMdlNmr 14433;
BA_ "SPN" SG_ 2364685822 HVESP9LwstCllVltgCllNmr 14434;
BA_ "SPN" SG_ 2364685822 HVESP9AverageCellVoltage 14435;
BA_ "SPN" SG_ 2364686078 HVESP9HghstCllTmprtrMdlNmr 14436;
BA_ "SPN" SG_ 2364686078 HVESP9HghstCllTmprtrCllNmr 14437;
BA_ "SPN" SG_ 2364686078 HVESP9LwstCllTmprtrMdlNmr 14438;
BA_ "SPN" SG_ 2364686078 HVESP9LwstCllTmprtrCllNmr 14439;
BA_ "SPN" SG_ 2364686334 HVESP9HghstCllSttfChrgMdlNmr 14440;
BA_ "SPN" SG_ 2364686334 HVESP9HghstCllSttfChrgCllNmr 14441;
BA_ "SPN" SG_ 2364686334 HVESP9LwstCllSttfChrgMdlNmr 14442;
BA_ "SPN" SG_ 2364686334 HVESP9LwstCllSttfChrgCllNmr 14443;
BA_ "SPN" SG_ 2364686334 HVESP9HghVltgBsAtvIsltnTstRslts 14444;
BA_ "SPN" SG_ 2364686334 HVESP9HVtBsPssvIstTstRsts 14445;
BA_ "SPN" SG_ 2364686590 HVESP9BsVltgNgtvtChsssGrndVltg 14446;
BA_ "SPN" SG_ 2364686590 HVESP9VltgLvlNgtvtChsssGrndVltg 14447;
BA_ "SPN" SG_ 2364686590 HVESP9ActualChargeRate 14448;
BA_ "SPN" SG_ 2364686846 HVESP10DshrgPwrLmtDtSttfChrg 14477;
BA_ "SPN" SG_ 2364686846 HVESP10DshrgPwrLmtDtBttrTmprtr 14478;
BA_ "SPN" SG_ 2364686846 HVESP10DsPwLtDtBttDstCdt 14479;
BA_ "SPN" SG_ 2364686846 HVESP10DsPwLtDtBttCVt 14480;
BA_ "SPN" SG_ 2364686846 HVESP10DshrgPwrLmtDtBttrCrrnt 14481;
BA_ "SPN" SG_ 2364686846 HVESP10DshrgPwrLmtDtnUndfndCs 14482;
BA_ "SPN" SG_ 2364686846 HVESP10ChrgPwrLmtDtSttfChrg 14483;
BA_ "SPN" SG_ 2364686846 HVESP10ChrgPwrLmtDtBttrTmprtr 14484;
BA_ "SPN" SG_ 2364686846 HVESP10CPwLtDtBttDstCdt 14485;
BA_ "SPN" SG_ 2364686846 HVESP10ChrgPwrLmtDtBttrrCllVltg 14486;
BA_ "SPN" SG_ 2364686846 HVESP10ChrgPwrLmtDtBttrCrrnt 14487;
BA_ "SPN" SG_ 2364686846 HVESP10ChrgPwrLmtDtnUndfndCs 14488;
BA_ "SPN" SG_ 2364687102 HVESP10AvailableDischargePower 14489;
BA_ "SPN" SG_ 2364687102 HVESP10AvailableChargePower 14490;
BA_ "SPN" SG_ 2364687102 HVESP10VoltageLevel 14491;
BA_ "SPN" SG_ 2364687102 HVESP10Current 14492;
BA_ "SPN" SG_ 2364687358 HVESP10FastUpdateStateofCharge 14493;
BA_ "SPN" SG_ 2364687358 HVESP10HighestCellVoltage 14494;
BA_ "SPN" SG_ 2364687358 HVESP10LowestCellVoltage 14495;
BA_ "SPN" SG_ 2364687358 HVESP10CllVltgDffrntlStts 14496;
BA_ "SPN" SG_ 2364687614 HVESP10HighestCellTemperature 14497;
BA_ "SPN" SG_ 2364687614 HVESP10LowestCellTemperature 14498;
BA_ "SPN" SG_ 2364687614 HVESP10AverageCellTemperature 14499;
BA_ "SPN" SG_ 2364687614 HVESP10CllTmprtrDffrntlStts 14500;
BA_ "SPN" SG_ 2364687870 HVESP10DischargeCapacity 14501;
BA_ "SPN" SG_ 2364687870 HVESP10ChargeCapacity 14502;
BA_ "SPN" SG_ 2364687870 HVESP10CellBalancingCount 14503;
BA_ "SPN" SG_ 2364688126 HVESP10DischargeCurrentLimit 14504;
BA_ "SPN" SG_ 2364688126 HVESP10ChargeCurrentLimit 14505;
BA_ "SPN" SG_ 2364688126 HVESP10LowestCellStateofCharge 14506;
BA_ "SPN" SG_ 2364688126 HVESP10HighestCellStateofCharge 14507;
BA_ "SPN" SG_ 2364688382 HVESP10BusVoltage 14508;
BA_ "SPN" SG_ 2364688382 HVESP10IgnitionVoltage 14509;
BA_ "SPN" SG_ 2364688382 HVESP10IntakeCoolantTemperature 14510;
BA_ "SPN" SG_ 2364688382 HVESP10OutletCoolantTemperature 14511;
BA_ "SPN" SG_ 2364688382 HVESP10ElectronicsTemperature 14512;
BA_ "SPN" SG_ 2364688382 HVESP10Temperature 14513;
BA_ "SPN" SG_ 2364688638 HVESP10HghVltgBsPstvCnttrStt 14514;
BA_ "SPN" SG_ 2364688638 HVESP10HghVltgBsNgtvCnttrStt 14515;
BA_ "SPN" SG_ 2364688638 HVESP10HghVltgBsDsnntFrwrnng 14516;
BA_ "SPN" SG_ 2364688638 HVESP10HghVltgBsPrChrgRlStt 14517;
BA_ "SPN" SG_ 2364688638 HVESP10CntrfPkCnttrStt 14518;
BA_ "SPN" SG_ 2364688638 HVESP10HghVltgBsAtvIsltnTstStts 14519;
BA_ "SPN" SG_ 2364688638 HVESP10HVtBsPssvIstTstStts 14520;
BA_ "SPN" SG_ 2364688638 HVESP10HVILStatus 14521;
BA_ "SPN" SG_ 2364688638 HVESP10InertiaSwitchStatus 14522;
BA_ "SPN" SG_ 2364688638 HVESP10StateofChargeStatus 14523;
BA_ "SPN" SG_ 2364688638 HVESP10CellBalanceStatus 14524;
BA_ "SPN" SG_ 2364688638 HVESP10CellBalancingActive 14525;
BA_ "SPN" SG_ 2364688638 HVESP10InternalChargerStatus 14526;
BA_ "SPN" SG_ 2364688638 HVESP10HghVltgBsCnntnStts 14527;
BA_ "SPN" SG_ 2364688638 HVESP10OperationalStatus 14528;
BA_ "SPN" SG_ 2364688638 HVESP10Status1Counter 14529;
BA_ "SPN" SG_ 2364688638 HVESP10Status1CRC 14530;
BA_ "SPN" SG_ 2364688894 HVESP10DischargeEnergyCapacity 14531;
BA_ "SPN" SG_ 2364688894 HVESP10ChargeEnergyCapacity 14532;
BA_ "SPN" SG_ 2364688894 HVESP10MxmmChrgVltgLmt 14533;
BA_ "SPN" SG_ 2364689150 HVESP10Module1OperationalStatus 14534;
BA_ "SPN" SG_ 2364689150 HVESP10Module2OperationalStatus 14535;
BA_ "SPN" SG_ 2364689150 HVESP10Module3OperationalStatus 14536;
BA_ "SPN" SG_ 2364689150 HVESP10Module4OperationalStatus 14537;
BA_ "SPN" SG_ 2364689150 HVESP10Module5OperationalStatus 14538;
BA_ "SPN" SG_ 2364689150 HVESP10Module6OperationalStatus 14539;
BA_ "SPN" SG_ 2364689150 HVESP10Module7OperationalStatus 14540;
BA_ "SPN" SG_ 2364689150 HVESP10Module8OperationalStatus 14541;
BA_ "SPN" SG_ 2364689150 HVESP10Module9OperationalStatus 14542;
BA_ "SPN" SG_ 2364689150 HVESP10Mdl10OprtnlStts 14543;
BA_ "SPN" SG_ 2364689150 HVESP10Mdl11OprtnlStts 14544;
BA_ "SPN" SG_ 2364689150 HVESP10Mdl12OprtnlStts 14545;
BA_ "SPN" SG_ 2364689150 HVESP10Mdl13OprtnlStts 14546;
BA_ "SPN" SG_ 2364689150 HVESP10Mdl14OprtnlStts 14547;
BA_ "SPN" SG_ 2364689150 HVESP10Mdl15OprtnlStts 14548;
BA_ "SPN" SG_ 2364689150 HVESP10Mdl16OprtnlStts 14549;
BA_ "SPN" SG_ 2364689150 HVESP10Mdl17OprtnlStts 14550;
BA_ "SPN" SG_ 2364689150 HVESP10Mdl18OprtnlStts 14551;
BA_ "SPN" SG_ 2364689150 HVESP10Mdl19OprtnlStts 14552;
BA_ "SPN" SG_ 2364689150 HVESP10Mdl20OprtnlStts 14553;
BA_ "SPN" SG_ 2364689150 HVESP10Mdl21OprtnlStts 14554;
BA_ "SPN" SG_ 2364689150 HVESP10Mdl22OprtnlStts 14555;
BA_ "SPN" SG_ 2364689150 HVESP10Mdl23OprtnlStts 14556;
BA_ "SPN" SG_ 2364689150 HVESP10Mdl24OprtnlStts 14557;
BA_ "SPN" SG_ 2364689150 HVESP10Mdl25OprtnlStts 14558;
BA_ "SPN" SG_ 2364689150 HVESP10Mdl26OprtnlStts 14559;
BA_ "SPN" SG_ 2364689150 HVESP10Mdl27OprtnlStts 14560;
BA_ "SPN" SG_ 2364689150 HVESP10Mdl28OprtnlStts 14561;
BA_ "SPN" SG_ 2364689150 HVESP10Mdl29OprtnlStts 14562;
BA_ "SPN" SG_ 2364689150 HVESP10Mdl30OprtnlStts 14563;
BA_ "SPN" SG_ 2364689150 HVESP10Mdl31OprtnlStts 14564;
BA_ "SPN" SG_ 2364689150 HVESP10Mdl32OprtnlStts 14565;
BA_ "SPN" SG_ 2364689406 HVESP10TMtSstSLIIptPw 14566;
BA_ "SPN" SG_ 2364689406 HVESP10TMtSstHVtIptPw 14567;
BA_ "SPN" SG_ 2364689406 HVESP10TMtSstCpssSpd 14568;
BA_ "SPN" SG_ 2364689406 HVESP10ThrmlMngmntSstmRltvHmdt 14569;
BA_ "SPN" SG_ 2364689406 HVESP10ThrmlMngmntSstmHtrStts 14570;
BA_ "SPN" SG_ 2364689406 HVESP10ThrmlMngmntSstmHVILStts 14571;
BA_ "SPN" SG_ 2364689406 HVESP10ThrmlMngmntSstmMd 14572;
BA_ "SPN" SG_ 2364689406 HVESP10ThrmlMngmntSstmClntLvl 14573;
BA_ "SPN" SG_ 2364689662 HVESP10HghstCllVltgMdlNmr 14574;
BA_ "SPN" SG_ 2364689662 HVESP10HghstCllVltgCllNmr 14575;
BA_ "SPN" SG_ 2364689662 HVESP10LwstCllVltgMdlNmr 14576;
BA_ "SPN" SG_ 2364689662 HVESP10LwstCllVltgCllNmr 14577;
BA_ "SPN" SG_ 2364689662 HVESP10AverageCellVoltage 14578;
BA_ "SPN" SG_ 2364689918 HVESP10HghstCllTmprtrMdlNmr 14579;
BA_ "SPN" SG_ 2364689918 HVESP10HghstCllTmprtrCllNmr 14580;
BA_ "SPN" SG_ 2364689918 HVESP10LwstCllTmprtrMdlNmr 14581;
BA_ "SPN" SG_ 2364689918 HVESP10LwstCllTmprtrCllNmr 14582;
BA_ "SPN" SG_ 2364690174 HVESP10HghstCllSttfChrgMdlNmr 14583;
BA_ "SPN" SG_ 2364690174 HVESP10HghstCllSttfChrgCllNmr 14584;
BA_ "SPN" SG_ 2364690174 HVESP10LwstCllSttfChrgMdlNmr 14585;
BA_ "SPN" SG_ 2364690174 HVESP10LwstCllSttfChrgCllNmr 14586;
BA_ "SPN" SG_ 2364690174 HVESP10HVtBsAtvIstTstRsts 14587;
BA_ "SPN" SG_ 2364690174 HVESP10HVtBsPssvIstTstRsts 14588;
BA_ "SPN" SG_ 2364690430 HVESP10BsVltgNgtvtChsssGrndVltg 14589;
BA_ "SPN" SG_ 2364690430 HVESP10VtLvNtvtCsssGdVt 14590;
BA_ "SPN" SG_ 2364690430 HVESP10ActualChargeRate 14591;
BA_ "SPN" SG_ 2566564862 HVESP10NominalVoltage 14600;
BA_ "SPN" SG_ 2566564862 HVESP10RmmnddMnmmOprtngVltg 14601;
BA_ "SPN" SG_ 2566564862 HVESP10RmmnddMxmmOprtngVltg 14602;
BA_ "SPN" SG_ 2566564862 HVESP10RmmnddMnmmSttOfChrg 14603;
BA_ "SPN" SG_ 2566564862 HVESP10RmmnddMxmmSttOfChrg 14604;
BA_ "SPN" SG_ 2566564862 HVESP10RmmnddMxmmOprtngTmprtr 14605;
BA_ "SPN" SG_ 2566564862 HVESP10RmmnddMnmmOprtngTmprtr 14606;
BA_ "SPN" SG_ 2566564862 HVESP10CellMaximumVoltageLimit 14607;
BA_ "SPN" SG_ 2566564862 HVESP10CellMinimumVoltageLimit 14608;
BA_ "SPN" SG_ 2633673982 HVESP10StateofHealth 14592;
BA_ "SPN" SG_ 2633673982 HVESP10CnttrOpnUndrLdCnt 14593;
BA_ "SPN" SG_ 2633673982 HVESP10TotalEnergyThroughput 14594;
BA_ "SPN" SG_ 2633673982 HVESP10TotalAccumulatedCharge 14595;
BA_ "SPN" SG_ 2633673982 HVESP10TotalLifetimeEnergyInput 14596;
BA_ "SPN" SG_ 2633673982 HVESP10TtlLftmEnrgOtpt 14597;
BA_ "SPN" SG_ 2566565374 HVESP9NominalVoltage 14457;
BA_ "SPN" SG_ 2566565374 HVESP9RmmnddMnmmOprtngVltg 14458;
BA_ "SPN" SG_ 2566565374 HVESP9RmmnddMxmmOprtngVltg 14459;
BA_ "SPN" SG_ 2566565374 HVESP9RmmnddMnmmSttOfChrg 14460;
BA_ "SPN" SG_ 2566565374 HVESP9RmmnddMxmmSttOfChrg 14461;
BA_ "SPN" SG_ 2566565374 HVESP9RmmnddMxmmOprtngTmprtr 14462;
BA_ "SPN" SG_ 2566565374 HVESP9RmmnddMnmmOprtngTmprtr 14463;
BA_ "SPN" SG_ 2566565374 HVESP9CellMaximumVoltageLimit 14464;
BA_ "SPN" SG_ 2566565374 HVESP9CellMinimumVoltageLimit 14465;
BA_ "SPN" SG_ 2633674494 HVESP9StateofHealth 14449;
BA_ "SPN" SG_ 2633674494 HVESP9CnttrOpnUndrLdCnt 14450;
BA_ "SPN" SG_ 2633674494 HVESP9TotalEnergyThroughput 14451;
BA_ "SPN" SG_ 2633674494 HVESP9TotalAccumulatedCharge 14452;
BA_ "SPN" SG_ 2633674494 HVESP9TotalLifetimeEnergyInput 14453;
BA_ "SPN" SG_ 2633674494 HVESP9TotalLifetimeEnergyOutput 14454;
BA_ "SPN" SG_ 2566565886 HVESP8NominalVoltage 14314;
BA_ "SPN" SG_ 2566565886 HVESP8RmmnddMnmmOprtngVltg 14315;
BA_ "SPN" SG_ 2566565886 HVESP8RmmnddMxmmOprtngVltg 14316;
BA_ "SPN" SG_ 2566565886 HVESP8RmmnddMnmmSttOfChrg 14317;
BA_ "SPN" SG_ 2566565886 HVESP8RmmnddMxmmSttOfChrg 14318;
BA_ "SPN" SG_ 2566565886 HVESP8RmmnddMxmmOprtngTmprtr 14319;
BA_ "SPN" SG_ 2566565886 HVESP8RmmnddMnmmOprtngTmprtr 14320;
BA_ "SPN" SG_ 2566565886 HVESP8CellMaximumVoltageLimit 14321;
BA_ "SPN" SG_ 2566565886 HVESP8CellMinimumVoltageLimit 14322;
BA_ "SPN" SG_ 2633675006 HVESP8StateofHealth 14306;
BA_ "SPN" SG_ 2633675006 HVESP8CnttrOpnUndrLdCnt 14307;
BA_ "SPN" SG_ 2633675006 HVESP8TotalEnergyThroughput 14308;
BA_ "SPN" SG_ 2633675006 HVESP8TotalAccumulatedCharge 14309;
BA_ "SPN" SG_ 2633675006 HVESP8TotalLifetimeEnergyInput 14310;
BA_ "SPN" SG_ 2633675006 HVESP8TotalLifetimeEnergyOutput 14311;
BA_ "SPN" SG_ 2566566398 HVESP7NominalVoltage 14171;
BA_ "SPN" SG_ 2566566398 HVESP7RmmnddMnmmOprtngVltg 14172;
BA_ "SPN" SG_ 2566566398 HVESP7RmmnddMxmmOprtngVltg 14173;
BA_ "SPN" SG_ 2566566398 HVESP7RmmnddMnmmSttOfChrg 14174;
BA_ "SPN" SG_ 2566566398 HVESP7RmmnddMxmmSttOfChrg 14175;
BA_ "SPN" SG_ 2566566398 HVESP7RmmnddMxmmOprtngTmprtr 14176;
BA_ "SPN" SG_ 2566566398 HVESP7RmmnddMnmmOprtngTmprtr 14177;
BA_ "SPN" SG_ 2566566398 HVESP7CellMaximumVoltageLimit 14178;
BA_ "SPN" SG_ 2566566398 HVESP7CellMinimumVoltageLimit 14179;
BA_ "SPN" SG_ 2633675518 HVESP7StateofHealth 14163;
BA_ "SPN" SG_ 2633675518 HVESP7CnttrOpnUndrLdCnt 14164;
BA_ "SPN" SG_ 2633675518 HVESP7TotalEnergyThroughput 14165;
BA_ "SPN" SG_ 2633675518 HVESP7TotalAccumulatedCharge 14166;
BA_ "SPN" SG_ 2633675518 HVESP7TotalLifetimeEnergyInput 14167;
BA_ "SPN" SG_ 2633675518 HVESP7TotalLifetimeEnergyOutput 14168;
BA_ "SPN" SG_ 2566567166 HybridDCChargingVoltageMaximum 13155;
BA_ "SPN" SG_ 2566567166 HybridDCChargingCurrentMaximum 13156;
BA_ "SPN" SG_ 2566567166 HybridDCChargingPowerMaximum 13157;
BA_ "SPN" SG_ 2566567166 HrdrqstdEnrgTrnsfrTp 13158;
BA_ "SPN" SG_ 2566567422 EVSEDCChargingVoltageMaximum 13159;
BA_ "SPN" SG_ 2566567422 EVSEDCChargingCurrentMaximum 13160;
BA_ "SPN" SG_ 2566567422 EVSEDCChargingPowerMaximum 13161;
BA_ "SPN" SG_ 2566567422 EVSESpprtdEnrgTrnsfrTps 13162;
BA_ "SPN" SG_ 2566567678 EVSEDCChargingVoltageMinimum 13163;
BA_ "SPN" SG_ 2566567678 EVSEDCChargingCurrentMinimum 13164;
BA_ "SPN" SG_ 2566567678 EVSEPeakCurrentRipple 13165;
BA_ "SPN" SG_ 2566567678 EVSECurrentRegulationTolerance 13166;
BA_ "SPN" SG_ 2566567934 DCChargingTargetCRC 13167;
BA_ "SPN" SG_ 2566567934 DCChargingTargetSequenceCounter 13168;
BA_ "SPN" SG_ 2566567934 DCTargetChargingVoltage 13169;
BA_ "SPN" SG_ 2566567934 DCTargetChargingCurrent 13170;
BA_ "SPN" SG_ 2566568190 DCChargingState 13171;
BA_ "SPN" SG_ 2566568190 EVSEPresentDCChargingVoltage 13172;
BA_ "SPN" SG_ 2566568190 EVSEPresentDCChargingCurrent 13173;
BA_ "SPN" SG_ 2566568190 EVSEVoltageLimitAchieved 13174;
BA_ "SPN" SG_ 2566568190 EVSECurrentLimitAchieved 13175;
BA_ "SPN" SG_ 2566568190 EVSEPowerLimitAchieved 13176;
BA_ "SPN" SG_ 2566568190 EVSEStatus 13177;
BA_ "SPN" SG_ 2566568446 HybridDCInletContactor1Command 13178;
BA_ "SPN" SG_ 2566568702 HybridDCContactorInputVoltage 13179;
BA_ "SPN" SG_ 2566568702 HybridDCChargingBusVoltage 13180;
BA_ "SPN" SG_ 2566568702 HybridDCInletContactor1State 13181;
BA_ "SPN" SG_ 2566568958 TrnsmssnOlTmprtrHghLmpCmmnd 13116;
BA_ "SPN" SG_ 2566568958 TrnsmssnOlPrssrLwLmpCmmnd 13117;
BA_ "SPN" SG_ 2566569214 TrnsmssnOlTmprtrHghLmpDt 13129;
BA_ "SPN" SG_ 2566569214 TrnsmssnOlPrssrLwLmpDt 13130;
BA_ "SPN" SG_ 2566569470 MtrGnrtr1TtlEnrgCnsmd 13081;
BA_ "SPN" SG_ 2566569470 MtrGnrtr1TtlEnrgGnrtd 13082;
BA_ "SPN" SG_ 2566569470 MtrGnrtr1TtlChrgCnsmd 13083;
BA_ "SPN" SG_ 2566569470 MtrGnrtr1TtlChrgGnrtd 13084;
BA_ "SPN" SG_ 2566569726 MtrGnrtr2TtlEnrgCnsmd 13085;
BA_ "SPN" SG_ 2566569726 MtrGnrtr2TtlEnrgGnrtd 13086;
BA_ "SPN" SG_ 2566569726 MtrGnrtr2TtlChrgCnsmd 13087;
BA_ "SPN" SG_ 2566569726 MtrGnrtr2TtlChrgGnrtd 13088;
BA_ "SPN" SG_ 2566569982 MtrGnrtr3TtlEnrgCnsmd 13089;
BA_ "SPN" SG_ 2566569982 MtrGnrtr3TtlEnrgGnrtd 13090;
BA_ "SPN" SG_ 2566569982 MtrGnrtr3TtlChrgCnsmd 13091;
BA_ "SPN" SG_ 2566569982 MtrGnrtr3TtlChrgGnrtd 13092;
BA_ "SPN" SG_ 2566570238 MtrGnrtr4TtlEnrgCnsmd 13093;
BA_ "SPN" SG_ 2566570238 MtrGnrtr4TtlEnrgGnrtd 13094;
BA_ "SPN" SG_ 2566570238 MtrGnrtr4TtlChrgCnsmd 13095;
BA_ "SPN" SG_ 2566570238 MtrGnrtr4TtlChrgGnrtd 13096;
BA_ "SPN" SG_ 2566570494 MtrGnrtr5TtlEnrgCnsmd 13097;
BA_ "SPN" SG_ 2566570494 MtrGnrtr5TtlEnrgGnrtd 13098;
BA_ "SPN" SG_ 2566570494 MtrGnrtr5TtlChrgCnsmd 13099;
BA_ "SPN" SG_ 2566570494 MtrGnrtr5TtlChrgGnrtd 13100;
BA_ "SPN" SG_ 2566570750 MtrGnrtr6TtlEnrgCnsmd 13101;
BA_ "SPN" SG_ 2566570750 MtrGnrtr6TtlEnrgGnrtd 13102;
BA_ "SPN" SG_ 2566570750 MtrGnrtr6TtlChrgCnsmd 13103;
BA_ "SPN" SG_ 2566570750 MtrGnrtr6TtlChrgGnrtd 13104;
BA_ "SPN" SG_ 2566571006 AirDryerCartridgeLifeRemaining 13073;
BA_ "SPN" SG_ 2566571006 AirSuspensionSupplyPressure2 13132;
BA_ "SPN" SG_ 2566571262 EVSENmnlRMSvltgLntNtrl 13006;
BA_ "SPN" SG_ 2566571262 EVSENominalRMSvoltageLinetoLine 13007;
BA_ "SPN" SG_ 2566571262 EVSENominalSupplyFrequency 13008;
BA_ "SPN" SG_ 2566571518 HVESSChargerRMScurrentL1 13009;
BA_ "SPN" SG_ 2566571518 HVESSChargerRMScurrentL2 13010;
BA_ "SPN" SG_ 2566571518 HVESSChargerRMScurrentL3 13011;
BA_ "SPN" SG_ 2566571518 HVESSChargerNeutralRMScurrent 13012;
BA_ "SPN" SG_ 2499462910 RtrdrRdSpdDlrtSwth 12988;
BA_ "SPN" SG_ 2499462910 RtrdrRdSpdAlrtSwth 12989;
BA_ "SPN" SG_ 2566572286 TransmissionClutch1Temperature 5939;
BA_ "SPN" SG_ 2566572286 TrnsmssnClth1OvrhtIndtr 12965;
BA_ "SPN" SG_ 2499464702 Aftrtrtmnt1SCROtltAsltPrssr 11773;
BA_ "SPN" SG_ 2499464702 Aftrtrtmnt1SCROtltPrssr 11775;
BA_ "SPN" SG_ 2566573822 TrnsmssnPTOGrxOtptShftSpd 12960;
BA_ "SPN" SG_ 2566573822 TransmissionPTOGearboxStatus 12961;
BA_ "SPN" SG_ 2364690686 AxlrTrnsmssnOtptSpd 15204;
BA_ "SPN" SG_ 2566563326 BddDFMdEsttdIsttsFSvsRt 15231;
BA_ "SPN" SG_ 2566563582 BlnddDlFlMdTtlDslFlDspldGssFl 15229;
BA_ "SPN" SG_ 2566563582 BlnddDlFlMdTtlDslFlDmnd 15230;
BA_ "SPN" SG_ 2566563838 BlnddDlFlMdTtlDslFlUsd 15224;
BA_ "SPN" SG_ 2566563838 BlnddDlFlMdTtlDslFlPrntDspld 15225;
BA_ "SPN" SG_ 2566563838 BlnddDlFlMdPrntTmAtv 15226;
BA_ "SPN" SG_ 2566563838 BlnddDlFlMdDslFlPrntDspld 15227;
BA_ "SPN" SG_ 2566563838 BddDFMdEsttdIsttsDsSvsRtPt 15228;
BA_ "SPN" SG_ 2566564094 Trnsmssn1TtlHrsfOprtn 15221;
BA_ "SPN" SG_ 2566564094 Trnsmssn1TtlOtptShftRvltns 15222;
BA_ "SPN" SG_ 2566564094 Trnsmssn1OprtnTmSnRld 15223;
BA_ "SPN" SG_ 2566564350 Trnsmssn1InptShftPkTwst 15218;
BA_ "SPN" SG_ 2566564350 Trnsmssn1OtptShftPkTwst 15219;
BA_ "SPN" SG_ 2566564350 Trnsmssn1IntrmdtShftPkTwst 15220;
BA_ "SPN" SG_ 2566564606 AxlrTrnsmssnSltdGr 15202;
BA_ "SPN" SG_ 2566564606 AxlrTrnsmssnCrrntGr 15203;
